VERSION "dbc-export 1 2026.26.6.5"

NS_ :

BS_:

BU_: APP APS BMS CC CMP CMPD CP DAS DI DIF DIR EPBL EPBR EVSE FC GTW HCML HCMR HVP ICR PCS PCS2 PLG PM PMF PMR PTC SCCM SCM SCS SDCR TAS UMC V2G VC VCBATT VCBATT0 VCBATT1 VCBATT2 VCFRONT VCFRONT1 VCFRONT2 VCLEFT VCRIGHT VCSEAT2L VCSEAT2R VCSEC

BO_ 1000 EPBR_alertMatrix: 8 EPBR
 SG_ EPBR_matrixIndex M : 0|4@1+ (1,0) [0|15] "" Vector__XXX
 SG_ EPBR_a001_WatchdogReset m0 : 4|1@1+ (1,0) [0|1] "" Vector__XXX
 SG_ EPBR_a002_PowerLossReset m0 : 5|1@1+ (1,0) [0|1] "" Vector__XXX
 SG_ EPBR_a003_SWAssertion m0 : 6|1@1+ (1,0) [0|1] "" Vector__XXX
 SG_ EPBR_a005_CANTXError m0 : 8|1@1+ (1,0) [0|1] "" Vector__XXX
 SG_ EPBR_a006_CANTX_cyclicError m0 : 9|1@1+ (1,0) [0|1] "" Vector__XXX
 SG_ EPBR_a012_CPUReset m0 : 15|1@1+ (1,0) [0|1] "" Vector__XXX
 SG_ EPBR_a013_AlertManagerFault m0 : 16|1@1+ (1,0) [0|1] "" Vector__XXX
 SG_ EPBR_a015_NVMMError m0 : 18|1@1+ (1,0) [0|1] "" Vector__XXX
 SG_ EPBR_a016_NVMMRecordError m0 : 19|1@1+ (1,0) [0|1] "" Vector__XXX
 SG_ EPBR_a021_TaskSchedulerError m0 : 24|1@1+ (1,0) [0|1] "" Vector__XXX
 SG_ EPBR_a022_TaskInitError m0 : 25|1@1+ (1,0) [0|1] "" Vector__XXX
 SG_ EPBR_a029_CoreDump m0 : 32|1@1+ (1,0) [0|1] "" Vector__XXX
 SG_ EPBR_a030_ECULogUploadRequest m0 : 33|1@1+ (1,0) [0|1] "" Vector__XXX
 SG_ EPBR_a031_UDSActive m0 : 34|1@1+ (1,0) [0|1] "" Vector__XXX
 SG_ EPBR_a041_HighCPULoad m0 : 44|1@1+ (1,0) [0|1] "" Vector__XXX
 SG_ EPBR_a042_HighStackUsage m0 : 45|1@1+ (1,0) [0|1] "" Vector__XXX
 SG_ EPBR_a043_Task1msError m0 : 46|1@1+ (1,0) [0|1] "" Vector__XXX
 SG_ EPBR_a044_Task10msError m0 : 47|1@1+ (1,0) [0|1] "" Vector__XXX
 SG_ EPBR_a045_Task100msError m0 : 48|1@1+ (1,0) [0|1] "" Vector__XXX
 SG_ EPBR_a046_Task1000msError m0 : 49|1@1+ (1,0) [0|1] "" Vector__XXX
 SG_ EPBR_a057_HVP_MIA m0 : 60|1@1+ (1,0) [0|1] "" Vector__XXX
 SG_ EPBR_a058_inputRHighSyncDebug m0 : 61|1@1+ (1,0) [0|1] "" Vector__XXX
 SG_ EPBR_a059_inputResistanceHigh m0 : 62|1@1+ (1,0) [0|1] "" Vector__XXX
 SG_ EPBR_a060_engineeringBuild m0 : 63|1@1+ (1,0) [0|1] "" Vector__XXX
 SG_ EPBR_a061_XCPConnected m1 : 4|1@1+ (1,0) [0|1] "" Vector__XXX
 SG_ EPBR_a062_XCPWasConnected m1 : 5|1@1+ (1,0) [0|1] "" Vector__XXX
 SG_ EPBR_a063_SwitchFault m1 : 6|1@1+ (1,0) [0|1] "" Vector__XXX
 SG_ EPBR_a064_busSleepReqTimeout m1 : 7|1@1+ (1,0) [0|1] "" Vector__XXX
 SG_ EPBR_a081_APP_MIA m1 : 24|1@1+ (1,0) [0|1] "" Vector__XXX
 SG_ EPBR_a082_VCRIGHT_IPC_MIA m1 : 25|1@1+ (1,0) [0|1] "" Vector__XXX
 SG_ EPBR_a083_VCLEFT_IPC_MIA m1 : 26|1@1+ (1,0) [0|1] "" Vector__XXX
 SG_ EPBR_a084_TPMS_MIA m1 : 27|1@1+ (1,0) [0|1] "" Vector__XXX
 SG_ EPBR_a085_CCCM_MIA m1 : 28|1@1+ (1,0) [0|1] "" Vector__XXX
 SG_ EPBR_a086_VCBATT_MIA m1 : 29|1@1+ (1,0) [0|1] "" Vector__XXX
 SG_ EPBR_a087_DIREL_MIA m1 : 30|1@1+ (1,0) [0|1] "" Vector__XXX
 SG_ EPBR_a088_DIRER_MIA m1 : 31|1@1+ (1,0) [0|1] "" Vector__XXX
 SG_ EPBR_a089_IBST_MIA m1 : 32|1@1+ (1,0) [0|1] "" Vector__XXX
 SG_ EPBR_a090_APS_MIA m1 : 33|1@1+ (1,0) [0|1] "" Vector__XXX
 SG_ EPBR_a091_CMPD_MIA m1 : 34|1@1+ (1,0) [0|1] "" Vector__XXX
 SG_ EPBR_a092_VCSEATD_MIA m1 : 35|1@1+ (1,0) [0|1] "" Vector__XXX
 SG_ EPBR_a093_VCSEATP_MIA m1 : 36|1@1+ (1,0) [0|1] "" Vector__XXX
 SG_ EPBR_a094_EPAS3P_MIA m1 : 37|1@1+ (1,0) [0|1] "" Vector__XXX
 SG_ EPBR_a095_CHG_MIA m1 : 38|1@1+ (1,0) [0|1] "" Vector__XXX
 SG_ EPBR_a096_OCS1P_MIA m1 : 39|1@1+ (1,0) [0|1] "" Vector__XXX
 SG_ EPBR_a097_CMP_MIA m1 : 40|1@1+ (1,0) [0|1] "" Vector__XXX
 SG_ EPBR_a098_DIR_MIA m1 : 41|1@1+ (1,0) [0|1] "" Vector__XXX
 SG_ EPBR_a099_PARK_MIA m1 : 42|1@1+ (1,0) [0|1] "" Vector__XXX
 SG_ EPBR_a100_CANbus_MIA m1 : 43|1@1+ (1,0) [0|1] "" Vector__XXX
 SG_ EPBR_a101_PM_MIA m1 : 44|1@1+ (1,0) [0|1] "" Vector__XXX
 SG_ EPBR_a102_PTC_MIA m1 : 45|1@1+ (1,0) [0|1] "" Vector__XXX
 SG_ EPBR_a103_CP_MIA m1 : 46|1@1+ (1,0) [0|1] "" Vector__XXX
 SG_ EPBR_a104_DAS_MIA m1 : 47|1@1+ (1,0) [0|1] "" Vector__XXX
 SG_ EPBR_a105_TAS_MIA m1 : 48|1@1+ (1,0) [0|1] "" Vector__XXX
 SG_ EPBR_a106_PCS_MIA m1 : 49|1@1+ (1,0) [0|1] "" Vector__XXX
 SG_ EPBR_a107_BMS_MIA m1 : 50|1@1+ (1,0) [0|1] "" Vector__XXX
 SG_ EPBR_a108_DIF_MIA m1 : 51|1@1+ (1,0) [0|1] "" Vector__XXX
 SG_ EPBR_a109_RCM_MIA m1 : 52|1@1+ (1,0) [0|1] "" Vector__XXX
 SG_ EPBR_a110_GTW_MIA m1 : 53|1@1+ (1,0) [0|1] "" Vector__XXX
 SG_ EPBR_a111_EPBR_MIA m1 : 54|1@1+ (1,0) [0|1] "" Vector__XXX
 SG_ EPBR_a112_EPBL_MIA m1 : 55|1@1+ (1,0) [0|1] "" Vector__XXX
 SG_ EPBR_a113_UI_MIA m1 : 56|1@1+ (1,0) [0|1] "" Vector__XXX
 SG_ EPBR_a114_ESP_MIA m1 : 57|1@1+ (1,0) [0|1] "" Vector__XXX
 SG_ EPBR_a115_VCSEC_MIA m1 : 58|1@1+ (1,0) [0|1] "" Vector__XXX
 SG_ EPBR_a116_VCRIGHT_MIA m1 : 59|1@1+ (1,0) [0|1] "" Vector__XXX
 SG_ EPBR_a117_VCLEFT_MIA m1 : 60|1@1+ (1,0) [0|1] "" Vector__XXX
 SG_ EPBR_a118_VCFRONT_MIA m1 : 61|1@1+ (1,0) [0|1] "" Vector__XXX
 SG_ EPBR_a119_SCCM_MIA m1 : 62|1@1+ (1,0) [0|1] "" Vector__XXX
 SG_ EPBR_a120_DI_DRIVE_MIA m1 : 63|1@1+ (1,0) [0|1] "" Vector__XXX
 SG_ EPBR_a121_nDriveFault m2 : 4|1@1+ (1,0) [0|1] "" Vector__XXX
 SG_ EPBR_a122_Oc m2 : 5|1@1+ (1,0) [0|1] "" Vector__XXX
 SG_ EPBR_a123_Uc m2 : 6|1@1+ (1,0) [0|1] "" Vector__XXX
 SG_ EPBR_a124_calOutOfBounds m2 : 7|1@1+ (1,0) [0|1] "" Vector__XXX
 SG_ EPBR_a125_IdleVMismatch m2 : 8|1@1+ (1,0) [0|1] "" Vector__XXX
 SG_ EPBR_a126_MotorNVoltLow m2 : 9|1@1+ (1,0) [0|1] "" Vector__XXX
 SG_ EPBR_a127_MotorNVoltHigh m2 : 10|1@1+ (1,0) [0|1] "" Vector__XXX
 SG_ EPBR_a128_MotorPVoltHigh m2 : 11|1@1+ (1,0) [0|1] "" Vector__XXX
 SG_ EPBR_a129_ICR_MIA m2 : 12|1@1+ (1,0) [0|1] "" Vector__XXX
 SG_ EPBR_a130_BB_MIA m2 : 13|1@1+ (1,0) [0|1] "" Vector__XXX
 SG_ EPBR_a131_RCU_MIA m2 : 14|1@1+ (1,0) [0|1] "" Vector__XXX
 SG_ EPBR_a132_VCBATT1_MIA m2 : 15|1@1+ (1,0) [0|1] "" Vector__XXX
 SG_ EPBR_a133_VCBATT2_MIA m2 : 16|1@1+ (1,0) [0|1] "" Vector__XXX
 SG_ EPBR_a134_NvOv m2 : 17|1@1+ (1,0) [0|1] "" Vector__XXX
 SG_ EPBR_a135_NvUv m2 : 18|1@1+ (1,0) [0|1] "" Vector__XXX
 SG_ EPBR_a136_PvOv m2 : 19|1@1+ (1,0) [0|1] "" Vector__XXX
 SG_ EPBR_a137_PvUv m2 : 20|1@1+ (1,0) [0|1] "" Vector__XXX
 SG_ EPBR_a138_NvmDualFailure m2 : 21|1@1+ (1,0) [0|1] "" Vector__XXX
 SG_ EPBR_a139_NvmRedundancyLoss m2 : 22|1@1+ (1,0) [0|1] "" Vector__XXX
 SG_ EPBR_a140_NvmSlowWrite m2 : 23|1@1+ (1,0) [0|1] "" Vector__XXX
 SG_ EPBR_a141_invalidState m2 : 24|1@1+ (1,0) [0|1] "" Vector__XXX
 SG_ EPBR_a170_12vOv m2 : 53|1@1+ (1,0) [0|1] "" Vector__XXX
 SG_ EPBR_a171_12vUv m2 : 54|1@1+ (1,0) [0|1] "" Vector__XXX
 SG_ EPBR_a172_SPI_MIA m2 : 55|1@1+ (1,0) [0|1] "" Vector__XXX
 SG_ EPBR_a173_hiCurrentMissing m2 : 56|1@1+ (1,0) [0|1] "" Vector__XXX
 SG_ EPBR_a174_csmReleaseFailed m2 : 57|1@1+ (1,0) [0|1] "" Vector__XXX
 SG_ EPBR_a175_csmReleaseRetry m2 : 58|1@1+ (1,0) [0|1] "" Vector__XXX
 SG_ EPBR_a176_csmApplyFailed m2 : 59|1@1+ (1,0) [0|1] "" Vector__XXX
 SG_ EPBR_a177_csmApplyRetry m2 : 60|1@1+ (1,0) [0|1] "" Vector__XXX
 SG_ EPBR_a178_caliperStateUnknown m2 : 61|1@1+ (1,0) [0|1] "" Vector__XXX
 SG_ EPBR_a179_epbProblem m2 : 62|1@1+ (1,0) [0|1] "" Vector__XXX
 SG_ EPBR_a180_dynamicActive m2 : 63|1@1+ (1,0) [0|1] "" Vector__XXX
 SG_ EPBR_a181_TooSteepGradeToPark m3 : 4|1@1+ (1,0) [0|1] "" Vector__XXX
 SG_ EPBR_a182_OneEPBAppliedUnsecEnv m3 : 5|1@1+ (1,0) [0|1] "" Vector__XXX
 SG_ EPBR_a183_cdpNotAvailable m3 : 6|1@1+ (1,0) [0|1] "" Vector__XXX
 SG_ EPBR_a184_dynamicParkAbort m3 : 7|1@1+ (1,0) [0|1] "" Vector__XXX
 SG_ EPBR_a185_summonAborted m3 : 8|1@1+ (1,0) [0|1] "" Vector__XXX
 SG_ EPBR_a186_externalParkAbort m3 : 9|1@1+ (1,0) [0|1] "" Vector__XXX
 SG_ EPBR_a187_cdpDynamic m3 : 10|1@1+ (1,0) [0|1] "" Vector__XXX
 SG_ EPBR_a188_epbDynamic m3 : 11|1@1+ (1,0) [0|1] "" Vector__XXX
 SG_ EPBR_a189_epbDynamicParkCanceled m3 : 12|1@1+ (1,0) [0|1] "" Vector__XXX
 SG_ EPBR_a190_csmApplyDegraded m3 : 13|1@1+ (1,0) [0|1] "" Vector__XXX
 SG_ EPBR_a191_csmReleaseDegraded m3 : 14|1@1+ (1,0) [0|1] "" Vector__XXX
 SG_ EPBR_a195_parkForDriverIsLeaving m3 : 18|1@1+ (1,0) [0|1] "" Vector__XXX
 SG_ EPBR_a196_freeRollModeActive m3 : 19|1@1+ (1,0) [0|1] "" Vector__XXX
 SG_ EPBR_a197_freeRollModeAtSpeed m3 : 20|1@1+ (1,0) [0|1] "" Vector__XXX
 SG_ EPBR_a198_holdClampComplete m3 : 21|1@1+ (1,0) [0|1] "" Vector__XXX
 SG_ EPBR_a200_PmUnparkNotAllowed m3 : 23|1@1+ (1,0) [0|1] "" Vector__XXX
 SG_ EPBR_a202_remoteEpbConfigIncompa m3 : 25|1@1+ (1,0) [0|1] "" Vector__XXX
 SG_ EPBR_a203_hwBrakeTypeMismatch m3 : 26|1@1+ (1,0) [0|1] "" Vector__XXX
 SG_ EPBR_a210_parkForDriverIsLeaving m3 : 33|1@1+ (1,0) [0|1] "" Vector__XXX
 SG_ EPBR_a216_SPI_MIA_debugData1 m3 : 39|1@1+ (1,0) [0|1] "" Vector__XXX
 SG_ EPBR_a217_SPI_MIA_debugData2 m3 : 40|1@1+ (1,0) [0|1] "" Vector__XXX
 SG_ EPBR_a225_epbActiveDecel m3 : 48|1@1+ (1,0) [0|1] "" Vector__XXX
 SG_ EPBR_a241_diOutputLocked m4 : 4|1@1+ (1,0) [0|1] "" Vector__XXX
 SG_ EPBR_a242_hvOutputLocked m4 : 5|1@1+ (1,0) [0|1] "" Vector__XXX
 SG_ EPBR_a243_bdwUnavailable m4 : 6|1@1+ (1,0) [0|1] "" Vector__XXX
 SG_ EPBR_a244_WinchModeActive m4 : 7|1@1+ (1,0) [0|1] "" Vector__XXX
 SG_ EPBR_a245_serviceModeActive m4 : 8|1@1+ (1,0) [0|1] "" Vector__XXX
 SG_ EPBR_a246_idleFaultApply m4 : 9|1@1+ (1,0) [0|1] "" Vector__XXX
 SG_ EPBR_a247_csmDynamicApplyRetry m4 : 10|1@1+ (1,0) [0|1] "" Vector__XXX
 SG_ EPBR_a248_csmDynamicApplyFailed m4 : 11|1@1+ (1,0) [0|1] "" Vector__XXX
 SG_ EPBR_a249_idleFaultRelease m4 : 12|1@1+ (1,0) [0|1] "" Vector__XXX
 SG_ EPBR_a250_WinchModeCanceled m4 : 13|1@1+ (1,0) [0|1] "" Vector__XXX
 SG_ EPBR_a251_currentVarianceHigh m4 : 14|1@1+ (1,0) [0|1] "" Vector__XXX
 SG_ EPBR_a252_winchModePending m4 : 15|1@1+ (1,0) [0|1] "" Vector__XXX
 SG_ EPBR_a253_esmReleaseBlocked m4 : 16|1@1+ (1,0) [0|1] "" Vector__XXX
 SG_ EPBR_a254_showStalkParkButtonFau m4 : 17|1@1+ (1,0) [0|1] "" Vector__XXX
 SG_ EPBR_a256_epbSystemApply m4 : 19|1@1+ (1,0) [0|1] "" Vector__XXX
 SG_ EPBR_a261_winchModeWithoutSteeri m4 : 24|1@1+ (1,0) [0|1] "" Vector__XXX
 SG_ EPBR_a262_cannotPrepareWinchMode m4 : 25|1@1+ (1,0) [0|1] "" Vector__XXX
 SG_ EPBR_a263_epbRecoveryPark m4 : 26|1@1+ (1,0) [0|1] "" Vector__XXX
 SG_ EPBR_a264_winchModeDeactivated m4 : 27|1@1+ (1,0) [0|1] "" Vector__XXX
 SG_ EPBR_a272_vhclPwrStateMsmtch m4 : 35|1@1+ (1,0) [0|1] "" Vector__XXX
 SG_ EPBR_a300_leftRightConfusion m4 : 63|1@1+ (1,0) [0|1] "" Vector__XXX
 SG_ EPBR_a301_oocSpeedViolation m5 : 4|1@1+ (1,0) [0|1] "" Vector__XXX
 SG_ EPBR_a302_csmLongRelease m5 : 5|1@1+ (1,0) [0|1] "" Vector__XXX
 SG_ EPBR_a303_clampingOccuredEarly m5 : 6|1@1+ (1,0) [0|1] "" Vector__XXX
 SG_ EPBR_a304_rearSeatControllerEFus m5 : 7|1@1+ (1,0) [0|1] "" Vector__XXX
 SG_ EPBR_a305_premiumAmpEFuseTrip m5 : 8|1@1+ (1,0) [0|1] "" Vector__XXX
 SG_ EPBR_a330_parkForApIsLeaving m5 : 33|1@1+ (1,0) [0|1] "" Vector__XXX
 SG_ EPBR_a350_ensOutOfRange m5 : 53|1@1+ (1,0) [0|1] "" Vector__XXX
 SG_ EPBR_a352_audioCurrentSpikeData m5 : 55|1@1+ (1,0) [0|1] "" Vector__XXX
 SG_ EPBR_a353_missingSpeedUnableToPa m5 : 56|1@1+ (1,0) [0|1] "" Vector__XXX
 SG_ EPBR_a354_parkedForLowBrakeFluid m5 : 57|1@1+ (1,0) [0|1] "" Vector__XXX
 SG_ EPBR_a355_brakeHwAndEpbHwMismatc m5 : 58|1@1+ (1,0) [0|1] "" Vector__XXX
 SG_ EPBR_a356_parkingForStationaryDe m5 : 59|1@1+ (1,0) [0|1] "" Vector__XXX
 SG_ EPBR_a357_brakesTooHotForSlope m5 : 60|1@1+ (1,0) [0|1] "" Vector__XXX
 SG_ EPBR_a358_brakesTooHotForSlopeWi m5 : 61|1@1+ (1,0) [0|1] "" Vector__XXX
 SG_ EPBR_a359_seat2RControllerTrip m5 : 62|1@1+ (1,0) [0|1] "" Vector__XXX
 SG_ EPBR_a360_ibstBrakeSwitchInvalid m5 : 63|1@1+ (1,0) [0|1] "" Vector__XXX
 SG_ EPBR_a361_espBrakeSwitchInvalid m6 : 4|1@1+ (1,0) [0|1] "" Vector__XXX
 SG_ EPBR_a362_ibstPressedEspNotPress m6 : 5|1@1+ (1,0) [0|1] "" Vector__XXX
 SG_ EPBR_a363_ibstNotPressedEspPress m6 : 6|1@1+ (1,0) [0|1] "" Vector__XXX
 SG_ EPBR_a364_espMasterCylCompOverTh m6 : 7|1@1+ (1,0) [0|1] "" Vector__XXX
 SG_ EPBR_a365_TooSteepToParkWithTrai m6 : 8|1@1+ (1,0) [0|1] "" Vector__XXX
 SG_ EPBR_a366_TooSteepToParkWithTrai m6 : 9|1@1+ (1,0) [0|1] "" Vector__XXX
 SG_ EPBR_a370_imposterDetected m6 : 13|1@1+ (1,0) [0|1] "" Vector__XXX

BO_ 2024 EPBR_info: 8 EPBR
 SG_ EPBR_infoIndex M : 0|8@1+ (1,0) [0|255] "" Vector__XXX
 SG_ EPBR_infoBuildType m10 : 8|3@1+ (1,0) [0|7] "" Vector__XXX
 SG_ EPBR_infoBuildConfigId m10 : 16|16@1+ (1,0) [0|65535] "" Vector__XXX
 SG_ EPBR_infoHardwareId m10 : 32|16@1+ (1,0) [0|65535] "" Vector__XXX
 SG_ EPBR_infoComponentId m10 : 48|16@1+ (1,0) [0|65535] "" Vector__XXX
 SG_ EPBR_infoPcbaId m11 : 8|8@1+ (1,0) [0|255] "" Vector__XXX
 SG_ EPBR_infoAssemblyId m11 : 16|8@1+ (1,0) [0|254] "" Vector__XXX
 SG_ EPBR_infoUsageId m11 : 24|16@1+ (1,0) [0|65535] "" Vector__XXX
 SG_ EPBR_infoSubUsageId m11 : 40|16@1+ (1,0) [0|65535] "" Vector__XXX
 SG_ EPBR_infoAppCrc m13 : 8|32@1+ (1,0) [0|4294967295] "" Vector__XXX
 SG_ EPBR_infoAppGitHash m17 : 8|56@1+ (1,0) [0|7.20575940379e+16] "" Vector__XXX
 SG_ EPBR_infoBootGitHash m18 : 8|56@1+ (1,0) [0|7.20575940379e+16] "" Vector__XXX
 SG_ EPBR_infoPlatformType m19 : 8|8@1+ (1,0) [0|255] "" Vector__XXX
 SG_ EPBR_infoBootUdsProtoVersion m20 : 8|16@1+ (1,0) [0|65535] "" Vector__XXX
 SG_ EPBR_infoBootCrc m20 : 24|32@1+ (1,0) [0|4294967295] "" Vector__XXX

BO_ 552 EPBR_internalStatus: 8 EPBR
 SG_ EPBR_unitStatus : 0|5@1+ (1,0) [0|31] "" Vector__XXX
 SG_ EPBR_unitFaultStatus : 5|2@1+ (1,0) [0|3] "" Vector__XXX
 SG_ EPBR_summonState : 8|3@1+ (1,0) [0|7] "" Vector__XXX
 SG_ EPBR_disconnected : 11|1@1+ (1,0) [0|1] "" Vector__XXX
 SG_ EPBR_pistonTouchingRotor : 12|1@1+ (1,0) [0|1] "" Vector__XXX
 SG_ EPBR_csmFaultReason : 13|5@1+ (1,0) [0|31] "" Vector__XXX
 SG_ EPBR_esmOperationTrigger : 18|6@1+ (1,0) [0|63] "" Vector__XXX
 SG_ EPBR_summonFaultReason : 24|5@1+ (1,0) [0|31] "" Vector__XXX
 SG_ EPBR_localServiceModeActive : 29|1@1+ (1,0) [0|1] "" Vector__XXX
 SG_ EPBR_localCdpState : 30|2@1+ (1,0) [0|3] "" Vector__XXX
 SG_ EPBR_chimeRequestLocal : 33|3@1+ (1,0) [0|7] "" Vector__XXX
 SG_ EPBR_telltaleLocal : 39|3@1+ (1,0) [0|6] "" Vector__XXX
 SG_ EPBR_driverIsLeavingLocal : 42|1@1+ (1,0) [0|1] "" Vector__XXX
 SG_ EPBR_driverIsLeavingAnySpeedLoca : 43|1@1+ (1,0) [0|1] "" Vector__XXX
 SG_ EPBR_internalCDPRequest : 44|1@1+ (1,0) [0|1] "" Vector__XXX
 SG_ EPBR_esmSpeedClass : 45|3@1+ (1,0) [0|7] "" Vector__XXX
 SG_ EPBR_learnedEpbConfig : 48|4@1+ (1,0) [0|15] "" Vector__XXX
 SG_ EPBR_internalStatusCounter : 52|4@1+ (1,0) [0|15] "" Vector__XXX
 SG_ EPBR_internalStatusChecksum : 56|8@1+ (1,0) [0|255] "" Vector__XXX

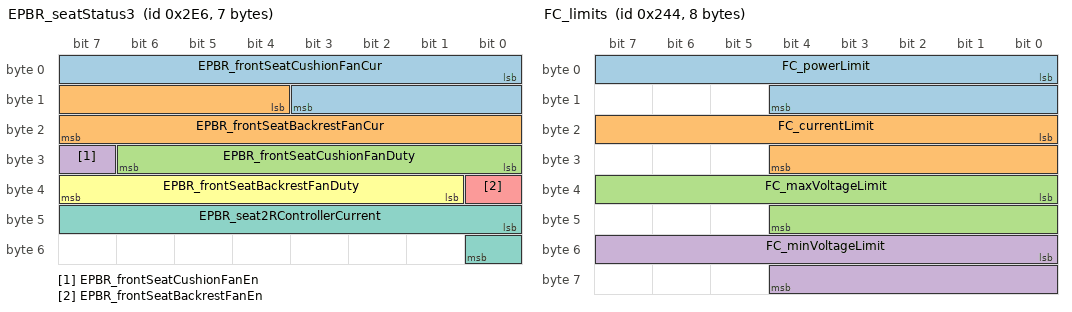
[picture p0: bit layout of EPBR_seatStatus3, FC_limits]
BO_ 742 EPBR_seatStatus3: 7 EPBR
 SG_ EPBR_frontSeatCushionFanCur : 0|12@1+ (0.01,0) [0|40.95] "A" Vector__XXX
 SG_ EPBR_frontSeatBackrestFanCur : 12|12@1+ (0.01,0) [0|40.95] "A" Vector__XXX
 SG_ EPBR_frontSeatCushionFanDuty : 24|7@1+ (1,0) [0|100] "%" Vector__XXX
 SG_ EPBR_frontSeatCushionFanEn : 31|1@1+ (1,0) [0|1] "" Vector__XXX
 SG_ EPBR_frontSeatBackrestFanEn : 32|1@1+ (1,0) [0|1] "" Vector__XXX
 SG_ EPBR_frontSeatBackrestFanDuty : 33|7@1+ (1,0) [0|100] "%" Vector__XXX
 SG_ EPBR_seat2RControllerCurrent : 40|9@1+ (0.2,0) [0|102] "A" Vector__XXX

BO_ 744 EPBR_status: 8 EPBR
 SG_ EPBR_systemStatus : 0|4@1+ (1,0) [0|15] "" Vector__XXX
 SG_ EPBR_freeRollModeStatus : 4|2@1+ (1,0) [0|3] "" Vector__XXX
 SG_ EPBR_driverIsLeaving : 6|1@1+ (1,0) [0|1] "" Vector__XXX
 SG_ EPBR_driverIsLeavingAnySpeed : 7|1@1+ (1,0) [0|1] "" Vector__XXX
 SG_ EPBR_systemCdpAvailable : 8|1@1+ (1,0) [0|1] "" Vector__XXX
 SG_ EPBR_chimeRequest : 9|3@1+ (1,0) [0|7] "" Vector__XXX
 SG_ EPBR_telltale : 12|3@1+ (1,0) [0|6] "" Vector__XXX
 SG_ EPBR_audioCurrentSpikeDetected : 15|1@1+ (1,0) [0|1] "" Vector__XXX
 SG_ EPBR_redundantBrakingEnabled : 16|1@1+ (1,0) [0|1] "" Vector__XXX
 SG_ EPBR_summonEnabled : 17|1@1+ (1,0) [0|1] "" Vector__XXX
 SG_ EPBR_brakeLight : 18|1@1+ (1,0) [0|1] "" Vector__XXX
 SG_ EPBR_epbConfigMismatch : 19|1@1+ (1,0) [0|1] "" Vector__XXX
 SG_ EPBR_brakeConfirmedPressed : 20|1@1+ (1,0) [0|1] "" Vector__XXX
 SG_ EPBR_requestUserConfirmation : 21|1@1+ (1,0) [0|1] "" Vector__XXX
 SG_ EPBR_uiWinchModeMiscBlocking : 22|1@1+ (1,0) [0|1] "" Vector__XXX
 SG_ EPBR_winchModeActive : 23|1@1+ (1,0) [0|1] "" Vector__XXX
 SG_ EPBR_updateMode : 24|1@1+ (1,0) [0|1] "" Vector__XXX
 SG_ EPBR_winchModePermissive : 25|1@1+ (1,0) [0|1] "" Vector__XXX
 SG_ EPBR_winchModePending : 26|1@1+ (1,0) [0|1] "" Vector__XXX
 SG_ EPBR_cdpRequest : 27|1@1+ (1,0) [0|1] "" Vector__XXX
 SG_ EPBR_uiParkAvailable : 28|2@1+ (1,0) [0|3] "" Vector__XXX
 SG_ EPBR_brakeDiscWipeRequest : 30|2@1+ (1,0) [0|2] "" Vector__XXX
 SG_ EPBR_showUiGearShifter : 32|1@1+ (1,0) [0|1] "" Vector__XXX
 SG_ EPBR_uiWinchModeLvStatus : 33|2@1+ (1,0) [0|3] "" Vector__XXX
 SG_ EPBR_contactorCycleNotNeededForW : 35|1@1+ (1,0) [0|1] "" Vector__XXX
 SG_ EPBR_autonomyBehavior : 43|2@1+ (1,0) [0|3] "" Vector__XXX
 SG_ EPBR_showStalkFaultedOnUi : 45|1@1+ (1,0) [0|1] "" Vector__XXX
 SG_ EPBR_espPowerRequest : 46|1@1+ (1,0) [0|1] "" Vector__XXX
 SG_ EPBR_okToPark : 47|1@1+ (1,0) [0|1] "" Vector__XXX
 SG_ EPBR_hornRequest : 48|1@1+ (1,0) [0|1] "" Vector__XXX
 SG_ EPBR_winchModeAvailable : 49|1@1+ (1,0) [0|1] "" Vector__XXX
 SG_ EPBR_bothDisconnected : 50|1@1+ (1,0) [0|1] "" Vector__XXX
 SG_ EPBR_blockDrive : 51|1@1+ (1,0) [0|1] "" Vector__XXX
 SG_ EPBR_statusCounter : 52|4@1+ (1,0) [0|15] "" Vector__XXX
 SG_ EPBR_statusChecksum : 56|8@1+ (1,0) [0|255] "" Vector__XXX

BO_ 1575 EPBR_udsResponse: 8 EPBR
 SG_ EPBR_udsResponseData_H : 7|32@0+ (1,0) [0|4294967295] "" Vector__XXX
 SG_ EPBR_udsResponseData_L : 39|32@0+ (1,0) [0|4294967295] "" Vector__XXX

BO_ 1662 EVSE_isoTpToVeh: 8 EVSE
 SG_ EVSE_isoTpToVehData : 0|64@1+ (1,0) [0|1.84467440737e+19] "" Vector__XXX

BO_ 1322 FC_alertLog: 8 FC
 SG_ FC_alertID M : 0|15@1+ (1,0) [0|32767] "" Vector__XXX
 SG_ FC_alertType : 15|1@1+ (1,0) [0|1] "" Vector__XXX
 SG_ FC_a130_CA_flybackSwOvType m130 : 16|1@1+ (1,0) [0|1] "" Vector__XXX
 SG_ FC_a146_CA_flybackOnTime m146 : 16|16@1+ (0.0007629511,0) [0|50.0000003385] "uS" Vector__XXX
 SG_ FC_a146_CA_flybackV m146 : 32|16@1+ (0.0128332730383,0) [0|841.028548565] "V" Vector__XXX
 SG_ FC_a146_CA_flybackTargetV m146 : 48|16@1+ (0.0128332730383,0) [0|841.028548565] "V" Vector__XXX
 SG_ FC_a159_CA_wdtTaskList1 m159 : 16|16@1+ (1,0) [0|65535] "" Vector__XXX
 SG_ FC_a159_CA_wdtTaskList2 m159 : 32|16@1+ (1,0) [0|65535] "" Vector__XXX

BO_ 895 FC_alertMatrix3: 8 FC
 SG_ FC_a129_CA_flyback_HW_OC : 0|1@1+ (1,0) [0|1] "" Vector__XXX
 SG_ FC_a130_CA_flyback_SW_OV : 1|1@1+ (1,0) [0|1] "" Vector__XXX
 SG_ FC_a131_CA_flyback_HW_OV : 2|1@1+ (1,0) [0|1] "" Vector__XXX
 SG_ FC_a132_CA_bmsMia : 3|1@1+ (1,0) [0|1] "" Vector__XXX
 SG_ FC_a133_CA_evseMia : 4|1@1+ (1,0) [0|1] "" Vector__XXX
 SG_ FC_a134_CA_vehTxBufOvf : 5|1@1+ (1,0) [0|1] "" Vector__XXX
 SG_ FC_a135_CA_vehRxBufOvf : 6|1@1+ (1,0) [0|1] "" Vector__XXX
 SG_ FC_a136_CA_evseTxBufOvf : 7|1@1+ (1,0) [0|1] "" Vector__XXX
 SG_ FC_a137_CA_evseRxBufOvf : 8|1@1+ (1,0) [0|1] "" Vector__XXX
 SG_ FC_a138_CA_hwProxTrip : 9|1@1+ (1,0) [0|1] "" Vector__XXX
 SG_ FC_a139_CA_ss2NotLow : 10|1@1+ (1,0) [0|1] "" Vector__XXX
 SG_ FC_a140_CA_bmsIncompatible : 11|1@1+ (1,0) [0|1] "" Vector__XXX
 SG_ FC_a141_CA_vehConn_OT : 12|1@1+ (1,0) [0|1] "" Vector__XXX
 SG_ FC_a142_CA_evseConn_OT : 13|1@1+ (1,0) [0|1] "" Vector__XXX
 SG_ FC_a143_CA_pcb_OT : 14|1@1+ (1,0) [0|1] "" Vector__XXX
 SG_ FC_a144_CA_flybackUnstable : 15|1@1+ (1,0) [0|1] "" Vector__XXX
 SG_ FC_a145_CA_flybackDataStale : 16|1@1+ (1,0) [0|1] "" Vector__XXX
 SG_ FC_a146_CA_flybackBusLoadHi : 17|1@1+ (1,0) [0|1] "" Vector__XXX
 SG_ FC_a147_CA_vehConn_UT : 18|1@1+ (1,0) [0|1] "" Vector__XXX
 SG_ FC_a148_CA_evseConn_UT : 19|1@1+ (1,0) [0|1] "" Vector__XXX
 SG_ FC_a149_CA_pcb_UT : 20|1@1+ (1,0) [0|1] "" Vector__XXX
 SG_ FC_a150_CA_vehToEvseDeltaHi : 21|1@1+ (1,0) [0|1] "" Vector__XXX
 SG_ FC_a151_CA_vehToEvseDeltaLo : 22|1@1+ (1,0) [0|1] "" Vector__XXX
 SG_ FC_a152_CA_vehToPcbDeltaHi : 23|1@1+ (1,0) [0|1] "" Vector__XXX
 SG_ FC_a153_CA_evseToPcbDeltaHi : 24|1@1+ (1,0) [0|1] "" Vector__XXX
 SG_ FC_a154_CA_vehToPcbDeltaLo : 25|1@1+ (1,0) [0|1] "" Vector__XXX
 SG_ FC_a155_CA_evseToPcbDeltaLo : 26|1@1+ (1,0) [0|1] "" Vector__XXX
 SG_ FC_a156_CA_flybackRunTimeout : 27|1@1+ (1,0) [0|1] "" Vector__XXX
 SG_ FC_a157_CA_unused : 28|1@1+ (1,0) [0|1] "" Vector__XXX
 SG_ FC_a158_CA_evseOverCurrent : 29|1@1+ (1,0) [0|1] "" Vector__XXX
 SG_ FC_a159_CA_wdtExpired : 30|1@1+ (1,0) [0|1] "" Vector__XXX
 SG_ FC_a160_CA_ss2Deasserted : 31|1@1+ (1,0) [0|1] "" Vector__XXX
 SG_ FC_a161_CA_vehTempHiFoldBk : 32|1@1+ (1,0) [0|1] "" Vector__XXX
 SG_ FC_a162_CA_evseTempHiFoldBk : 33|1@1+ (1,0) [0|1] "" Vector__XXX
 SG_ FC_a163_CA_pcbTempHiFoldBk : 34|1@1+ (1,0) [0|1] "" Vector__XXX
 SG_ FC_a164_CA_proxDisconnected : 35|1@1+ (1,0) [0|1] "" Vector__XXX
 SG_ FC_a165_CA_evseConnUnlocked : 36|1@1+ (1,0) [0|1] "" Vector__XXX
 SG_ FC_a166_CA_vehConnUnlocked : 37|1@1+ (1,0) [0|1] "" Vector__XXX
 SG_ FC_a167_CA_isoVoltageLow : 38|1@1+ (1,0) [0|1] "" Vector__XXX
 SG_ FC_a168_CA_proxTimeout : 39|1@1+ (1,0) [0|1] "" Vector__XXX
 SG_ FC_a169_CA_pilotAcceptTimeout : 40|1@1+ (1,0) [0|1] "" Vector__XXX
 SG_ FC_a170_CA_vehDataTimeout : 41|1@1+ (1,0) [0|1] "" Vector__XXX
 SG_ FC_a171_CA_vehConLockTimeout : 42|1@1+ (1,0) [0|1] "" Vector__XXX
 SG_ FC_a172_CA_ss2LowTimeout : 43|1@1+ (1,0) [0|1] "" Vector__XXX
 SG_ FC_a173_CA_evseDataTimeout : 44|1@1+ (1,0) [0|1] "" Vector__XXX
 SG_ FC_a174_CA_vehReadyTimeout : 45|1@1+ (1,0) [0|1] "" Vector__XXX
 SG_ FC_a175_CA_evseIsoTestTimeout : 46|1@1+ (1,0) [0|1] "" Vector__XXX
 SG_ FC_a176_CA_chargingBusTimeout : 47|1@1+ (1,0) [0|1] "" Vector__XXX
 SG_ FC_a177_CA_bmsCtrCloseTimeout : 48|1@1+ (1,0) [0|1] "" Vector__XXX
 SG_ FC_a178_CA_evseStartTimeout : 49|1@1+ (1,0) [0|1] "" Vector__XXX
 SG_ FC_a179_CA_startupProblem : 50|1@1+ (1,0) [0|1] "" Vector__XXX
 SG_ FC_a180_CA_chargingProblem : 51|1@1+ (1,0) [0|1] "" Vector__XXX
 SG_ FC_a181_CA_vRegBrownout : 52|1@1+ (1,0) [0|1] "" Vector__XXX
 SG_ FC_a182_CA_evseChrMalfunc : 53|1@1+ (1,0) [0|1] "" Vector__XXX
 SG_ FC_a183_CA_evseBatIncompat : 54|1@1+ (1,0) [0|1] "" Vector__XXX
 SG_ FC_a184_CA_evseBatMalfunc : 55|1@1+ (1,0) [0|1] "" Vector__XXX
 SG_ FC_a185_CA_vehReadyDeasserted : 56|1@1+ (1,0) [0|1] "" Vector__XXX
 SG_ FC_a186_CA_fcContOpenTimeout : 57|1@1+ (1,0) [0|1] "" Vector__XXX
 SG_ FC_a187_CA_evseConLockTimeout : 58|1@1+ (1,0) [0|1] "" Vector__XXX

BO_ 927 FC_alertMatrix4: 8 FC
 SG_ FC_a193_FCAlertPlaceholder : 0|1@1+ (1,0) [0|1] "" Vector__XXX

BO_ 958 FC_alertMatrix5: 8 FC
 SG_ FC_a257_GB_bmsMia : 0|1@1+ (1,0) [0|1] "" Vector__XXX
 SG_ FC_a258_GB_evseMia : 1|1@1+ (1,0) [0|1] "" Vector__XXX
 SG_ FC_a259_GB_vehTxBufOvf : 2|1@1+ (1,0) [0|1] "" Vector__XXX
 SG_ FC_a260_GB_vehRxBufOvf : 3|1@1+ (1,0) [0|1] "" Vector__XXX
 SG_ FC_a261_GB_evseTxBufOvf : 4|1@1+ (1,0) [0|1] "" Vector__XXX
 SG_ FC_a262_GB_evseRxBufOvf : 5|1@1+ (1,0) [0|1] "" Vector__XXX
 SG_ FC_a263_GB_hwProxTrip : 6|1@1+ (1,0) [0|1] "" Vector__XXX
 SG_ FC_a264_GB_timeoutCHM : 7|1@1+ (1,0) [0|1] "" Vector__XXX
 SG_ FC_a265_GB_bmsIncompatible : 8|1@1+ (1,0) [0|1] "" Vector__XXX
 SG_ FC_a266_GB_negPin_OT : 9|1@1+ (1,0) [0|1] "" Vector__XXX
 SG_ FC_a267_GB_posPin_OT : 10|1@1+ (1,0) [0|1] "" Vector__XXX
 SG_ FC_a268_GB_pcb_OT : 11|1@1+ (1,0) [0|1] "" Vector__XXX
 SG_ FC_a269_GB_timeoutCRM : 12|1@1+ (1,0) [0|1] "" Vector__XXX
 SG_ FC_a270_GB_timeoutCML : 13|1@1+ (1,0) [0|1] "" Vector__XXX
 SG_ FC_a271_GB_timeoutCRO : 14|1@1+ (1,0) [0|1] "" Vector__XXX
 SG_ FC_a272_GB_negToPosDeltaHi : 15|1@1+ (1,0) [0|1] "" Vector__XXX
 SG_ FC_a273_GB_negToPosDeltaLo : 16|1@1+ (1,0) [0|1] "" Vector__XXX
 SG_ FC_a274_GB_negToPcbDeltaHi : 17|1@1+ (1,0) [0|1] "" Vector__XXX
 SG_ FC_a275_GB_posToPcbDeltaHi : 18|1@1+ (1,0) [0|1] "" Vector__XXX
 SG_ FC_a276_GB_negToPcbDeltaLo : 19|1@1+ (1,0) [0|1] "" Vector__XXX
 SG_ FC_a277_GB_posToPcbDeltaLo : 20|1@1+ (1,0) [0|1] "" Vector__XXX
 SG_ FC_a278_GB_timeoutCCS : 21|1@1+ (1,0) [0|1] "" Vector__XXX
 SG_ FC_a279_GB_evseOverCurrent : 22|1@1+ (1,0) [0|1] "" Vector__XXX
 SG_ FC_a280_GB_retryLimitExceeded : 23|1@1+ (1,0) [0|1] "" Vector__XXX
 SG_ FC_a281_GB_evseOutOfService : 24|1@1+ (1,0) [0|1] "" Vector__XXX
 SG_ FC_a282_GB_negTempHiFoldBk : 25|1@1+ (1,0) [0|1] "" Vector__XXX
 SG_ FC_a283_GB_posTempHiFoldBk : 26|1@1+ (1,0) [0|1] "" Vector__XXX
 SG_ FC_a284_GB_pcbTempHiFoldBk : 27|1@1+ (1,0) [0|1] "" Vector__XXX
 SG_ FC_a285_GB_proxDisconnected : 28|1@1+ (1,0) [0|1] "" Vector__XXX
 SG_ FC_a286_GB_evseConnUnlocked : 29|1@1+ (1,0) [0|1] "" Vector__XXX
 SG_ FC_a287_GB_vehConnUnlocked : 30|1@1+ (1,0) [0|1] "" Vector__XXX
 SG_ FC_a288_GB_evseAbnormalStopReq : 31|1@1+ (1,0) [0|1] "" Vector__XXX
 SG_ FC_a289_GB_proxTimeout : 32|1@1+ (1,0) [0|1] "" Vector__XXX
 SG_ FC_a290_GB_pilotAcceptTimeout : 33|1@1+ (1,0) [0|1] "" Vector__XXX
 SG_ FC_a291_GB_vehDataTimeout : 34|1@1+ (1,0) [0|1] "" Vector__XXX
 SG_ FC_a292_GB_vehConLockTimeout : 35|1@1+ (1,0) [0|1] "" Vector__XXX
 SG_ FC_a293_GB_proxRationality : 36|1@1+ (1,0) [0|1] "" Vector__XXX
 SG_ FC_a294_GB_unused : 37|1@1+ (1,0) [0|1] "" Vector__XXX
 SG_ FC_a295_GB_pilotRationality : 38|1@1+ (1,0) [0|1] "" Vector__XXX
 SG_ FC_a296_GB_invalidPilotTransitio : 39|1@1+ (1,0) [0|1] "" Vector__XXX
 SG_ FC_a297_GB_unused : 40|1@1+ (1,0) [0|1] "" Vector__XXX
 SG_ FC_a298_GB_bmsCtrCloseTimeout : 41|1@1+ (1,0) [0|1] "" Vector__XXX
 SG_ FC_a299_GB_evseReadyTimeout : 42|1@1+ (1,0) [0|1] "" Vector__XXX
 SG_ FC_a300_GB_unused : 43|1@1+ (1,0) [0|1] "" Vector__XXX
 SG_ FC_a301_GB_unused : 44|1@1+ (1,0) [0|1] "" Vector__XXX
 SG_ FC_a302_GB_unused : 45|1@1+ (1,0) [0|1] "" Vector__XXX
 SG_ FC_a303_GB_negRecogTimeout : 46|1@1+ (1,0) [0|1] "" Vector__XXX
 SG_ FC_a304_GB_unused : 47|1@1+ (1,0) [0|1] "" Vector__XXX
 SG_ FC_a305_GB_posRecogTimeout : 48|1@1+ (1,0) [0|1] "" Vector__XXX
 SG_ FC_a306_GB_vehReadyDeasserted : 49|1@1+ (1,0) [0|1] "" Vector__XXX
 SG_ FC_a307_GB_fcContOpenTimeout : 50|1@1+ (1,0) [0|1] "" Vector__XXX
 SG_ FC_a308_GB_evseConLockTimeout : 51|1@1+ (1,0) [0|1] "" Vector__XXX
 SG_ FC_a309_GB_unused : 52|1@1+ (1,0) [0|1] "" Vector__XXX
 SG_ FC_a310_GB_unused : 53|1@1+ (1,0) [0|1] "" Vector__XXX
 SG_ FC_a311_GB_battParamsTimeout : 54|1@1+ (1,0) [0|1] "" Vector__XXX
 SG_ FC_a312_GB_evseLimitsTimeout : 55|1@1+ (1,0) [0|1] "" Vector__XXX
 SG_ FC_a313_GB_inputVoltageRailOv : 56|1@1+ (1,0) [0|1] "" Vector__XXX

BO_ 990 FC_alertMatrix6: 8 FC
 SG_ FC_a321_FCAlertPlaceholder : 0|1@1+ (1,0) [0|1] "" Vector__XXX

BO_ 1117 FC_evseBilling: 8 FC
 SG_ FC_evseBillingDataSelect M : 0|1@1+ (1,0) [0|1] "" Vector__XXX
 SG_ FC_evseBillingEnergy m0 : 4|20@1+ (0.001,0) [0|1048.575] "kWh" Vector__XXX
 SG_ FC_evseMeterPower m0 : 24|20@1+ (0.001,0) [0|1048.575] "kW" Vector__XXX
 SG_ FC_evseMeterCurrent m0 : 44|10@1+ (1,0) [0|1023] "A" Vector__XXX
 SG_ FC_evseMeterVoltage m0 : 54|10@1+ (1,0) [0|1023] "V" Vector__XXX
 SG_ FC_evseMeterFwGitHash m1 : 4|56@1+ (1,0) [0|7.20575940379e+16] "" Vector__XXX

BO_ 1334 FC_evseBilling2: 8 FC
 SG_ FC_evseBilling2DataSelect M : 0|4@1+ (1,0) [0|15] "" Vector__XXX
 SG_ FC_evsePpuEnabled m0 : 4|1@1+ (1,0) [0|1] "" Vector__XXX
 SG_ FC_evseBillingEnergyHighRes m0 : 8|24@1+ (0.0001,0) [0|1677.7214] "kWh" Vector__XXX

BO_ 1303 FC_identifier: 8 FC
 SG_ FC_id : 0|32@1+ (1,0) [0|4294967295] "" Vector__XXX
 SG_ FC_sessionId : 32|32@1+ (1,0) [0|4294967295] "" Vector__XXX

BO_ 1310 FC_info: 8 FC
 SG_ FC_infoIndex M : 0|8@1+ (1,0) [0|255] "" Vector__XXX
 SG_ FC_infoBuildType m10 : 8|8@1+ (1,0) [0|255] "" Vector__XXX
 SG_ FC_infoBuildConfigID m10 : 16|16@1+ (1,0) [0|65535] "" Vector__XXX
 SG_ FC_infoHardwareID m10 : 32|16@1+ (1,0) [0|65535] "" Vector__XXX
 SG_ FC_infoComponentID m10 : 48|16@1+ (1,0) [0|65535] "" Vector__XXX
 SG_ FC_infoPcbaID m11 : 16|8@1+ (1,0) [0|255] "" Vector__XXX
 SG_ FC_infoAssemblyID m11 : 24|8@1+ (1,0) [0|255] "" Vector__XXX
 SG_ FC_infoUsageID m11 : 32|16@1+ (1,0) [0|65535] "" Vector__XXX
 SG_ FC_infoSubUsageID m11 : 48|16@1+ (1,0) [0|65535] "" Vector__XXX
 SG_ FC_infoApplicationCRC m13 : 32|32@1+ (1,0) [0|4294967295] "" Vector__XXX
 SG_ FC_infoBootSvnRev m14 : 8|24@1+ (1,0) [0|16777215] "" Vector__XXX
 SG_ FC_infoCPLDVersionMajor m16 : 16|8@1+ (1,0) [0|255] "" Vector__XXX
 SG_ FC_infoCPLDVersionMinor m16 : 24|8@1+ (1,0) [0|255] "" Vector__XXX
 SG_ FC_infoAppGitHashBytes m17 : 8|56@1+ (1,0) [0|7.20575940379e+16] "" Vector__XXX
 SG_ FC_infoBootGitHashBytes m18 : 8|56@1+ (1,0) [0|7.20575940379e+16] "" Vector__XXX
 SG_ FC_infoPlatformType m19 : 8|8@1+ (1,0) [0|255] "" Vector__XXX
 SG_ FC_infoMajorVersion m19 : 16|8@1+ (1,0) [0|255] "" Vector__XXX
 SG_ FC_infoBranchOrigin m19 : 24|8@1+ (1,0) [0|255] "" Vector__XXX
 SG_ FC_infoMaturity m19 : 32|8@1+ (1,0) [0|255] "" Vector__XXX
 SG_ FC_infoHardwareRevision m19 : 40|8@1+ (1,0) [0|255] "" Vector__XXX
 SG_ FC_infoBootUdsProtoVersion m20 : 8|8@1+ (1,0) [0|255] "" Vector__XXX
 SG_ FC_partNumChar01 m25 : 8|8@1+ (1,0) [0|255] "" Vector__XXX
 SG_ FC_partNumChar02 m25 : 16|8@1+ (1,0) [0|255] "" Vector__XXX
 SG_ FC_partNumChar03 m25 : 24|8@1+ (1,0) [0|255] "" Vector__XXX
 SG_ FC_partNumChar04 m25 : 32|8@1+ (1,0) [0|255] "" Vector__XXX
 SG_ FC_partNumChar05 m25 : 40|8@1+ (1,0) [0|255] "" Vector__XXX
 SG_ FC_partNumChar06 m25 : 48|8@1+ (1,0) [0|255] "" Vector__XXX
 SG_ FC_partNumChar07 m25 : 56|8@1+ (1,0) [0|255] "" Vector__XXX
 SG_ FC_partNumChar08 m26 : 8|8@1+ (1,0) [0|255] "" Vector__XXX
 SG_ FC_partNumChar09 m26 : 16|8@1+ (1,0) [0|255] "" Vector__XXX
 SG_ FC_partNumChar10 m26 : 24|8@1+ (1,0) [0|255] "" Vector__XXX
 SG_ FC_partNumChar11 m26 : 32|8@1+ (1,0) [0|255] "" Vector__XXX
 SG_ FC_partNumChar12 m26 : 40|8@1+ (1,0) [0|255] "" Vector__XXX
 SG_ FC_partNumChar13 m26 : 48|8@1+ (1,0) [0|255] "" Vector__XXX
 SG_ FC_partNumChar14 m26 : 56|8@1+ (1,0) [0|255] "" Vector__XXX
 SG_ FC_partNumChar15 m27 : 8|8@1+ (1,0) [0|255] "" Vector__XXX
 SG_ FC_partNumChar16 m27 : 16|8@1+ (1,0) [0|255] "" Vector__XXX
 SG_ FC_partNumChar17 m27 : 24|8@1+ (1,0) [0|255] "" Vector__XXX
 SG_ FC_partNumChar18 m27 : 32|8@1+ (1,0) [0|255] "" Vector__XXX
 SG_ FC_partNumChar19 m27 : 40|8@1+ (1,0) [0|255] "" Vector__XXX
 SG_ FC_partNumChar20 m27 : 48|8@1+ (1,0) [0|255] "" Vector__XXX

BO_ 580 FC_limits: 8 FC
 SG_ FC_powerLimit : 0|13@1+ (0.06225586,0) [0|509.8754934] "kW" Vector__XXX
 SG_ FC_currentLimit : 16|13@1+ (0.07324219,0) [0|599.8535361] "A" Vector__XXX
 SG_ FC_maxVoltageLimit : 32|13@1+ (0.07324219,0) [0|599.8535361] "V" Vector__XXX
 SG_ FC_minVoltageLimit : 48|13@1+ (0.07324219,0) [0|599.8535361] "V" Vector__XXX

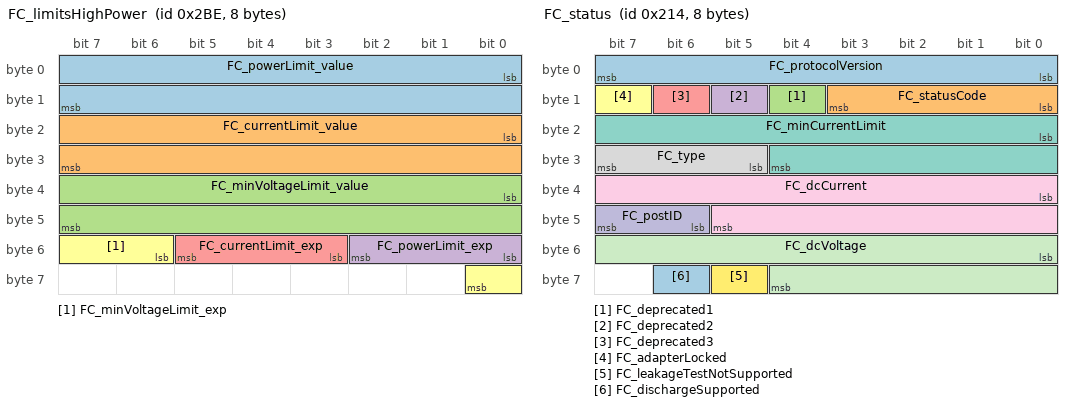
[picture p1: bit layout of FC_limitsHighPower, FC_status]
BO_ 702 FC_limitsHighPower: 8 FC
 SG_ FC_powerLimit_value : 0|16@1- (1,0) [-32767|32767] "*10^exp kW" Vector__XXX
 SG_ FC_currentLimit_value : 16|16@1- (1,0) [-32767|32767] "*10^exp A" Vector__XXX
 SG_ FC_minVoltageLimit_value : 32|16@1- (1,0) [-32767|32767] "*10^exp V" Vector__XXX
 SG_ FC_powerLimit_exp : 48|3@1- (1,0) [-4|3] "" Vector__XXX
 SG_ FC_currentLimit_exp : 51|3@1- (1,0) [-4|3] "" Vector__XXX
 SG_ FC_minVoltageLimit_exp : 54|3@1- (1,0) [-4|3] "" Vector__XXX

BO_ 1345 FC_maxLimits: 8 FC
 SG_ FC_maxPowerLimit : 0|13@1+ (0.06225586,0) [0|509.8754934] "kW" Vector__XXX
 SG_ FC_maxCurrentLimit : 16|13@1+ (0.07324219,0) [0|599.8535361] "A" Vector__XXX

BO_ 1300 FC_serial: 8 FC
 SG_ FC_serialDataSelect M : 0|7@1+ (1,0) [0|127] "" Vector__XXX
 SG_ FC_serialChar01 m0 : 8|8@1+ (1,0) [0|255] "" Vector__XXX
 SG_ FC_serialChar02 m0 : 16|8@1+ (1,0) [0|255] "" Vector__XXX
 SG_ FC_serialChar03 m0 : 24|8@1+ (1,0) [0|255] "" Vector__XXX
 SG_ FC_serialChar04 m0 : 32|8@1+ (1,0) [0|255] "" Vector__XXX
 SG_ FC_serialChar05 m0 : 40|8@1+ (1,0) [0|255] "" Vector__XXX
 SG_ FC_serialChar06 m0 : 48|8@1+ (1,0) [0|255] "" Vector__XXX
 SG_ FC_serialChar07 m0 : 56|8@1+ (1,0) [0|255] "" Vector__XXX
 SG_ FC_serialChar08 m1 : 8|8@1+ (1,0) [0|255] "" Vector__XXX
 SG_ FC_serialChar09 m1 : 16|8@1+ (1,0) [0|255] "" Vector__XXX
 SG_ FC_serialChar10 m1 : 24|8@1+ (1,0) [0|255] "" Vector__XXX
 SG_ FC_serialChar11 m1 : 32|8@1+ (1,0) [0|255] "" Vector__XXX
 SG_ FC_serialChar12 m1 : 40|8@1+ (1,0) [0|255] "" Vector__XXX
 SG_ FC_serialChar13 m1 : 48|8@1+ (1,0) [0|255] "" Vector__XXX
 SG_ FC_serialChar14 m1 : 56|8@1+ (1,0) [0|255] "" Vector__XXX
 SG_ FC_serialChar15 m2 : 8|8@1+ (1,0) [0|255] "" Vector__XXX
 SG_ FC_serialChar16 m2 : 16|8@1+ (1,0) [0|255] "" Vector__XXX
 SG_ FC_serialChar17 m2 : 24|8@1+ (1,0) [0|255] "" Vector__XXX

BO_ 532 FC_status: 8 FC
 SG_ FC_protocolVersion : 0|8@1+ (1,0) [0|255] "" Vector__XXX
 SG_ FC_statusCode : 8|4@1+ (1,0) [1|15] "" Vector__XXX
 SG_ FC_deprecated1 : 12|1@1+ (1,0) [0|1] "" Vector__XXX
 SG_ FC_deprecated2 : 13|1@1+ (1,0) [0|1] "" Vector__XXX
 SG_ FC_deprecated3 : 14|1@1+ (1,0) [0|1] "" Vector__XXX
 SG_ FC_adapterLocked : 15|1@1+ (1,0) [0|1] "" Vector__XXX
 SG_ FC_minCurrentLimit : 16|13@1+ (0.1,0) [0|600] "A" Vector__XXX
 SG_ FC_type : 29|3@1+ (1,0) [0|6] "" Vector__XXX
 SG_ FC_dcCurrent : 32|14@1- (0.07324219,0) [-600|599.92675781] "A" Vector__XXX
 SG_ FC_postID : 46|2@1+ (1,0) [0|2] "" Vector__XXX
 SG_ FC_dcVoltage : 48|13@1+ (0.07324219,0) [0|599.92675822] "V" Vector__XXX
 SG_ FC_leakageTestNotSupported : 61|1@1+ (1,0) [0|1] "" Vector__XXX
 SG_ FC_dischargeSupported : 62|1@1+ (1,0) [0|1] "" Vector__XXX

BO_ 533 FC_status2: 1 FC
 SG_ FC_externalIsolationResistance : 0|8@1+ (40,0) [0|10160] "kOhm" Vector__XXX

BO_ 535 FC_status3: 8 FC
 SG_ FC_status3DataSelect M : 0|7@1+ (1,0) [0|127] "" Vector__XXX
 SG_ FC_status3DummySig : 7|1@1+ (1,0) [0|1] "" Vector__XXX
 SG_ FC_class m0 : 8|8@1+ (1,0) [1|255] "" Vector__XXX
 SG_ FC_brand m0 : 16|4@1+ (1,0) [1|15] "" Vector__XXX
 SG_ FC_coolingType m0 : 20|4@1+ (1,0) [1|15] "" Vector__XXX
 SG_ FC_uiStopType m0 : 24|4@1+ (1,0) [1|15] "" Vector__XXX
 SG_ FC_emergencyShutdownSupported m0 : 28|1@1+ (1,0) [0|1] "" Vector__XXX
 SG_ FC_generation m0 : 32|8@1+ (1,0) [1|255] "" Vector__XXX
 SG_ FC_billingEnergy m1 : 8|16@1+ (0.015259,0) [0|999.998565] "kWh" Vector__XXX

BO_ 2047 GTW_carConfig: 8 GTW
 SG_ GTW_carConfigMultiplexer M : 0|8@1+ (1,0) [0|255] "" Vector__XXX
 SG_ GTW_deliveryStatus m1 : 8|1@1+ (1,0) [0|1] "" Vector__XXX
 SG_ GTW_cabinPTCHeaterType m1 : 10|1@1+ (1,0) [0|1] "" Vector__XXX
 SG_ GTW_rightHandDrive m1 : 11|1@1+ (1,0) [0|1] "" Vector__XXX
 SG_ GTW_rearLightType m1 : 12|2@1+ (1,0) [0|3] "" Vector__XXX
 SG_ GTW_headlamps m1 : 14|2@1+ (1,0) [0|3] "" Vector__XXX
 SG_ GTW_country m1 : 16|16@1+ (1,0) [0|65535] "" Vector__XXX
 SG_ GTW_tireType m1 : 32|6@1+ (1,0) [0|63] "" Vector__XXX
 SG_ GTW_dasHw m1 : 40|3@1+ (1,0) [3|5] "" Vector__XXX
 SG_ GTW_brakeHWType m1 : 43|5@1+ (1,0) [0|31] "" Vector__XXX
 SG_ GTW_restraintsHardwareType m1 : 48|8@1+ (1,0) [0|255] "" Vector__XXX
 SG_ GTW_drivetrainType m1 : 56|4@1+ (1,0) [0|4] "" Vector__XXX
 SG_ GTW_radarHeaterType m1 : 60|3@1+ (1,0) [0|5] "" Vector__XXX
 SG_ GTW_exteriorTrimType m2 : 8|1@1+ (1,0) [0|1] "" Vector__XXX
 SG_ GTW_frontSeatHeaters m2 : 9|1@1+ (1,0) [0|1] "" Vector__XXX
 SG_ GTW_rearSeatHeaters m2 : 10|1@1+ (1,0) [0|1] "" Vector__XXX
 SG_ GTW_eCallAntennaHW m2 : 12|1@1+ (1,0) [0|1] "" Vector__XXX
 SG_ GTW_homelinkType m2 : 13|1@1+ (1,0) [0|1] "" Vector__XXX
 SG_ GTW_vdcType m2 : 14|1@1+ (1,0) [0|1] "" Vector__XXX
 SG_ GTW_memoryMirrors m2 : 17|1@1+ (1,0) [0|1] "" Vector__XXX
 SG_ GTW_powerLiftgateType m2 : 18|2@1+ (1,0) [0|2] "" Vector__XXX
 SG_ GTW_lumbarECUType m2 : 20|4@1+ (1,0) [0|15] "" Vector__XXX
 SG_ GTW_rearSeatHeaterType m2 : 24|2@1+ (1,0) [0|3] "" Vector__XXX
 SG_ GTW_auxParkLamps m2 : 26|2@1+ (1,0) [0|3] "" Vector__XXX
 SG_ GTW_interiorCabinRadarType m2 : 28|1@1+ (1,0) [0|1] "" Vector__XXX
 SG_ GTW_hvacPanelVaneType m2 : 29|1@1+ (1,0) [0|1] "" Vector__XXX
 SG_ GTW_intakeAirFilterType m2 : 30|2@1+ (1,0) [0|2] "" Vector__XXX
 SG_ GTW_eBuckConfig m2 : 32|1@1+ (1,0) [0|1] "" Vector__XXX
 SG_ GTW_steeringHeaterEnabled m2 : 33|1@1+ (1,0) [0|1] "" Vector__XXX
 SG_ GTW_activeHighBeam m2 : 34|1@1+ (1,0) [0|1] "" Vector__XXX
 SG_ GTW_airbagCutoffSwitch m2 : 35|1@1+ (1,0) [0|1] "" Vector__XXX
 SG_ GTW_intrusionSensorType m2 : 36|1@1+ (1,0) [0|1] "" Vector__XXX
 SG_ GTW_spoilerType m2 : 37|1@1+ (1,0) [0|1] "" Vector__XXX
 SG_ GTW_backupCameraType m2 : 38|1@1+ (1,0) [0|1] "" Vector__XXX
 SG_ GTW_rearFogLamps m2 : 39|1@1+ (1,0) [0|1] "" Vector__XXX
 SG_ GTW_roofType m2 : 40|1@1+ (1,0) [0|1] "" Vector__XXX
 SG_ GTW_thirdRowSeatType m2 : 41|1@1+ (1,0) [0|1] "" Vector__XXX
 SG_ GTW_autopilot m2 : 42|3@1+ (1,0) [0|7] "" Vector__XXX
 SG_ GTW_superchargingAccess m2 : 45|2@1+ (1,0) [0|3] "" Vector__XXX
 SG_ GTW_exteriorColor m2 : 48|5@1+ (1,0) [0|31] "" Vector__XXX
 SG_ GTW_pedestrianWarningSound m2 : 53|2@1+ (1,0) [0|3] "" Vector__XXX
 SG_ GTW_steeringColumnUJointType m2 : 55|1@1+ (1,0) [0|1] "" Vector__XXX
 SG_ GTW_bPillarNFCParam m2 : 56|1@1+ (1,0) [0|1] "" Vector__XXX
 SG_ GTW_interiorLighting m2 : 57|3@1+ (1,0) [0|7] "" Vector__XXX
 SG_ GTW_headlightLevelerType m2 : 60|2@1+ (1,0) [0|3] "" Vector__XXX
 SG_ GTW_numberHVILNodes m2 : 62|2@1+ (1,0) [0|3] "" Vector__XXX
 SG_ GTW_mapRegion m3 : 8|4@1+ (1,0) [0|15] "" Vector__XXX
 SG_ GTW_performancePackage m3 : 12|3@1+ (1,0) [0|7] "" Vector__XXX
 SG_ GTW_chassisType m3 : 18|4@1+ (1,0) [0|15] "" Vector__XXX
 SG_ GTW_airSuspension m3 : 22|2@1+ (1,0) [0|3] "" Vector__XXX
 SG_ GTW_centerConsoleControllerType m3 : 24|2@1+ (1,0) [0|3] "" Vector__XXX
 SG_ GTW_autopilotCameraType m3 : 26|1@1+ (1,0) [0|1] "" Vector__XXX
 SG_ GTW_connectivityPackage m3 : 27|1@1+ (1,0) [0|1] "" Vector__XXX
 SG_ GTW_plcSupportType m3 : 28|2@1+ (1,0) [0|3] "" Vector__XXX
 SG_ GTW_badgingVersion m3 : 30|2@1+ (1,0) [0|3] "" Vector__XXX
 SG_ GTW_packEnergy m3 : 32|5@1+ (1,0) [0|31] "" Vector__XXX
 SG_ GTW_frontSeatReclinerHardware m3 : 37|2@1+ (1,0) [0|3] "" Vector__XXX
 SG_ GTW_brakeLineSwitchType m3 : 39|1@1+ (1,0) [0|1] "" Vector__XXX
 SG_ GTW_espValveType m3 : 40|2@1+ (1,0) [0|3] "" Vector__XXX
 SG_ GTW_softRange m3 : 42|3@1+ (1,0) [0|7] "" Vector__XXX
 SG_ GTW_refrigerantType m3 : 45|2@1+ (1,0) [0|3] "" Vector__XXX
 SG_ GTW_wheelType m3 : 48|7@1+ (1,0) [0|127] "" Vector__XXX
 SG_ GTW_ptcControlMode m3 : 55|2@1+ (1,0) [0|3] "" Vector__XXX
 SG_ GTW_brakeActuationType m3 : 57|3@1+ (1,0) [0|4] "" Vector__XXX
 SG_ GTW_secondRowSeatType m3 : 60|3@1+ (1,0) [0|7] "" Vector__XXX
 SG_ GTW_secondRowSeatMotorType m3 : 63|1@1+ (1,0) [0|1] "" Vector__XXX
 SG_ GTW_birthday m4 : 8|32@1+ (1,0) [0|4294967295] "" Vector__XXX
 SG_ GTW_eCallEnabled m4 : 40|2@1+ (1,0) [0|3] "" Vector__XXX
 SG_ GTW_parkAssistECUType m4 : 42|2@1+ (1,0) [0|3] "" Vector__XXX
 SG_ GTW_passengerAirbagType m4 : 44|2@1+ (1,0) [0|3] "" Vector__XXX
 SG_ GTW_forwardRadarHw m4 : 46|2@1+ (1,0) [0|2] "" Vector__XXX
 SG_ GTW_frontSeatType m4 : 48|4@1+ (1,0) [0|15] "" Vector__XXX
 SG_ GTW_secondRowDisplayType m4 : 52|1@1+ (1,0) [0|1] "" Vector__XXX
 SG_ GTW_wirelessPhoneChargerType m4 : 53|2@1+ (1,0) [0|3] "" Vector__XXX
 SG_ GTW_ethernetTunerType m4 : 55|2@1+ (1,0) [0|3] "" Vector__XXX
 SG_ GTW_interiorTrimType m4 : 60|4@1+ (1,0) [0|15] "" Vector__XXX
 SG_ GTW_gloveboxUSBType m5 : 8|2@1+ (1,0) [0|3] "" Vector__XXX
 SG_ GTW_coolantPumpType m5 : 10|3@1+ (1,0) [0|7] "" Vector__XXX
 SG_ GTW_epblHwType m5 : 13|4@1+ (1,0) [0|15] "" Vector__XXX
 SG_ GTW_epbrHwType m5 : 17|4@1+ (1,0) [0|15] "" Vector__XXX
 SG_ GTW_blowerMotorType m5 : 21|2@1+ (1,0) [0|3] "" Vector__XXX
 SG_ GTW_rearLeftBLEEndpointParameter m5 : 23|1@1+ (1,0) [0|1] "" Vector__XXX
 SG_ GTW_powerMirrorFoldType m5 : 24|1@1+ (1,0) [0|1] "" Vector__XXX
 SG_ GTW_frontUsbHubType m5 : 27|3@1+ (1,0) [0|5] "" Vector__XXX
 SG_ GTW_superManifoldType m5 : 30|2@1+ (1,0) [0|3] "" Vector__XXX
 SG_ GTW_rcmLocation m5 : 32|1@1+ (1,0) [0|1] "" Vector__XXX
 SG_ GTW_autopilotExteriorCameraType m5 : 33|1@1+ (1,0) [0|1] "" Vector__XXX
 SG_ GTW_interiorCamBeautyCoverType m5 : 35|2@1+ (1,0) [0|3] "" Vector__XXX
 SG_ GTW_sirenType m5 : 37|1@1+ (1,0) [0|1] "" Vector__XXX
 SG_ GTW_hornType m5 : 38|1@1+ (1,0) [0|1] "" Vector__XXX
 SG_ GTW_passengerTrackMotorType m5 : 40|1@1+ (1,0) [0|1] "" Vector__XXX
 SG_ GTW_steeringColumnMotorType m5 : 42|2@1+ (1,0) [0|3] "" Vector__XXX
 SG_ GTW_refrigACLineType m5 : 48|2@1+ (1,0) [0|3] "" Vector__XXX
 SG_ GTW_refrigFilterType m5 : 50|2@1+ (1,0) [0|3] "" Vector__XXX
 SG_ GTW_diBurnInType m5 : 52|1@1+ (1,0) [0|1] "" Vector__XXX
 SG_ GTW_specialBadgingType m5 : 53|2@1+ (1,0) [0|3] "" Vector__XXX
 SG_ GTW_chassisSubType m5 : 55|3@1+ (1,0) [0|7] "" Vector__XXX
 SG_ GTW_towPackage m5 : 58|2@1+ (1,0) [0|3] "" Vector__XXX
 SG_ GTW_refrigLccType m5 : 60|1@1+ (1,0) [0|1] "" Vector__XXX
 SG_ GTW_restraintControlsType m5 : 61|1@1+ (1,0) [0|1] "" Vector__XXX
 SG_ GTW_caliperColorType m5 : 62|2@1+ (1,0) [0|3] "" Vector__XXX
 SG_ GTW_wiperMotorType m6 : 9|1@1+ (1,0) [0|1] "" Vector__XXX
 SG_ GTW_frontOverheadConsoleType m6 : 10|2@1+ (1,0) [0|3] "" Vector__XXX
 SG_ GTW_shifterType m6 : 12|1@1+ (1,0) [0|1] "" Vector__XXX
 SG_ GTW_compressorType m6 : 13|4@1+ (1,0) [0|15] "" Vector__XXX
 SG_ GTW_twelveVBatteryType m6 : 17|3@1+ (1,0) [0|7] "" Vector__XXX
 SG_ GTW_efuseSWConfig m6 : 20|3@1+ (1,0) [0|7] "" Vector__XXX
 SG_ GTW_tollCollectionModuleType m6 : 23|1@1+ (1,0) [0|1] "" Vector__XXX
 SG_ GTW_bleEndpointUpdateMethod m6 : 24|1@1+ (1,0) [0|1] "" Vector__XXX
 SG_ GTW_steeringWheelControllerType m6 : 25|3@1+ (1,0) [0|7] "" Vector__XXX
 SG_ GTW_frontSeatVentilationEnabled m6 : 28|1@1+ (1,0) [0|1] "" Vector__XXX
 SG_ GTW_gloveboxActuatorType m6 : 29|2@1+ (1,0) [0|3] "" Vector__XXX
 SG_ GTW_epasType m6 : 32|4@1+ (1,0) [0|11] "" Vector__XXX
 SG_ GTW_homologationRegionOverride m6 : 36|2@1+ (1,0) [0|3] "" Vector__XXX
 SG_ GTW_windowCommandsPermissionType m6 : 38|2@1+ (1,0) [0|3] "" Vector__XXX
 SG_ GTW_headlightStepperStallDetectM m6 : 42|1@1+ (1,0) [0|1] "" Vector__XXX
 SG_ GTW_rgbInteriorLightingEnabled m6 : 43|2@1+ (1,0) [0|3] "" Vector__XXX
 SG_ GTW_windshieldWiperHeaterType m6 : 45|1@1+ (1,0) [0|1] "" Vector__XXX
 SG_ GTW_thirdRowSeatReclinerType m6 : 46|1@1+ (1,0) [0|1] "" Vector__XXX
 SG_ GTW_driveInterfaceType m6 : 47|1@1+ (1,0) [0|1] "" Vector__XXX
 SG_ GTW_efficiencyPackage m6 : 49|6@1+ (1,0) [0|63] "" Vector__XXX
 SG_ GTW_visorLightType m6 : 55|1@1+ (1,0) [0|1] "" Vector__XXX
 SG_ GTW_gnssAntennaType m6 : 58|2@1+ (1,0) [0|3] "" Vector__XXX
 SG_ GTW_airDistributionBoxType m6 : 60|1@1+ (1,0) [0|1] "" Vector__XXX
 SG_ GTW_frontSeatHeatersEnabled m6 : 62|1@1+ (1,0) [0|1] "" Vector__XXX
 SG_ GTW_windshieldWiperHeaterEnabled m6 : 63|1@1+ (1,0) [0|1] "" Vector__XXX
 SG_ GTW_alcoholInterlockType m7 : 8|1@1+ (1,0) [0|1] "" Vector__XXX
 SG_ GTW_fasciaType m7 : 9|4@1+ (1,0) [0|15] "" Vector__XXX
 SG_ GTW_powerSteeringColumn m7 : 13|1@1+ (1,0) [0|1] "" Vector__XXX
 SG_ GTW_frontSeatHeaterType m7 : 14|1@1+ (1,0) [0|1] "" Vector__XXX
 SG_ GTW_softPerformanceLimit m7 : 15|4@1+ (1,0) [0|15] "" Vector__XXX
 SG_ GTW_gsrFeatureType m7 : 21|2@1+ (1,0) [0|2] "" Vector__XXX
 SG_ GTW_immersiveAudio m7 : 23|2@1+ (1,0) [0|3] "" Vector__XXX
 SG_ GTW_frontSeatVentilationType m7 : 25|1@1+ (1,0) [0|1] "" Vector__XXX
 SG_ GTW_passengerOccupancySensorType m7 : 26|3@1+ (1,0) [0|7] "" Vector__XXX
 SG_ GTW_packPerformanceDeviation m7 : 30|3@1+ (1,0) [0|7] "" Vector__XXX
 SG_ GTW_pressurePadType m7 : 33|2@1+ (1,0) [0|3] "" Vector__XXX
 SG_ GTW_frontFogLamps m7 : 35|1@1+ (1,0) [0|1] "" Vector__XXX
 SG_ GTW_driverOccupancySensorType m7 : 36|1@1+ (1,0) [0|1] "" Vector__XXX
 SG_ GTW_audioType m7 : 37|3@1+ (1,0) [0|7] "" Vector__XXX
 SG_ GTW_thighExtenderType m7 : 41|1@1+ (1,0) [0|1] "" Vector__XXX
 SG_ GTW_occupancyClassificationFeatu m7 : 42|1@1+ (1,0) [0|1] "" Vector__XXX
 SG_ GTW_frontControllerArchitectureT m7 : 46|1@1+ (1,0) [0|1] "" Vector__XXX
 SG_ GTW_domeLightType m7 : 47|2@1+ (1,0) [0|3] "" Vector__XXX
 SG_ GTW_tpmsType m7 : 49|2@1+ (1,0) [0|3] "" Vector__XXX
 SG_ GTW_authenticationEndpointLayout m7 : 52|3@1+ (1,0) [0|6] "" Vector__XXX
 SG_ GTW_socSleepOverride m7 : 57|2@1+ (1,0) [0|3] "" Vector__XXX
 SG_ GTW_r79BehaviorOverride m7 : 59|1@1+ (1,0) [0|1] "" Vector__XXX
 SG_ GTW_steeringHeaterType m7 : 60|3@1+ (1,0) [0|7] "" Vector__XXX
 SG_ GTW_narrowWipingSupported m7 : 63|1@1+ (1,0) [0|1] "" Vector__XXX
 SG_ GTW_frontSeatHeaterGridType m8 : 8|1@1+ (1,0) [0|1] "" Vector__XXX
 SG_ GTW_frontSeatSideSwitchType m8 : 9|1@1+ (1,0) [0|1] "" Vector__XXX
 SG_ GTW_sohRegulatoryStatus m8 : 10|1@1+ (1,0) [0|1] "" Vector__XXX
 SG_ GTW_passengerTiltMotorType m8 : 11|2@1+ (1,0) [0|3] "" Vector__XXX
 SG_ GTW_frunkInteriorReleaseType m8 : 15|1@1+ (1,0) [0|1] "" Vector__XXX
 SG_ GTW_m3yBusArchitecture m8 : 17|2@1+ (1,0) [0|3] "" Vector__XXX
 SG_ GTW_passengerLiftMotorType m8 : 19|2@1+ (1,0) [0|3] "" Vector__XXX
 SG_ GTW_interiorUpperTrimType m8 : 21|1@1+ (1,0) [0|1] "" Vector__XXX
 SG_ GTW_blindSpotIndicatorLightType m8 : 22|2@1+ (1,0) [0|3] "" Vector__XXX
 SG_ GTW_wiperMotorAsicType m8 : 24|2@1+ (1,0) [0|3] "" Vector__XXX
 SG_ GTW_hvacCaseDoorType m8 : 28|1@1+ (1,0) [0|1] "" Vector__XXX
 SG_ GTW_occupancyDetectionSourceRequ m8 : 29|1@1+ (1,0) [0|1] "" Vector__XXX
 SG_ GTW_rduCableType m8 : 31|1@1+ (1,0) [0|1] "" Vector__XXX
 SG_ GTW_parkTelltaleBehaviorType m8 : 32|1@1+ (1,0) [0|1] "" Vector__XXX
 SG_ GTW_numberKeyCardsPairedInFactor m8 : 35|2@1+ (1,0) [0|2] "" Vector__XXX
 SG_ GTW_secondRowSeatVentilationType m8 : 37|1@1+ (1,0) [0|1] "" Vector__XXX
 SG_ GTW_thirdRowSeatHeaterType m8 : 38|1@1+ (1,0) [0|1] "" Vector__XXX
 SG_ GTW_interiorCameraType m8 : 39|2@1+ (1,0) [0|2] "" Vector__XXX
 SG_ GTW_frontFasciaCameraType m8 : 41|2@1+ (1,0) [0|3] "" Vector__XXX
 SG_ GTW_interiorCamFanType m8 : 45|3@1+ (1,0) [0|7] "" Vector__XXX
 SG_ GTW_puddleLampType m8 : 50|2@1+ (1,0) [0|2] "" Vector__XXX
 SG_ GTW_solarLensType m8 : 52|2@1+ (1,0) [0|2] "" Vector__XXX
 SG_ GTW_liftgateGeometryType m8 : 56|2@1+ (1,0) [0|3] "" Vector__XXX
 SG_ GTW_repeaterAeroRibType m8 : 60|3@1+ (1,0) [0|7] "" Vector__XXX
 SG_ GTW_highTipForceWiperArmsType m8 : 63|1@1+ (1,0) [0|1] "" Vector__XXX
 SG_ GTW_rcmUndersideAbuseZThreshold m9 : 8|3@1+ (1,0) [0|7] "" Vector__XXX
 SG_ GTW_rcmUndersideAbuseYThreshold m9 : 11|3@1+ (1,0) [0|7] "" Vector__XXX
 SG_ GTW_rcmUndersideAbuseWindow m9 : 14|2@1+ (1,0) [0|3] "" Vector__XXX
 SG_ GTW_uhfChargePortEnabled m9 : 16|1@1+ (1,0) [0|1] "" Vector__XXX
 SG_ GTW_automaticFeatureResetPackage m9 : 18|1@1+ (1,0) [0|1] "" Vector__XXX
 SG_ GTW_autopilotFeaturePackage m9 : 20|2@1+ (1,0) [0|2] "" Vector__XXX
 SG_ GTW_doorLatchType m9 : 23|1@1+ (1,0) [0|1] "" Vector__XXX
 SG_ GTW_headlinerMaterialType m9 : 25|2@1+ (1,0) [0|3] "" Vector__XXX
 SG_ GTW_glareShieldHeaterType m9 : 27|1@1+ (1,0) [0|1] "" Vector__XXX
 SG_ GTW_rearLightHardwareVariant m9 : 29|2@1+ (1,0) [0|3] "" Vector__XXX
 SG_ GTW_fasciaHarnessCleanPointType m9 : 31|2@1+ (1,0) [0|3] "" Vector__XXX
 SG_ GTW_epasSubType m9 : 33|1@1+ (1,0) [0|1] "" Vector__XXX
 SG_ GTW_wiperSupplyChainOrigin m9 : 35|2@1+ (1,0) [1|3] "" Vector__XXX
 SG_ GTW_windowPinchParameterType m9 : 37|2@1+ (1,0) [0|3] "" Vector__XXX
 SG_ GTW_badgingMaterialType m9 : 39|1@1+ (1,0) [0|1] "" Vector__XXX
 SG_ GTW_mRecordVersion m9 : 40|1@1+ (1,0) [0|1] "" Vector__XXX
 SG_ GTW_tcuType m9 : 47|2@1+ (1,0) [0|2] "" Vector__XXX
 SG_ GTW_carbComplianceBehaviorType m9 : 49|1@1+ (1,0) [0|1] "" Vector__XXX
 SG_ GTW_indirectTPMSCalibrationType m9 : 55|3@1+ (1,0) [0|7] "" Vector__XXX
 SG_ GTW_v2xEnabled m9 : 58|1@1+ (1,0) [0|1] "" Vector__XXX
 SG_ GTW_liftgateStrutType m9 : 60|1@1+ (1,0) [0|1] "" Vector__XXX
 SG_ GTW_exteriorMicrophoneType m9 : 63|1@1+ (1,0) [0|1] "" Vector__XXX
 SG_ GTW_contactorPowerSource m10 : 20|1@1+ (1,0) [0|1] "" Vector__XXX
 SG_ GTW_roofGlassType m10 : 21|3@1+ (1,0) [0|7] "" Vector__XXX
 SG_ GTW_pedalMapNameOverride m10 : 25|1@1+ (1,0) [0|1] "" Vector__XXX

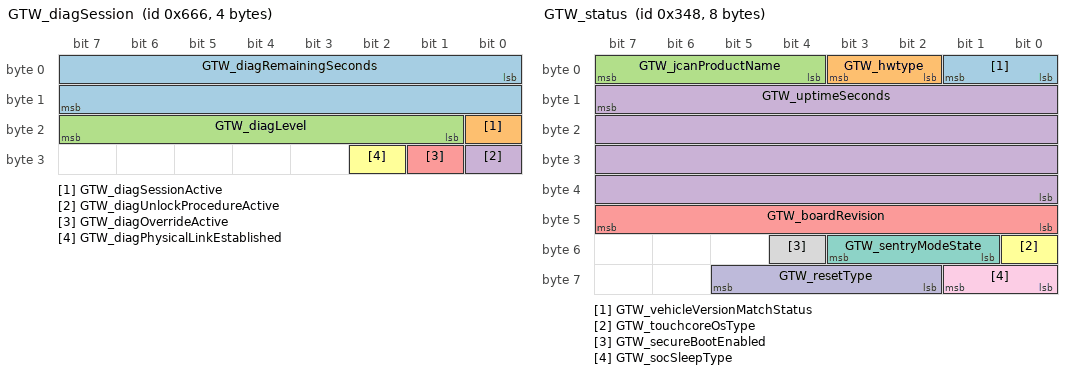
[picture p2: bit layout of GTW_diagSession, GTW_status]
BO_ 1638 GTW_diagSession: 4 GTW
 SG_ GTW_diagRemainingSeconds : 0|16@1+ (1,0) [0|65535] "seconds" Vector__XXX
 SG_ GTW_diagSessionActive : 16|1@1+ (1,0) [0|1] "" Vector__XXX
 SG_ GTW_diagLevel : 17|7@1+ (1,0) [0|127] "" Vector__XXX
 SG_ GTW_diagUnlockProcedureActive : 24|1@1+ (1,0) [0|1] "" Vector__XXX
 SG_ GTW_diagOverrideActive : 25|1@1+ (1,0) [0|1] "" Vector__XXX
 SG_ GTW_diagPhysicalLinkEstablished : 26|1@1+ (1,0) [0|1] "" Vector__XXX

BO_ 840 GTW_status: 8 GTW
 SG_ GTW_vehicleVersionMatchStatus : 0|2@1+ (1,0) [0|3] "" Vector__XXX
 SG_ GTW_hwtype : 2|2@1+ (1,0) [1|3] "" Vector__XXX
 SG_ GTW_jcanProductName : 4|4@1+ (1,0) [1|15] "" Vector__XXX
 SG_ GTW_uptimeSeconds : 15|32@0+ (1,0) [0|4294967295] "s" Vector__XXX
 SG_ GTW_boardRevision : 40|8@1+ (1,0) [0|255] "" Vector__XXX
 SG_ GTW_touchcoreOsType : 48|1@1+ (1,0) [0|1] "" Vector__XXX
 SG_ GTW_sentryModeState : 49|3@1+ (1,0) [0|7] "" Vector__XXX
 SG_ GTW_secureBootEnabled : 52|1@1+ (1,0) [0|1] "" Vector__XXX
 SG_ GTW_socSleepType : 56|2@1+ (1,0) [1|3] "" Vector__XXX
 SG_ GTW_resetType : 58|4@1+ (1,0) [1|15] "" Vector__XXX

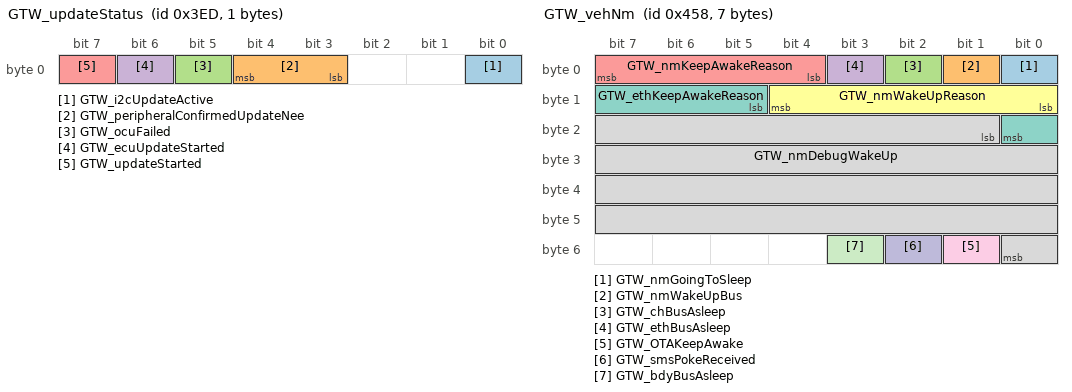
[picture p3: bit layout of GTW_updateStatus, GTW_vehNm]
BO_ 1005 GTW_updateStatus: 1 GTW
 SG_ GTW_i2cUpdateActive : 0|1@1+ (1,0) [0|1] "" Vector__XXX
 SG_ GTW_peripheralConfirmedUpdateNee : 3|2@1+ (1,0) [0|3] "" Vector__XXX
 SG_ GTW_ocuFailed : 5|1@1+ (1,0) [0|1] "" Vector__XXX
 SG_ GTW_ecuUpdateStarted : 6|1@1+ (1,0) [0|1] "" Vector__XXX
 SG_ GTW_updateStarted : 7|1@1+ (1,0) [0|1] "" Vector__XXX

BO_ 1112 GTW_vehNm: 7 GTW
 SG_ GTW_nmGoingToSleep : 0|1@1+ (1,0) [0|1] "" Vector__XXX
 SG_ GTW_nmWakeUpBus : 1|1@1+ (1,0) [0|1] "" Vector__XXX
 SG_ GTW_chBusAsleep : 2|1@1+ (1,0) [0|1] "" Vector__XXX
 SG_ GTW_ethBusAsleep : 3|1@1+ (1,0) [0|1] "" Vector__XXX
 SG_ GTW_nmKeepAwakeReason : 4|4@1+ (1,0) [1|15] "" Vector__XXX
 SG_ GTW_nmWakeUpReason : 8|5@1+ (1,0) [0|31] "" Vector__XXX
 SG_ GTW_ethKeepAwakeReason : 13|4@1+ (1,0) [1|15] "" Vector__XXX
 SG_ GTW_nmDebugWakeUp : 17|32@1+ (1,0) [0|4294967295] "" Vector__XXX
 SG_ GTW_OTAKeepAwake : 49|1@1+ (1,0) [0|1] "" Vector__XXX
 SG_ GTW_smsPokeReceived : 50|1@1+ (1,0) [0|1] "" Vector__XXX
 SG_ GTW_bdyBusAsleep : 51|1@1+ (1,0) [0|1] "" Vector__XXX

BO_ 1650 HCML_info: 8 HCML
 SG_ VC_hcmlInfoIndex M : 0|4@1+ (1,0) [0|15] "" Vector__XXX
 SG_ VC_infoHCMLBuildConfigId m0 : 8|16@1+ (1,0) [0|65535] "" Vector__XXX
 SG_ VC_leftHeadlampLMMVariant m0 : 24|2@1+ (1,0) [1|3] "" Vector__XXX
 SG_ VC_infoHCMLAssemblyId m1 : 8|16@1+ (1,0) [0|65535] "" Vector__XXX
 SG_ VC_infoHCMLPcbaId m1 : 24|16@1+ (1,0) [0|65535] "" Vector__XXX
 SG_ VC_infoHCMLUsageId m1 : 40|16@1+ (1,0) [0|65535] "" Vector__XXX

BO_ 1980 HCMR_info: 8 HCMR
 SG_ VC_hcmrInfoIndex M : 0|4@1+ (1,0) [0|15] "" Vector__XXX
 SG_ VC_infoHCMRBuildConfigId m0 : 8|16@1+ (1,0) [0|65535] "" Vector__XXX
 SG_ VC_rightHeadlampLMMVariant m0 : 24|2@1+ (1,0) [1|3] "" Vector__XXX
 SG_ VC_infoHCMRAssemblyId m1 : 8|16@1+ (1,0) [0|65535] "" Vector__XXX
 SG_ VC_infoHCMRPcbaId m1 : 24|16@1+ (1,0) [0|65535] "" Vector__XXX
 SG_ VC_infoHCMRUsageId m1 : 40|16@1+ (1,0) [0|65535] "" Vector__XXX

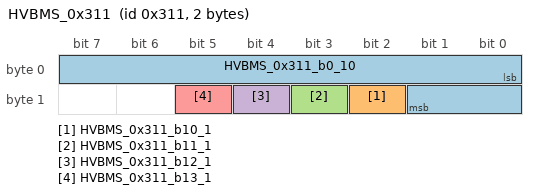
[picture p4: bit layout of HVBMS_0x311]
BO_ 785 HVBMS_0x311: 2 Vector__XXX
 SG_ HVBMS_0x311_b0_10 : 0|10@1+ (1,0) [0|1023] "" Vector__XXX
 SG_ HVBMS_0x311_b10_1 : 10|1@1+ (1,0) [0|1] "" Vector__XXX
 SG_ HVBMS_0x311_b11_1 : 11|1@1+ (1,0) [0|1] "" Vector__XXX
 SG_ HVBMS_0x311_b12_1 : 12|1@1+ (1,0) [0|1] "" Vector__XXX
 SG_ HVBMS_0x311_b13_1 : 13|1@1+ (1,0) [0|1] "" Vector__XXX

BO_ 1106 HVBMS_0x452: 3 Vector__XXX
 SG_ HVBMS_0x452_b0_10 : 0|10@1+ (1,0) [0|1023] "" Vector__XXX

BO_TX_BU_ 1000 : EPBR;
BO_TX_BU_ 2024 : EPBR;
BO_TX_BU_ 552 : EPBR;
BO_TX_BU_ 742 : EPBR;
BO_TX_BU_ 744 : EPBR;
BO_TX_BU_ 1575 : EPBR;
BO_TX_BU_ 1662 : EVSE;
BO_TX_BU_ 1322 : FC;
BO_TX_BU_ 895 : FC;
BO_TX_BU_ 927 : FC;
BO_TX_BU_ 958 : FC;
BO_TX_BU_ 990 : FC;
BO_TX_BU_ 1117 : FC;
BO_TX_BU_ 1334 : FC;
BO_TX_BU_ 1303 : FC;
BO_TX_BU_ 1310 : FC;
BO_TX_BU_ 580 : FC;
BO_TX_BU_ 702 : FC;
BO_TX_BU_ 1345 : FC;
BO_TX_BU_ 1300 : FC;
BO_TX_BU_ 532 : FC;
BO_TX_BU_ 533 : FC;
BO_TX_BU_ 535 : FC;
BO_TX_BU_ 2047 : GTW;
BO_TX_BU_ 1638 : GTW;
BO_TX_BU_ 840 : GTW;
BO_TX_BU_ 1005 : GTW;
BO_TX_BU_ 1112 : GTW;
BO_TX_BU_ 1650 : HCML;
BO_TX_BU_ 1980 : HCMR;
CM_ BO_ 1000 "Right electric parking brake message: alert matrix; frame length observed on a vehicle bus";
CM_ SG_ 1000 EPBR_matrixIndex "Right electric parking brake: matrix index";
CM_ SG_ 1000 EPBR_a001_WatchdogReset "Right electric parking brake: a001 watchdog reset";
CM_ SG_ 1000 EPBR_a002_PowerLossReset "Right electric parking brake: a002 power loss reset";
CM_ SG_ 1000 EPBR_a003_SWAssertion "Right electric parking brake: a003 SW assertion";
CM_ SG_ 1000 EPBR_a005_CANTXError "Right electric parking brake: a005 CANTX error";
CM_ SG_ 1000 EPBR_a006_CANTX_cyclicError "Right electric parking brake: a006 CANTX cyclic error";
CM_ SG_ 1000 EPBR_a012_CPUReset "Right electric parking brake: a012 CPU reset";
CM_ SG_ 1000 EPBR_a013_AlertManagerFault "Right electric parking brake: a013 alert manager fault";
CM_ SG_ 1000 EPBR_a015_NVMMError "Right electric parking brake: a015 NVMM error";
CM_ SG_ 1000 EPBR_a016_NVMMRecordError "Right electric parking brake: a016 NVMM record error";
CM_ SG_ 1000 EPBR_a021_TaskSchedulerError "Right electric parking brake: a021 task scheduler error";
CM_ SG_ 1000 EPBR_a022_TaskInitError "Right electric parking brake: a022 task init error";
CM_ SG_ 1000 EPBR_a029_CoreDump "Right electric parking brake: a029 core dump";
CM_ SG_ 1000 EPBR_a030_ECULogUploadRequest "Right electric parking brake: a030 ECU log upload request";
CM_ SG_ 1000 EPBR_a031_UDSActive "Right electric parking brake: a031 UDS active";
CM_ SG_ 1000 EPBR_a041_HighCPULoad "Right electric parking brake: a041 high CPU load";
CM_ SG_ 1000 EPBR_a042_HighStackUsage "Right electric parking brake: a042 high stack usage";
CM_ SG_ 1000 EPBR_a043_Task1msError "Right electric parking brake: a043 task1ms error";
CM_ SG_ 1000 EPBR_a044_Task10msError "Right electric parking brake: a044 task10ms error";
CM_ SG_ 1000 EPBR_a045_Task100msError "Right electric parking brake: a045 task100ms error";
CM_ SG_ 1000 EPBR_a046_Task1000msError "Right electric parking brake: a046 task1000ms error";
CM_ SG_ 1000 EPBR_a057_HVP_MIA "Right electric parking brake: a057 HVP MIA";
CM_ SG_ 1000 EPBR_a058_inputRHighSyncDebug "Right electric parking brake: a058 input r high sync debug";
CM_ SG_ 1000 EPBR_a059_inputResistanceHigh "Right electric parking brake: a059 input resistance high";
CM_ SG_ 1000 EPBR_a060_engineeringBuild "Right electric parking brake: a060 engineering build";
CM_ SG_ 1000 EPBR_a061_XCPConnected "Right electric parking brake: a061 XCP connected";
CM_ SG_ 1000 EPBR_a062_XCPWasConnected "Right electric parking brake: a062 XCP was connected";
CM_ SG_ 1000 EPBR_a063_SwitchFault "Right electric parking brake: a063 switch fault";
CM_ SG_ 1000 EPBR_a064_busSleepReqTimeout "Right electric parking brake: a064 bus sleep req timeout";
CM_ SG_ 1000 EPBR_a081_APP_MIA "Right electric parking brake: a081 APP MIA";
CM_ SG_ 1000 EPBR_a082_VCRIGHT_IPC_MIA "Right electric parking brake: a082 VCRIGHT IPC MIA";
CM_ SG_ 1000 EPBR_a083_VCLEFT_IPC_MIA "Right electric parking brake: a083 VCLEFT IPC MIA";
CM_ SG_ 1000 EPBR_a084_TPMS_MIA "Right electric parking brake: a084 TPMS MIA";
CM_ SG_ 1000 EPBR_a085_CCCM_MIA "Right electric parking brake: a085 CCCM MIA";
CM_ SG_ 1000 EPBR_a086_VCBATT_MIA "Right electric parking brake: a086 VCBATT MIA";
CM_ SG_ 1000 EPBR_a087_DIREL_MIA "Right electric parking brake: a087 DIREL MIA";
CM_ SG_ 1000 EPBR_a088_DIRER_MIA "Right electric parking brake: a088 DIRER MIA";
CM_ SG_ 1000 EPBR_a089_IBST_MIA "Right electric parking brake: a089 IBST MIA";
CM_ SG_ 1000 EPBR_a090_APS_MIA "Right electric parking brake: a090 APS MIA";
CM_ SG_ 1000 EPBR_a091_CMPD_MIA "Right electric parking brake: a091 CMPD MIA";
CM_ SG_ 1000 EPBR_a092_VCSEATD_MIA "Right electric parking brake: a092 VCSEATD MIA";
CM_ SG_ 1000 EPBR_a093_VCSEATP_MIA "Right electric parking brake: a093 VCSEATP MIA";
CM_ SG_ 1000 EPBR_a094_EPAS3P_MIA "Right electric parking brake: a094 EPAS3 p MIA";
CM_ SG_ 1000 EPBR_a095_CHG_MIA "Right electric parking brake: a095 CHG MIA";
CM_ SG_ 1000 EPBR_a096_OCS1P_MIA "Right electric parking brake: a096 OCS1 p MIA";
CM_ SG_ 1000 EPBR_a097_CMP_MIA "Right electric parking brake: a097 CMP MIA";
CM_ SG_ 1000 EPBR_a098_DIR_MIA "Right electric parking brake: a098 DIR MIA";
CM_ SG_ 1000 EPBR_a099_PARK_MIA "Right electric parking brake: a099 PARK MIA";
CM_ SG_ 1000 EPBR_a100_CANbus_MIA "Right electric parking brake: a100 CA nbus MIA";
CM_ SG_ 1000 EPBR_a101_PM_MIA "Right electric parking brake: a101 PM MIA";
CM_ SG_ 1000 EPBR_a102_PTC_MIA "Right electric parking brake: a102 PTC MIA";
CM_ SG_ 1000 EPBR_a103_CP_MIA "Right electric parking brake: a103 CP MIA";
CM_ SG_ 1000 EPBR_a104_DAS_MIA "Right electric parking brake: a104 DAS MIA";
CM_ SG_ 1000 EPBR_a105_TAS_MIA "Right electric parking brake: a105 TAS MIA";
CM_ SG_ 1000 EPBR_a106_PCS_MIA "Right electric parking brake: a106 PCS MIA";
CM_ SG_ 1000 EPBR_a107_BMS_MIA "Right electric parking brake: a107 BMS MIA";
CM_ SG_ 1000 EPBR_a108_DIF_MIA "Right electric parking brake: a108 DIF MIA";
CM_ SG_ 1000 EPBR_a109_RCM_MIA "Right electric parking brake: a109 RCM MIA";
CM_ SG_ 1000 EPBR_a110_GTW_MIA "Right electric parking brake: a110 GTW MIA";
CM_ SG_ 1000 EPBR_a111_EPBR_MIA "Right electric parking brake: a111 EPBR MIA";
CM_ SG_ 1000 EPBR_a112_EPBL_MIA "Right electric parking brake: a112 EPBL MIA";
CM_ SG_ 1000 EPBR_a113_UI_MIA "Right electric parking brake: a113 UI MIA";
CM_ SG_ 1000 EPBR_a114_ESP_MIA "Right electric parking brake: a114 ESP MIA";
CM_ SG_ 1000 EPBR_a115_VCSEC_MIA "Right electric parking brake: a115 VCSEC MIA";
CM_ SG_ 1000 EPBR_a116_VCRIGHT_MIA "Right electric parking brake: a116 VCRIGHT MIA";
CM_ SG_ 1000 EPBR_a117_VCLEFT_MIA "Right electric parking brake: a117 VCLEFT MIA";
CM_ SG_ 1000 EPBR_a118_VCFRONT_MIA "Right electric parking brake: a118 VCFRONT MIA";
CM_ SG_ 1000 EPBR_a119_SCCM_MIA "Right electric parking brake: a119 SCCM MIA";
CM_ SG_ 1000 EPBR_a120_DI_DRIVE_MIA "Right electric parking brake: a120 DI DRIVE MIA";
CM_ SG_ 1000 EPBR_a121_nDriveFault "Right electric parking brake: a121 n drive fault";
CM_ SG_ 1000 EPBR_a122_Oc "Right electric parking brake: a122 oc";
CM_ SG_ 1000 EPBR_a123_Uc "Right electric parking brake: a123 uc";
CM_ SG_ 1000 EPBR_a124_calOutOfBounds "Right electric parking brake: a124 cal out of bounds";
CM_ SG_ 1000 EPBR_a125_IdleVMismatch "Right electric parking brake: a125 idle v mismatch";
CM_ SG_ 1000 EPBR_a126_MotorNVoltLow "Right electric parking brake: a126 motor n volt low";
CM_ SG_ 1000 EPBR_a127_MotorNVoltHigh "Right electric parking brake: a127 motor n volt high";
CM_ SG_ 1000 EPBR_a128_MotorPVoltHigh "Right electric parking brake: a128 motor p volt high";
CM_ SG_ 1000 EPBR_a129_ICR_MIA "Right electric parking brake: a129 ICR MIA";
CM_ SG_ 1000 EPBR_a130_BB_MIA "Right electric parking brake: a130 BB MIA";
CM_ SG_ 1000 EPBR_a131_RCU_MIA "Right electric parking brake: a131 RCU MIA";
CM_ SG_ 1000 EPBR_a132_VCBATT1_MIA "Right electric parking brake: a132 VCBATT1 MIA";
CM_ SG_ 1000 EPBR_a133_VCBATT2_MIA "Right electric parking brake: a133 VCBATT2 MIA";
CM_ SG_ 1000 EPBR_a134_NvOv "Right electric parking brake: a134 nv ov";
CM_ SG_ 1000 EPBR_a135_NvUv "Right electric parking brake: a135 nv uv";
CM_ SG_ 1000 EPBR_a136_PvOv "Right electric parking brake: a136 pv ov";
CM_ SG_ 1000 EPBR_a137_PvUv "Right electric parking brake: a137 pv uv";
CM_ SG_ 1000 EPBR_a138_NvmDualFailure "Right electric parking brake: a138 nvm dual failure";
CM_ SG_ 1000 EPBR_a139_NvmRedundancyLoss "Right electric parking brake: a139 nvm redundancy loss";
CM_ SG_ 1000 EPBR_a140_NvmSlowWrite "Right electric parking brake: a140 nvm slow write";
CM_ SG_ 1000 EPBR_a141_invalidState "Right electric parking brake: a141 invalid state";
CM_ SG_ 1000 EPBR_a170_12vOv "Right electric parking brake: a170 12v ov";
CM_ SG_ 1000 EPBR_a171_12vUv "Right electric parking brake: a171 12v uv";
CM_ SG_ 1000 EPBR_a172_SPI_MIA "Right electric parking brake: a172 SPI MIA";
CM_ SG_ 1000 EPBR_a173_hiCurrentMissing "Right electric parking brake: a173 hi current missing";
CM_ SG_ 1000 EPBR_a174_csmReleaseFailed "Right electric parking brake: a174 csm release failed";
CM_ SG_ 1000 EPBR_a175_csmReleaseRetry "Right electric parking brake: a175 csm release retry";
CM_ SG_ 1000 EPBR_a176_csmApplyFailed "Right electric parking brake: a176 csm apply failed";
CM_ SG_ 1000 EPBR_a177_csmApplyRetry "Right electric parking brake: a177 csm apply retry";
CM_ SG_ 1000 EPBR_a178_caliperStateUnknown "Right electric parking brake: a178 caliper state unknown";
CM_ SG_ 1000 EPBR_a179_epbProblem "Right electric parking brake: a179 epb problem";
CM_ SG_ 1000 EPBR_a180_dynamicActive "Right electric parking brake: a180 dynamic active";
CM_ SG_ 1000 EPBR_a181_TooSteepGradeToPark "Right electric parking brake: a181 too steep grade to park";
CM_ SG_ 1000 EPBR_a182_OneEPBAppliedUnsecEnv "Right electric parking brake: a182 one EPB applied unsec env";
CM_ SG_ 1000 EPBR_a183_cdpNotAvailable "Right electric parking brake: a183 cdp not available";
CM_ SG_ 1000 EPBR_a184_dynamicParkAbort "Right electric parking brake: a184 dynamic park abort";
CM_ SG_ 1000 EPBR_a185_summonAborted "Right electric parking brake: a185 summon aborted";
CM_ SG_ 1000 EPBR_a186_externalParkAbort "Right electric parking brake: a186 external park abort";
CM_ SG_ 1000 EPBR_a187_cdpDynamic "Right electric parking brake: a187 cdp dynamic";
CM_ SG_ 1000 EPBR_a188_epbDynamic "Right electric parking brake: a188 epb dynamic";
CM_ SG_ 1000 EPBR_a189_epbDynamicParkCanceled "Right electric parking brake: a189 epb dynamic park canceled";
CM_ SG_ 1000 EPBR_a190_csmApplyDegraded "Right electric parking brake: a190 csm apply degraded";
CM_ SG_ 1000 EPBR_a191_csmReleaseDegraded "Right electric parking brake: a191 csm release degraded";
CM_ SG_ 1000 EPBR_a195_parkForDriverIsLeaving "Right electric parking brake: a195 park for driver is leaving";
CM_ SG_ 1000 EPBR_a196_freeRollModeActive "Right electric parking brake: a196 free roll mode active";
CM_ SG_ 1000 EPBR_a197_freeRollModeAtSpeed "Right electric parking brake: a197 free roll mode at speed";
CM_ SG_ 1000 EPBR_a198_holdClampComplete "Right electric parking brake: a198 hold clamp complete";
CM_ SG_ 1000 EPBR_a200_PmUnparkNotAllowed "Right electric parking brake: a200 pm unpark not allowed";
CM_ SG_ 1000 EPBR_a202_remoteEpbConfigIncompa "Right electric parking brake: a202 remote epb config incompatible";
CM_ SG_ 1000 EPBR_a203_hwBrakeTypeMismatch "Right electric parking brake: a203 hw brake type mismatch";
CM_ SG_ 1000 EPBR_a210_parkForDriverIsLeaving "Right electric parking brake: a210 park for driver is leaving debug";
CM_ SG_ 1000 EPBR_a216_SPI_MIA_debugData1 "Right electric parking brake: a216 SPI MIA debug data1";
CM_ SG_ 1000 EPBR_a217_SPI_MIA_debugData2 "Right electric parking brake: a217 SPI MIA debug data2";
CM_ SG_ 1000 EPBR_a225_epbActiveDecel "Right electric parking brake: a225 epb active decel";
CM_ SG_ 1000 EPBR_a241_diOutputLocked "Right electric parking brake: a241 di output locked";
CM_ SG_ 1000 EPBR_a242_hvOutputLocked "Right electric parking brake: a242 hv output locked";
CM_ SG_ 1000 EPBR_a243_bdwUnavailable "Right electric parking brake: a243 bdw unavailable";
CM_ SG_ 1000 EPBR_a244_WinchModeActive "Right electric parking brake: a244 winch mode active";
CM_ SG_ 1000 EPBR_a245_serviceModeActive "Signal reported by Right electric parking brake";
CM_ SG_ 1000 EPBR_a246_idleFaultApply "Right electric parking brake: a246 idle fault apply";
CM_ SG_ 1000 EPBR_a247_csmDynamicApplyRetry "Right electric parking brake: a247 csm dynamic apply retry";
CM_ SG_ 1000 EPBR_a248_csmDynamicApplyFailed "Right electric parking brake: a248 csm dynamic apply failed";
CM_ SG_ 1000 EPBR_a249_idleFaultRelease "Right electric parking brake: a249 idle fault release";
CM_ SG_ 1000 EPBR_a250_WinchModeCanceled "Right electric parking brake: a250 winch mode canceled";
CM_ SG_ 1000 EPBR_a251_currentVarianceHigh "Right electric parking brake: a251 current variance high";
CM_ SG_ 1000 EPBR_a252_winchModePending "Right electric parking brake: a252 winch mode pending";
CM_ SG_ 1000 EPBR_a253_esmReleaseBlocked "Right electric parking brake: a253 esm release blocked";
CM_ SG_ 1000 EPBR_a254_showStalkParkButtonFau "Right electric parking brake: a254 show stalk park button fault on ui";
CM_ SG_ 1000 EPBR_a256_epbSystemApply "Right electric parking brake: a256 epb system apply";
CM_ SG_ 1000 EPBR_a261_winchModeWithoutSteeri "Right electric parking brake: a261 winch mode without steering";
CM_ SG_ 1000 EPBR_a262_cannotPrepareWinchMode "Right electric parking brake: a262 cannot prepare winch mode";
CM_ SG_ 1000 EPBR_a263_epbRecoveryPark "Right electric parking brake: a263 epb recovery park";
CM_ SG_ 1000 EPBR_a264_winchModeDeactivated "Right electric parking brake: a264 winch mode deactivated";
CM_ SG_ 1000 EPBR_a272_vhclPwrStateMsmtch "Right electric parking brake: a272 vhcl pwr state msmtch";
CM_ SG_ 1000 EPBR_a300_leftRightConfusion "Right electric parking brake: a300 left right confusion";
CM_ SG_ 1000 EPBR_a301_oocSpeedViolation "Right electric parking brake: a301 ooc speed violation";
CM_ SG_ 1000 EPBR_a302_csmLongRelease "Right electric parking brake: a302 csm long release";
CM_ SG_ 1000 EPBR_a303_clampingOccuredEarly "Right electric parking brake: a303 clamping occured early";
CM_ SG_ 1000 EPBR_a304_rearSeatControllerEFus "Right electric parking brake: a304 rear seat controller e fuse trip";
CM_ SG_ 1000 EPBR_a305_premiumAmpEFuseTrip "Right electric parking brake: a305 premium amp e fuse trip";
CM_ SG_ 1000 EPBR_a330_parkForApIsLeaving "Right electric parking brake: a330 park for ap is leaving";
CM_ SG_ 1000 EPBR_a350_ensOutOfRange "Right electric parking brake: a350 ens out of range";
CM_ SG_ 1000 EPBR_a352_audioCurrentSpikeData "Right electric parking brake: a352 audio current spike data";
CM_ SG_ 1000 EPBR_a353_missingSpeedUnableToPa "Right electric parking brake: a353 missing speed unable to park";
CM_ SG_ 1000 EPBR_a354_parkedForLowBrakeFluid "Right electric parking brake: a354 parked for low brake fluid mode";
CM_ SG_ 1000 EPBR_a355_brakeHwAndEpbHwMismatc "Right electric parking brake: a355 brake hw and epb hw mismatch";
CM_ SG_ 1000 EPBR_a356_parkingForStationaryDe "Right electric parking brake: a356 parking for stationary detect";
CM_ SG_ 1000 EPBR_a357_brakesTooHotForSlope "Right electric parking brake: a357 brakes too hot for slope";
CM_ SG_ 1000 EPBR_a358_brakesTooHotForSlopeWi "Right electric parking brake: a358 brakes too hot for slope with only one epb";
CM_ SG_ 1000 EPBR_a359_seat2RControllerTrip "Right electric parking brake: a359 seat2 r controller trip";
CM_ SG_ 1000 EPBR_a360_ibstBrakeSwitchInvalid "Right electric parking brake: a360 ibst brake switch invalid";
CM_ SG_ 1000 EPBR_a361_espBrakeSwitchInvalid "Right electric parking brake: a361 esp brake switch invalid";
CM_ SG_ 1000 EPBR_a362_ibstPressedEspNotPress "Right electric parking brake: a362 ibst pressed esp not pressed mismatch";
CM_ SG_ 1000 EPBR_a363_ibstNotPressedEspPress "Right electric parking brake: a363 ibst not pressed esp pressed mismatch";
CM_ SG_ 1000 EPBR_a364_espMasterCylCompOverTh "Right electric parking brake: a364 esp master cyl comp over threshold";
CM_ SG_ 1000 EPBR_a365_TooSteepToParkWithTrai "Right electric parking brake: a365 too steep to park with trailer warning";
CM_ SG_ 1000 EPBR_a366_TooSteepToParkWithTrai "Right electric parking brake: a366 too steep to park with trailer un sec env";
CM_ SG_ 1000 EPBR_a370_imposterDetected "Right electric parking brake: a370 imposter detected";
CM_ BO_ 2024 "Right electric parking brake message: info; frame length observed on a vehicle bus";
CM_ SG_ 2024 EPBR_infoIndex "Right electric parking brake: info index";
CM_ SG_ 2024 EPBR_infoBuildType "Right electric parking brake: info build type";
CM_ SG_ 2024 EPBR_infoBuildConfigId "Right electric parking brake: info build config id";
CM_ SG_ 2024 EPBR_infoHardwareId "Right electric parking brake: info hardware id";
CM_ SG_ 2024 EPBR_infoComponentId "Right electric parking brake: info component id";
CM_ SG_ 2024 EPBR_infoPcbaId "Right electric parking brake: info pcba id";
CM_ SG_ 2024 EPBR_infoAssemblyId "Right electric parking brake: info assembly id; raw 255 = signal not available (SNA)";
CM_ SG_ 2024 EPBR_infoUsageId "Right electric parking brake: info usage id";
CM_ SG_ 2024 EPBR_infoSubUsageId "Right electric parking brake: info sub usage id";
CM_ SG_ 2024 EPBR_infoAppCrc "Right electric parking brake: info app crc";
CM_ SG_ 2024 EPBR_infoAppGitHash "Right electric parking brake: info app git hash";
CM_ SG_ 2024 EPBR_infoBootGitHash "Right electric parking brake: info boot git hash";
CM_ SG_ 2024 EPBR_infoPlatformType "Right electric parking brake: info platform type";
CM_ SG_ 2024 EPBR_infoBootUdsProtoVersion "Right electric parking brake: info boot uds proto version";
CM_ SG_ 2024 EPBR_infoBootCrc "Right electric parking brake: info boot crc";
CM_ BO_ 552 "Right electric parking brake message: internal status; frame length observed on a vehicle bus";
CM_ SG_ 552 EPBR_unitStatus "Electronic Parking Brake's unit state.";
CM_ SG_ 552 EPBR_unitFaultStatus "Right electric parking brake: unit fault status";
CM_ SG_ 552 EPBR_summonState "Right electric parking brake: summon state";
CM_ SG_ 552 EPBR_disconnected "Right electric parking brake: disconnected";
CM_ SG_ 552 EPBR_pistonTouchingRotor "Right electric parking brake: piston touching rotor";
CM_ SG_ 552 EPBR_csmFaultReason "Right electric parking brake: csm fault reason";
CM_ SG_ 552 EPBR_esmOperationTrigger "Right electric parking brake: esm operation trigger";
CM_ SG_ 552 EPBR_summonFaultReason "Error code associated with previous summon failure.";
CM_ SG_ 552 EPBR_localServiceModeActive "Signal reported by Right electric parking brake";
CM_ SG_ 552 EPBR_localCdpState "Right electric parking brake: local cdp state";
CM_ SG_ 552 EPBR_chimeRequestLocal "Right electric parking brake: chime request local";
CM_ SG_ 552 EPBR_telltaleLocal "Right electric parking brake: telltale local; raw 7 = signal not available (SNA)";
CM_ SG_ 552 EPBR_driverIsLeavingLocal "Right electric parking brake: driver is leaving local";
CM_ SG_ 552 EPBR_driverIsLeavingAnySpeedLoca "Right electric parking brake: driver is leaving any speed local";
CM_ SG_ 552 EPBR_internalCDPRequest "Right electric parking brake: internal CDP request";
CM_ SG_ 552 EPBR_esmSpeedClass "Right electric parking brake: esm speed class";
CM_ SG_ 552 EPBR_learnedEpbConfig "Right electric parking brake: learned epb config";
CM_ SG_ 552 EPBR_internalStatusCounter "Right electric parking brake: internal status counter";
CM_ SG_ 552 EPBR_internalStatusChecksum "Right electric parking brake: internal status checksum";
CM_ BO_ 742 "Right electric parking brake message: seat status3; frame length from the layout, not yet observed on a vehicle bus";
CM_ SG_ 742 EPBR_frontSeatCushionFanCur "Right electric parking brake: front seat cushion fan cur";
CM_ SG_ 742 EPBR_frontSeatBackrestFanCur "Right electric parking brake: front seat backrest fan cur";
CM_ SG_ 742 EPBR_frontSeatCushionFanDuty "Right electric parking brake: front seat cushion fan duty";
CM_ SG_ 742 EPBR_frontSeatCushionFanEn "Right electric parking brake: front seat cushion fan en";
CM_ SG_ 742 EPBR_frontSeatBackrestFanEn "Right electric parking brake: front seat backrest fan en";
CM_ SG_ 742 EPBR_frontSeatBackrestFanDuty "Right electric parking brake: front seat backrest fan duty";
CM_ SG_ 742 EPBR_seat2RControllerCurrent "Right electric parking brake: seat2 r controller current";
CM_ BO_ 744 "Right electric parking brake message: status; frame length observed on a vehicle bus";
CM_ SG_ 744 EPBR_systemStatus "Coordinated state representing the vehicle level parking brake state.";
CM_ SG_ 744 EPBR_freeRollModeStatus "Right electric parking brake: free roll mode status";
CM_ SG_ 744 EPBR_driverIsLeaving "Right electric parking brake: driver is leaving";
CM_ SG_ 744 EPBR_driverIsLeavingAnySpeed "Right electric parking brake: driver is leaving any speed";
CM_ SG_ 744 EPBR_systemCdpAvailable "Right electric parking brake: system cdp available";
CM_ SG_ 744 EPBR_chimeRequest "Right electric parking brake: chime request";
CM_ SG_ 744 EPBR_telltale "Controls the telltale illumination on the instrument cluster; raw 7 = signal not available (SNA)";
CM_ SG_ 744 EPBR_audioCurrentSpikeDetected "Right electric parking brake: audio current spike detected";
CM_ SG_ 744 EPBR_redundantBrakingEnabled "Right electric parking brake: redundant braking enabled";
CM_ SG_ 744 EPBR_summonEnabled "Right electric parking brake: summon enabled";
CM_ SG_ 744 EPBR_brakeLight "Right electric parking brake: brake light";
CM_ SG_ 744 EPBR_epbConfigMismatch "Right electric parking brake: epb config mismatch";
CM_ SG_ 744 EPBR_brakeConfirmedPressed "Right electric parking brake: brake confirmed pressed";
CM_ SG_ 744 EPBR_requestUserConfirmation "Right electric parking brake: request user confirmation";
CM_ SG_ 744 EPBR_uiWinchModeMiscBlocking "Reports the expected appearance of system error message on User Interface (UI) winch mode panel.";
CM_ SG_ 744 EPBR_winchModeActive "Right electric parking brake: winch mode active";
CM_ SG_ 744 EPBR_updateMode "Right electric parking brake: update mode";
CM_ SG_ 744 EPBR_winchModePermissive "Right electric parking brake: winch mode permissive";
CM_ SG_ 744 EPBR_winchModePending "Right electric parking brake: winch mode pending";
CM_ SG_ 744 EPBR_cdpRequest "Right electric parking brake: cdp request";
CM_ SG_ 744 EPBR_uiParkAvailable "Reports the expected availability and appearance of the park button on User Interface (UI) safety panel.";
CM_ SG_ 744 EPBR_brakeDiscWipeRequest "Right electric parking brake: brake disc wipe request; raw 3 = signal not available (SNA)";
CM_ SG_ 744 EPBR_showUiGearShifter "Right electric parking brake: show ui gear shifter";
CM_ SG_ 744 EPBR_uiWinchModeLvStatus "Reports the expected availability and appearance of Low Voltage (LV) system status on UI winch mode panel.";
CM_ SG_ 744 EPBR_contactorCycleNotNeededForW "Right electric parking brake: contactor cycle not needed for winch entry";
CM_ SG_ 744 EPBR_autonomyBehavior "Right electric parking brake: autonomy behavior";
CM_ SG_ 744 EPBR_showStalkFaultedOnUi "Right electric parking brake: show stalk faulted on ui";
CM_ SG_ 744 EPBR_espPowerRequest "Right electric parking brake: esp power request";
CM_ SG_ 744 EPBR_okToPark "Right electric parking brake: ok to park";
CM_ SG_ 744 EPBR_hornRequest "Right electric parking brake: horn request";
CM_ SG_ 744 EPBR_winchModeAvailable "Right electric parking brake: winch mode available";
CM_ SG_ 744 EPBR_bothDisconnected "Right electric parking brake: both disconnected";
CM_ SG_ 744 EPBR_blockDrive "Right electric parking brake: block drive";
CM_ SG_ 744 EPBR_statusCounter "Right electric parking brake: status counter";
CM_ SG_ 744 EPBR_statusChecksum "Right electric parking brake: status checksum";
CM_ BO_ 1575 "Right electric parking brake message: uds response; frame length from the layout, not yet observed on a vehicle bus";
CM_ SG_ 1575 EPBR_udsResponseData_H "Right electric parking brake: uds response data h";
CM_ SG_ 1575 EPBR_udsResponseData_L "Right electric parking brake: uds response data l";
CM_ BO_ 1662 "EVSE ECU message: iso tp to veh; frame length from the layout, not yet observed on a vehicle bus";
CM_ SG_ 1662 EVSE_isoTpToVehData "EVSE ECU: iso tp to veh data";
CM_ BO_ 1322 "FC ECU message: alert log; frame length from the layout, not yet observed on a vehicle bus";
CM_ SG_ 1322 FC_alertID "FC ECU: alert ID";
CM_ SG_ 1322 FC_alertType "FC ECU: alert type";
CM_ SG_ 1322 FC_a130_CA_flybackSwOvType "FC ECU: a130 CA flyback sw ov type";
CM_ SG_ 1322 FC_a146_CA_flybackOnTime "FC ECU: a146 CA flyback on time";
CM_ SG_ 1322 FC_a146_CA_flybackV "FC ECU: a146 CA flyback v";
CM_ SG_ 1322 FC_a146_CA_flybackTargetV "FC ECU: a146 CA flyback target v";
CM_ SG_ 1322 FC_a159_CA_wdtTaskList1 "FC ECU: a159 CA wdt task list1";
CM_ SG_ 1322 FC_a159_CA_wdtTaskList2 "FC ECU: a159 CA wdt task list2";
CM_ BO_ 895 "FC ECU message: alert matrix3; frame length from the layout, not yet observed on a vehicle bus";
CM_ SG_ 895 FC_a129_CA_flyback_HW_OC "FC ECU: a129 CA flyback HW OC";
CM_ SG_ 895 FC_a130_CA_flyback_SW_OV "FC ECU: a130 CA flyback SW OV";
CM_ SG_ 895 FC_a131_CA_flyback_HW_OV "FC ECU: a131 CA flyback HW OV";
CM_ SG_ 895 FC_a132_CA_bmsMia "FC ECU: a132 CA bms mia";
CM_ SG_ 895 FC_a133_CA_evseMia "FC ECU: a133 CA evse mia";
CM_ SG_ 895 FC_a134_CA_vehTxBufOvf "FC ECU: a134 CA veh tx buf ovf";
CM_ SG_ 895 FC_a135_CA_vehRxBufOvf "FC ECU: a135 CA veh rx buf ovf";
CM_ SG_ 895 FC_a136_CA_evseTxBufOvf "FC ECU: a136 CA evse tx buf ovf";
CM_ SG_ 895 FC_a137_CA_evseRxBufOvf "FC ECU: a137 CA evse rx buf ovf";
CM_ SG_ 895 FC_a138_CA_hwProxTrip "FC ECU: a138 CA hw prox trip";
CM_ SG_ 895 FC_a139_CA_ss2NotLow "FC ECU: a139 CA ss2 not low";
CM_ SG_ 895 FC_a140_CA_bmsIncompatible "FC ECU: a140 CA bms incompatible";
CM_ SG_ 895 FC_a141_CA_vehConn_OT "FC ECU: a141 CA veh conn OT";
CM_ SG_ 895 FC_a142_CA_evseConn_OT "FC ECU: a142 CA evse conn OT";
CM_ SG_ 895 FC_a143_CA_pcb_OT "FC ECU: a143 CA pcb OT";
CM_ SG_ 895 FC_a144_CA_flybackUnstable "FC ECU: a144 CA flyback unstable";
CM_ SG_ 895 FC_a145_CA_flybackDataStale "FC ECU: a145 CA flyback data stale";
CM_ SG_ 895 FC_a146_CA_flybackBusLoadHi "FC ECU: a146 CA flyback bus load hi";
CM_ SG_ 895 FC_a147_CA_vehConn_UT "FC ECU: a147 CA veh conn UT";
CM_ SG_ 895 FC_a148_CA_evseConn_UT "FC ECU: a148 CA evse conn UT";
CM_ SG_ 895 FC_a149_CA_pcb_UT "FC ECU: a149 CA pcb UT";
CM_ SG_ 895 FC_a150_CA_vehToEvseDeltaHi "FC ECU: a150 CA veh to evse delta hi";
CM_ SG_ 895 FC_a151_CA_vehToEvseDeltaLo "FC ECU: a151 CA veh to evse delta lo";
CM_ SG_ 895 FC_a152_CA_vehToPcbDeltaHi "FC ECU: a152 CA veh to pcb delta hi";
CM_ SG_ 895 FC_a153_CA_evseToPcbDeltaHi "FC ECU: a153 CA evse to pcb delta hi";
CM_ SG_ 895 FC_a154_CA_vehToPcbDeltaLo "FC ECU: a154 CA veh to pcb delta lo";
CM_ SG_ 895 FC_a155_CA_evseToPcbDeltaLo "FC ECU: a155 CA evse to pcb delta lo";
CM_ SG_ 895 FC_a156_CA_flybackRunTimeout "FC ECU: a156 CA flyback run timeout";
CM_ SG_ 895 FC_a157_CA_unused "FC ECU: a157 CA unused";
CM_ SG_ 895 FC_a158_CA_evseOverCurrent "FC ECU: a158 CA evse over current";
CM_ SG_ 895 FC_a159_CA_wdtExpired "FC ECU: a159 CA wdt expired";
CM_ SG_ 895 FC_a160_CA_ss2Deasserted "FC ECU: a160 CA ss2 deasserted";
CM_ SG_ 895 FC_a161_CA_vehTempHiFoldBk "FC ECU: a161 CA veh temp hi fold bk";
CM_ SG_ 895 FC_a162_CA_evseTempHiFoldBk "FC ECU: a162 CA evse temp hi fold bk";
CM_ SG_ 895 FC_a163_CA_pcbTempHiFoldBk "FC ECU: a163 CA pcb temp hi fold bk";
CM_ SG_ 895 FC_a164_CA_proxDisconnected "FC ECU: a164 CA prox disconnected";
CM_ SG_ 895 FC_a165_CA_evseConnUnlocked "FC ECU: a165 CA evse conn unlocked";
CM_ SG_ 895 FC_a166_CA_vehConnUnlocked "FC ECU: a166 CA veh conn unlocked";
CM_ SG_ 895 FC_a167_CA_isoVoltageLow "FC ECU: a167 CA iso voltage low";
CM_ SG_ 895 FC_a168_CA_proxTimeout "FC ECU: a168 CA prox timeout";
CM_ SG_ 895 FC_a169_CA_pilotAcceptTimeout "FC ECU: a169 CA pilot accept timeout";
CM_ SG_ 895 FC_a170_CA_vehDataTimeout "FC ECU: a170 CA veh data timeout";
CM_ SG_ 895 FC_a171_CA_vehConLockTimeout "FC ECU: a171 CA veh con lock timeout";
CM_ SG_ 895 FC_a172_CA_ss2LowTimeout "FC ECU: a172 CA ss2 low timeout";
CM_ SG_ 895 FC_a173_CA_evseDataTimeout "FC ECU: a173 CA evse data timeout";
CM_ SG_ 895 FC_a174_CA_vehReadyTimeout "FC ECU: a174 CA veh ready timeout";
CM_ SG_ 895 FC_a175_CA_evseIsoTestTimeout "FC ECU: a175 CA evse iso test timeout";
CM_ SG_ 895 FC_a176_CA_chargingBusTimeout "FC ECU: a176 CA charging bus timeout";
CM_ SG_ 895 FC_a177_CA_bmsCtrCloseTimeout "FC ECU: a177 CA bms ctr close timeout";
CM_ SG_ 895 FC_a178_CA_evseStartTimeout "FC ECU: a178 CA evse start timeout";
CM_ SG_ 895 FC_a179_CA_startupProblem "FC ECU: a179 CA startup problem";
CM_ SG_ 895 FC_a180_CA_chargingProblem "FC ECU: a180 CA charging problem";
CM_ SG_ 895 FC_a181_CA_vRegBrownout "FC ECU: a181 CA v reg brownout";
CM_ SG_ 895 FC_a182_CA_evseChrMalfunc "FC ECU: a182 CA evse chr malfunc";
CM_ SG_ 895 FC_a183_CA_evseBatIncompat "FC ECU: a183 CA evse bat incompat";
CM_ SG_ 895 FC_a184_CA_evseBatMalfunc "FC ECU: a184 CA evse bat malfunc";
CM_ SG_ 895 FC_a185_CA_vehReadyDeasserted "FC ECU: a185 CA veh ready deasserted";
CM_ SG_ 895 FC_a186_CA_fcContOpenTimeout "FC ECU: a186 CA fc cont open timeout";
CM_ SG_ 895 FC_a187_CA_evseConLockTimeout "FC ECU: a187 CA evse con lock timeout";
CM_ BO_ 927 "FC ECU message: alert matrix4; frame length from the layout, not yet observed on a vehicle bus";
CM_ SG_ 927 FC_a193_FCAlertPlaceholder "FC ECU: a193 FC alert placeholder";
CM_ BO_ 958 "FC ECU message: alert matrix5; frame length from the layout, not yet observed on a vehicle bus";
CM_ SG_ 958 FC_a257_GB_bmsMia "FC ECU: a257 GB bms mia";
CM_ SG_ 958 FC_a258_GB_evseMia "FC ECU: a258 GB evse mia";
CM_ SG_ 958 FC_a259_GB_vehTxBufOvf "FC ECU: a259 GB veh tx buf ovf";
CM_ SG_ 958 FC_a260_GB_vehRxBufOvf "FC ECU: a260 GB veh rx buf ovf";
CM_ SG_ 958 FC_a261_GB_evseTxBufOvf "FC ECU: a261 GB evse tx buf ovf";
CM_ SG_ 958 FC_a262_GB_evseRxBufOvf "FC ECU: a262 GB evse rx buf ovf";
CM_ SG_ 958 FC_a263_GB_hwProxTrip "FC ECU: a263 GB hw prox trip";
CM_ SG_ 958 FC_a264_GB_timeoutCHM "FC ECU: a264 GB timeout CHM";
CM_ SG_ 958 FC_a265_GB_bmsIncompatible "FC ECU: a265 GB bms incompatible";
CM_ SG_ 958 FC_a266_GB_negPin_OT "FC ECU: a266 GB neg pin OT";
CM_ SG_ 958 FC_a267_GB_posPin_OT "FC ECU: a267 GB pos pin OT";
CM_ SG_ 958 FC_a268_GB_pcb_OT "FC ECU: a268 GB pcb OT";
CM_ SG_ 958 FC_a269_GB_timeoutCRM "FC ECU: a269 GB timeout CRM";
CM_ SG_ 958 FC_a270_GB_timeoutCML "FC ECU: a270 GB timeout CML";
CM_ SG_ 958 FC_a271_GB_timeoutCRO "FC ECU: a271 GB timeout CRO";
CM_ SG_ 958 FC_a272_GB_negToPosDeltaHi "FC ECU: a272 GB neg to pos delta hi";
CM_ SG_ 958 FC_a273_GB_negToPosDeltaLo "FC ECU: a273 GB neg to pos delta lo";
CM_ SG_ 958 FC_a274_GB_negToPcbDeltaHi "FC ECU: a274 GB neg to pcb delta hi";
CM_ SG_ 958 FC_a275_GB_posToPcbDeltaHi "FC ECU: a275 GB pos to pcb delta hi";
CM_ SG_ 958 FC_a276_GB_negToPcbDeltaLo "FC ECU: a276 GB neg to pcb delta lo";
CM_ SG_ 958 FC_a277_GB_posToPcbDeltaLo "FC ECU: a277 GB pos to pcb delta lo";
CM_ SG_ 958 FC_a278_GB_timeoutCCS "FC ECU: a278 GB timeout CCS";
CM_ SG_ 958 FC_a279_GB_evseOverCurrent "FC ECU: a279 GB evse over current";
CM_ SG_ 958 FC_a280_GB_retryLimitExceeded "FC ECU: a280 GB retry limit exceeded";
CM_ SG_ 958 FC_a281_GB_evseOutOfService "FC ECU: a281 GB evse out of service";
CM_ SG_ 958 FC_a282_GB_negTempHiFoldBk "FC ECU: a282 GB neg temp hi fold bk";
CM_ SG_ 958 FC_a283_GB_posTempHiFoldBk "FC ECU: a283 GB pos temp hi fold bk";
CM_ SG_ 958 FC_a284_GB_pcbTempHiFoldBk "FC ECU: a284 GB pcb temp hi fold bk";
CM_ SG_ 958 FC_a285_GB_proxDisconnected "FC ECU: a285 GB prox disconnected";
CM_ SG_ 958 FC_a286_GB_evseConnUnlocked "FC ECU: a286 GB evse conn unlocked";
CM_ SG_ 958 FC_a287_GB_vehConnUnlocked "FC ECU: a287 GB veh conn unlocked";
CM_ SG_ 958 FC_a288_GB_evseAbnormalStopReq "FC ECU: a288 GB evse abnormal stop req";
CM_ SG_ 958 FC_a289_GB_proxTimeout "FC ECU: a289 GB prox timeout";
CM_ SG_ 958 FC_a290_GB_pilotAcceptTimeout "FC ECU: a290 GB pilot accept timeout";
CM_ SG_ 958 FC_a291_GB_vehDataTimeout "FC ECU: a291 GB veh data timeout";
CM_ SG_ 958 FC_a292_GB_vehConLockTimeout "FC ECU: a292 GB veh con lock timeout";
CM_ SG_ 958 FC_a293_GB_proxRationality "FC ECU: a293 GB prox rationality";
CM_ SG_ 958 FC_a294_GB_unused "FC ECU: a294 GB unused";
CM_ SG_ 958 FC_a295_GB_pilotRationality "FC ECU: a295 GB pilot rationality";
CM_ SG_ 958 FC_a296_GB_invalidPilotTransitio "FC ECU: a296 GB invalid pilot transitio";
CM_ SG_ 958 FC_a297_GB_unused "FC ECU: a297 GB unused";
CM_ SG_ 958 FC_a298_GB_bmsCtrCloseTimeout "FC ECU: a298 GB bms ctr close timeout";
CM_ SG_ 958 FC_a299_GB_evseReadyTimeout "FC ECU: a299 GB evse ready timeout";
CM_ SG_ 958 FC_a300_GB_unused "FC ECU: a300 GB unused";
CM_ SG_ 958 FC_a301_GB_unused "FC ECU: a301 GB unused";
CM_ SG_ 958 FC_a302_GB_unused "FC ECU: a302 GB unused";
CM_ SG_ 958 FC_a303_GB_negRecogTimeout "FC ECU: a303 GB neg recog timeout";
CM_ SG_ 958 FC_a304_GB_unused "FC ECU: a304 GB unused";
CM_ SG_ 958 FC_a305_GB_posRecogTimeout "FC ECU: a305 GB pos recog timeout";
CM_ SG_ 958 FC_a306_GB_vehReadyDeasserted "FC ECU: a306 GB veh ready deasserted";
CM_ SG_ 958 FC_a307_GB_fcContOpenTimeout "FC ECU: a307 GB fc cont open timeout";
CM_ SG_ 958 FC_a308_GB_evseConLockTimeout "FC ECU: a308 GB evse con lock timeout";
CM_ SG_ 958 FC_a309_GB_unused "FC ECU: a309 GB unused";
CM_ SG_ 958 FC_a310_GB_unused "FC ECU: a310 GB unused";
CM_ SG_ 958 FC_a311_GB_battParamsTimeout "FC ECU: a311 GB batt params timeout";
CM_ SG_ 958 FC_a312_GB_evseLimitsTimeout "FC ECU: a312 GB evse limits timeout";
CM_ SG_ 958 FC_a313_GB_inputVoltageRailOv "FC ECU: a313 GB input voltage rail ov";
CM_ BO_ 990 "FC ECU message: alert matrix6; frame length from the layout, not yet observed on a vehicle bus";
CM_ SG_ 990 FC_a321_FCAlertPlaceholder "FC ECU: a321 FC alert placeholder";
CM_ BO_ 1117 "FC ECU message: evse billing; frame length from the layout, not yet observed on a vehicle bus";
CM_ SG_ 1117 FC_evseBillingDataSelect "FC ECU: evse billing data select";
CM_ SG_ 1117 FC_evseBillingEnergy "FC ECU: evse billing energy";
CM_ SG_ 1117 FC_evseMeterPower "FC ECU: evse meter power";
CM_ SG_ 1117 FC_evseMeterCurrent "FC ECU: evse meter current";
CM_ SG_ 1117 FC_evseMeterVoltage "FC ECU: evse meter voltage";
CM_ SG_ 1117 FC_evseMeterFwGitHash "FC ECU: evse meter fw git hash";
CM_ BO_ 1334 "FC ECU message: evse billing2; frame length from the layout, not yet observed on a vehicle bus";
CM_ SG_ 1334 FC_evseBilling2DataSelect "FC ECU: evse billing2 data select";
CM_ SG_ 1334 FC_evsePpuEnabled "FC ECU: evse ppu enabled";
CM_ SG_ 1334 FC_evseBillingEnergyHighRes "FC ECU: evse billing energy high res; raw 16777215 = signal not available (SNA)";
CM_ BO_ 1303 "FC ECU message: identifier; frame length from the layout, not yet observed on a vehicle bus";
CM_ SG_ 1303 FC_id "Fast charger identifying number";
CM_ SG_ 1303 FC_sessionId "Fast charge session ID";
CM_ BO_ 1310 "FC ECU message: info; frame length from the layout, not yet observed on a vehicle bus";
CM_ SG_ 1310 FC_infoIndex "FC ECU: info index";
CM_ SG_ 1310 FC_infoBuildType "FC ECU: info build type";
CM_ SG_ 1310 FC_infoBuildConfigID "FC ECU: info build config ID";
CM_ SG_ 1310 FC_infoHardwareID "FC ECU: info hardware ID";
CM_ SG_ 1310 FC_infoComponentID "FC ECU: info component ID";
CM_ SG_ 1310 FC_infoPcbaID "FC ECU: info pcba ID";
CM_ SG_ 1310 FC_infoAssemblyID "FC ECU: info assembly ID";
CM_ SG_ 1310 FC_infoUsageID "FC ECU: info usage ID";
CM_ SG_ 1310 FC_infoSubUsageID "FC ECU: info sub usage ID";
CM_ SG_ 1310 FC_infoApplicationCRC "FC ECU: info application CRC";
CM_ SG_ 1310 FC_infoBootSvnRev "Position from firmware; message assignment inferred.";
CM_ SG_ 1310 FC_infoCPLDVersionMajor "Position from firmware; message assignment inferred.";
CM_ SG_ 1310 FC_infoCPLDVersionMinor "Position from firmware; message assignment inferred.";
CM_ SG_ 1310 FC_infoAppGitHashBytes "FC ECU: info app git hash bytes";
CM_ SG_ 1310 FC_infoBootGitHashBytes "FC ECU: info boot git hash bytes";
CM_ SG_ 1310 FC_infoPlatformType "FC ECU: info platform type";
CM_ SG_ 1310 FC_infoMajorVersion "Fast charger firmware major version number";
CM_ SG_ 1310 FC_infoBranchOrigin "Fast charger branch origin";
CM_ SG_ 1310 FC_infoMaturity "Fast charger firmware info";
CM_ SG_ 1310 FC_infoHardwareRevision "FC ECU: info hardware revision";
CM_ SG_ 1310 FC_infoBootUdsProtoVersion "Position from firmware; message assignment inferred.";
CM_ SG_ 1310 FC_partNumChar01 "FC ECU: part num char01";
CM_ SG_ 1310 FC_partNumChar02 "FC ECU: part num char02";
CM_ SG_ 1310 FC_partNumChar03 "FC ECU: part num char03";
CM_ SG_ 1310 FC_partNumChar04 "FC ECU: part num char04";
CM_ SG_ 1310 FC_partNumChar05 "FC ECU: part num char05";
CM_ SG_ 1310 FC_partNumChar06 "FC ECU: part num char06";
CM_ SG_ 1310 FC_partNumChar07 "FC ECU: part num char07";
CM_ SG_ 1310 FC_partNumChar08 "FC ECU: part num char08";
CM_ SG_ 1310 FC_partNumChar09 "FC ECU: part num char09";
CM_ SG_ 1310 FC_partNumChar10 "FC ECU: part num char10";
CM_ SG_ 1310 FC_partNumChar11 "FC ECU: part num char11";
CM_ SG_ 1310 FC_partNumChar12 "FC ECU: part num char12";
CM_ SG_ 1310 FC_partNumChar13 "FC ECU: part num char13";
CM_ SG_ 1310 FC_partNumChar14 "FC ECU: part num char14";
CM_ SG_ 1310 FC_partNumChar15 "FC ECU: part num char15";
CM_ SG_ 1310 FC_partNumChar16 "FC ECU: part num char16";
CM_ SG_ 1310 FC_partNumChar17 "FC ECU: part num char17";
CM_ SG_ 1310 FC_partNumChar18 "FC ECU: part num char18";
CM_ SG_ 1310 FC_partNumChar19 "FC ECU: part num char19";
CM_ SG_ 1310 FC_partNumChar20 "FC ECU: part num char20";
CM_ BO_ 580 "FC ECU message: limits; frame length from the layout, not yet observed on a vehicle bus";
CM_ SG_ 580 FC_powerLimit "Instantaneous power charger can deliver; raw 8191 = signal not available (SNA)";
CM_ SG_ 580 FC_currentLimit "Instantaneous current charger can deliver; raw 8191 = signal not available (SNA)";
CM_ SG_ 580 FC_maxVoltageLimit "Max voltage charger can deliver. 600/65536; raw 8191 = signal not available (SNA)";
CM_ SG_ 580 FC_minVoltageLimit "Measures Electric Vehicle Supply Equipment (EVSE) minimum current limit; raw 8191 = signal not available (SNA)";
CM_ BO_ 702 "FC ECU message: limits high power; frame length from the layout, not yet observed on a vehicle bus";
CM_ SG_ 702 FC_powerLimit_value "Instantaneous power charger can deliver. Mantissa portion of extended range version of legacy signal, used with protocol versions 9+. FC_powerLimit = value * 10^exp; raw 32768 = signal not available (SNA)";
CM_ SG_ 702 FC_currentLimit_value "FC ECU: current limit value; raw 32768 = signal not available (SNA)";
CM_ SG_ 702 FC_minVoltageLimit_value "FC ECU: min voltage limit value; raw 32768 = signal not available (SNA)";
CM_ SG_ 702 FC_powerLimit_exp "Instantaneous power charger can deliver. Exponent portion of extended ragne version of legacy signal, used with protocol versions 9+. FC_powerLimit = value * 10^exp.";
CM_ SG_ 702 FC_currentLimit_exp "FC ECU: current limit exp";
CM_ SG_ 702 FC_minVoltageLimit_exp "FC ECU: min voltage limit exp";
CM_ BO_ 1345 "FC ECU message: max limits; frame length from the layout, not yet observed on a vehicle bus";
CM_ SG_ 1345 FC_maxPowerLimit "Max power charger can deliver; raw 8191 = signal not available (SNA)";
CM_ SG_ 1345 FC_maxCurrentLimit "Max current charger can deliver; raw 8191 = signal not available (SNA)";
CM_ BO_ 1300 "FC ECU message: serial; frame length from the layout, not yet observed on a vehicle bus";
CM_ SG_ 1300 FC_serialDataSelect "FC ECU: serial data select";
CM_ SG_ 1300 FC_serialChar01 "FC ECU: serial char01";
CM_ SG_ 1300 FC_serialChar02 "FC ECU: serial char02";
CM_ SG_ 1300 FC_serialChar03 "FC ECU: serial char03";
CM_ SG_ 1300 FC_serialChar04 "FC ECU: serial char04";
CM_ SG_ 1300 FC_serialChar05 "FC ECU: serial char05";
CM_ SG_ 1300 FC_serialChar06 "FC ECU: serial char06";
CM_ SG_ 1300 FC_serialChar07 "FC ECU: serial char07";
CM_ SG_ 1300 FC_serialChar08 "FC ECU: serial char08";
CM_ SG_ 1300 FC_serialChar09 "FC ECU: serial char09";
CM_ SG_ 1300 FC_serialChar10 "FC ECU: serial char10";
CM_ SG_ 1300 FC_serialChar11 "FC ECU: serial char11";
CM_ SG_ 1300 FC_serialChar12 "FC ECU: serial char12";
CM_ SG_ 1300 FC_serialChar13 "FC ECU: serial char13";
CM_ SG_ 1300 FC_serialChar14 "FC ECU: serial char14";
CM_ SG_ 1300 FC_serialChar15 "FC ECU: serial char15";
CM_ SG_ 1300 FC_serialChar16 "FC ECU: serial char16";
CM_ SG_ 1300 FC_serialChar17 "FC ECU: serial char17";
CM_ BO_ 532 "FC ECU message: status; frame length from the layout, not yet observed on a vehicle bus";
CM_ SG_ 532 FC_protocolVersion "FC ECU: protocol version";
CM_ SG_ 532 FC_statusCode "Fast charger status code; raw 0 = signal not available (SNA)";
CM_ SG_ 532 FC_deprecated1 "FC ECU: deprecated1";
CM_ SG_ 532 FC_deprecated2 "FC ECU: deprecated2";
CM_ SG_ 532 FC_deprecated3 "FC ECU: deprecated3";
CM_ SG_ 532 FC_adapterLocked "Indicates if the DC adapter is secure or not";
CM_ SG_ 532 FC_minCurrentLimit "Fast charger min current limit";
CM_ SG_ 532 FC_type "Type of EVSE connected that supports digital communication; raw 7 = signal not available (SNA)";
CM_ SG_ 532 FC_dcCurrent "Fast charger DC output current";
CM_ SG_ 532 FC_postID "Fast charger charging post ID; raw 3 = signal not available (SNA)";
CM_ SG_ 532 FC_dcVoltage "Fast charger DC voltage";
CM_ SG_ 532 FC_leakageTestNotSupported "Indicates if the S/X leakage test can be run on this supercharger";
CM_ SG_ 532 FC_dischargeSupported "FC ECU: discharge supported";
CM_ BO_ 533 "FC ECU message: status2; frame length from the layout, not yet observed on a vehicle bus";
CM_ SG_ 533 FC_externalIsolationResistance "Fast charger external isolation resistance; raw 255 = signal not available (SNA)";
CM_ BO_ 535 "FC ECU message: status3; frame length from the layout, not yet observed on a vehicle bus";
CM_ SG_ 535 FC_status3DataSelect "FC ECU: status3 data select";
CM_ SG_ 535 FC_status3DummySig "FC ECU: status3 dummy sig";
CM_ SG_ 535 FC_class "FC ECU: class; raw 0 = signal not available (SNA)";
CM_ SG_ 535 FC_brand "Fast charger brand; raw 0 = signal not available (SNA)";
CM_ SG_ 535 FC_coolingType "Type of cooling used for the supercharger; raw 0 = signal not available (SNA)";
CM_ SG_ 535 FC_uiStopType "Type of stop type supported from the UI; raw 0 = signal not available (SNA)";
CM_ SG_ 535 FC_emergencyShutdownSupported "Indicates if the supercharger supports fast emergency shutdown requests from vehicle";
CM_ SG_ 535 FC_generation "Hardware generation of the Tesla EVSE; raw 0 = signal not available (SNA)";
CM_ SG_ 535 FC_billingEnergy "Total billable charge energy (integrated by EVSE). Position from firmware; message assignment inferred.";
CM_ BO_ 2047 "Gateway message: car config; frame length observed on a vehicle bus";
CM_ SG_ 2047 GTW_carConfigMultiplexer "Gateway: car config multiplexer";
CM_ SG_ 2047 GTW_deliveryStatus "Indicates whether the vehicle has been marked delivered to the customer in Tesla backend systems.";
CM_ SG_ 2047 GTW_cabinPTCHeaterType "Gateway: cabin PTC heater type";
CM_ SG_ 2047 GTW_rightHandDrive "Gateway: right hand drive";
CM_ SG_ 2047 GTW_rearLightType "Gateway: rear light type";
CM_ SG_ 2047 GTW_headlamps "Gateway: headlamps";
CM_ SG_ 2047 GTW_country "Gateway: country";
CM_ SG_ 2047 GTW_tireType "Gateway: tire type";
CM_ SG_ 2047 GTW_dasHw "Indicates the Driver Assistance System (DAS) hardware installed.";
CM_ SG_ 2047 GTW_brakeHWType "Gateway: brake HW type";
CM_ SG_ 2047 GTW_restraintsHardwareType "Gateway: restraints hardware type";
CM_ SG_ 2047 GTW_drivetrainType "Gateway: drivetrain type";
CM_ SG_ 2047 GTW_radarHeaterType "Gateway: radar heater type";
CM_ SG_ 2047 GTW_exteriorTrimType "Gateway: exterior trim type";
CM_ SG_ 2047 GTW_frontSeatHeaters "Gateway: front seat heaters";
CM_ SG_ 2047 GTW_rearSeatHeaters "Gateway: rear seat heaters";
CM_ SG_ 2047 GTW_eCallAntennaHW "Gateway: e call antenna HW";
CM_ SG_ 2047 GTW_homelinkType "Gateway: homelink type";
CM_ SG_ 2047 GTW_vdcType "Gateway: vdc type";
CM_ SG_ 2047 GTW_memoryMirrors "Gateway: memory mirrors";
CM_ SG_ 2047 GTW_powerLiftgateType "Gateway: power liftgate type";
CM_ SG_ 2047 GTW_lumbarECUType "Gateway: lumbar ECU type";
CM_ SG_ 2047 GTW_rearSeatHeaterType "Gateway: rear seat heater type";
CM_ SG_ 2047 GTW_auxParkLamps "Gateway: aux park lamps";
CM_ SG_ 2047 GTW_interiorCabinRadarType "Gateway: interior cabin radar type";
CM_ SG_ 2047 GTW_hvacPanelVaneType "Gateway: hvac panel vane type";
CM_ SG_ 2047 GTW_intakeAirFilterType "Gateway: intake air filter type";
CM_ SG_ 2047 GTW_eBuckConfig "Gateway: e buck config";
CM_ SG_ 2047 GTW_steeringHeaterEnabled "Gateway: steering heater enabled";
CM_ SG_ 2047 GTW_activeHighBeam "Gateway: active high beam";
CM_ SG_ 2047 GTW_airbagCutoffSwitch "Gateway: airbag cutoff switch";
CM_ SG_ 2047 GTW_intrusionSensorType "Gateway: intrusion sensor type";
CM_ SG_ 2047 GTW_spoilerType "Gateway: spoiler type";
CM_ SG_ 2047 GTW_backupCameraType "Gateway: backup camera type";
CM_ SG_ 2047 GTW_rearFogLamps "Gateway: rear fog lamps";
CM_ SG_ 2047 GTW_roofType "Gateway: roof type";
CM_ SG_ 2047 GTW_thirdRowSeatType "Gateway: third row seat type";
CM_ SG_ 2047 GTW_autopilot "Gateway: autopilot";
CM_ SG_ 2047 GTW_superchargingAccess "Gateway: supercharging access";
CM_ SG_ 2047 GTW_exteriorColor "Gateway: exterior color";
CM_ SG_ 2047 GTW_pedestrianWarningSound "Gateway: pedestrian warning sound";
CM_ SG_ 2047 GTW_steeringColumnUJointType "Gateway: steering column u joint type";
CM_ SG_ 2047 GTW_bPillarNFCParam "Gateway: b pillar NFC param";
CM_ SG_ 2047 GTW_interiorLighting "Gateway: interior lighting";
CM_ SG_ 2047 GTW_headlightLevelerType "Gateway: headlight leveler type";
CM_ SG_ 2047 GTW_numberHVILNodes "Gateway: number HVIL nodes";
CM_ SG_ 2047 GTW_mapRegion "Gateway: map region";
CM_ SG_ 2047 GTW_performancePackage "Gateway: performance package";
CM_ SG_ 2047 GTW_chassisType "Indicates the chassis type, which determines physical aspects such as suspension geometry, track width, wheel base, baseline tire size, and trailer capability.";
CM_ SG_ 2047 GTW_airSuspension "Gateway: air suspension";
CM_ SG_ 2047 GTW_centerConsoleControllerType "Gateway: center console controller type";
CM_ SG_ 2047 GTW_autopilotCameraType "Gateway: autopilot camera type";
CM_ SG_ 2047 GTW_connectivityPackage "Gateway: connectivity package";
CM_ SG_ 2047 GTW_plcSupportType "Gateway: plc support type";
CM_ SG_ 2047 GTW_badgingVersion "Gateway: badging version";
CM_ SG_ 2047 GTW_packEnergy "Gateway: pack energy";
CM_ SG_ 2047 GTW_frontSeatReclinerHardware "Gateway: front seat recliner hardware";
CM_ SG_ 2047 GTW_brakeLineSwitchType "Gateway: brake line switch type";
CM_ SG_ 2047 GTW_espValveType "Gateway: esp valve type";
CM_ SG_ 2047 GTW_softRange "Gateway: soft range";
CM_ SG_ 2047 GTW_refrigerantType "Gateway: refrigerant type";
CM_ SG_ 2047 GTW_wheelType "Gateway: wheel type";
CM_ SG_ 2047 GTW_ptcControlMode "Gateway: ptc control mode";
CM_ SG_ 2047 GTW_brakeActuationType "Gateway: brake actuation type";
CM_ SG_ 2047 GTW_secondRowSeatType "Gateway: second row seat type";
CM_ SG_ 2047 GTW_secondRowSeatMotorType "Gateway: second row seat motor type";
CM_ SG_ 2047 GTW_birthday "Gateway: birthday";
CM_ SG_ 2047 GTW_eCallEnabled "Gateway: e call enabled";
CM_ SG_ 2047 GTW_parkAssistECUType "Gateway: park assist ECU type";
CM_ SG_ 2047 GTW_passengerAirbagType "Gateway: passenger airbag type";
CM_ SG_ 2047 GTW_forwardRadarHw "Gateway: forward radar hw";
CM_ SG_ 2047 GTW_frontSeatType "Gateway: front seat type";
CM_ SG_ 2047 GTW_secondRowDisplayType "Gateway: second row display type";
CM_ SG_ 2047 GTW_wirelessPhoneChargerType "Gateway: wireless phone charger type";
CM_ SG_ 2047 GTW_ethernetTunerType "Gateway: ethernet tuner type";
CM_ SG_ 2047 GTW_interiorTrimType "Gateway: interior trim type";
CM_ SG_ 2047 GTW_gloveboxUSBType "Gateway: glovebox USB type";
CM_ SG_ 2047 GTW_coolantPumpType "Gateway: coolant pump type";
CM_ SG_ 2047 GTW_epblHwType "Gateway: epbl hw type";
CM_ SG_ 2047 GTW_epbrHwType "Gateway: epbr hw type";
CM_ SG_ 2047 GTW_blowerMotorType "Gateway: blower motor type";
CM_ SG_ 2047 GTW_rearLeftBLEEndpointParameter "Gateway: rear left BLE endpoint parameter type";
CM_ SG_ 2047 GTW_powerMirrorFoldType "Gateway: power mirror fold type";
CM_ SG_ 2047 GTW_frontUsbHubType "Gateway: front usb hub type";
CM_ SG_ 2047 GTW_superManifoldType "Type of HVAC super manifold installed";
CM_ SG_ 2047 GTW_rcmLocation "Gateway: rcm location";
CM_ SG_ 2047 GTW_autopilotExteriorCameraType "Gateway: autopilot exterior camera type";
CM_ SG_ 2047 GTW_interiorCamBeautyCoverType "Gateway: interior cam beauty cover type";
CM_ SG_ 2047 GTW_sirenType "Gateway: siren type";
CM_ SG_ 2047 GTW_hornType "Gateway: horn type";
CM_ SG_ 2047 GTW_passengerTrackMotorType "Gateway: passenger track motor type";
CM_ SG_ 2047 GTW_steeringColumnMotorType "Gateway: steering column motor type";
CM_ SG_ 2047 GTW_refrigACLineType "Gateway: refrig AC line type";
CM_ SG_ 2047 GTW_refrigFilterType "Gateway: refrig filter type";
CM_ SG_ 2047 GTW_diBurnInType "Gateway: di burn in type";
CM_ SG_ 2047 GTW_specialBadgingType "Gateway: special badging type";
CM_ SG_ 2047 GTW_chassisSubType "Reports chassis sub-variant type.";
CM_ SG_ 2047 GTW_towPackage "Gateway: tow package";
CM_ SG_ 2047 GTW_refrigLccType "Gateway: refrig lcc type";
CM_ SG_ 2047 GTW_restraintControlsType "Gateway: restraint controls type";
CM_ SG_ 2047 GTW_caliperColorType "Gateway: caliper color type";
CM_ SG_ 2047 GTW_wiperMotorType "Gateway: wiper motor type";
CM_ SG_ 2047 GTW_frontOverheadConsoleType "Gateway: front overhead console type";
CM_ SG_ 2047 GTW_shifterType "Gateway: shifter type";
CM_ SG_ 2047 GTW_compressorType "Gateway: compressor type";
CM_ SG_ 2047 GTW_twelveVBatteryType "Gateway: twelve v battery type";
CM_ SG_ 2047 GTW_efuseSWConfig "Gateway: efuse SW config";
CM_ SG_ 2047 GTW_tollCollectionModuleType "Gateway: toll collection module type";
CM_ SG_ 2047 GTW_bleEndpointUpdateMethod "Gateway: ble endpoint update method";
CM_ SG_ 2047 GTW_steeringWheelControllerType "Gateway: steering wheel controller type";
CM_ SG_ 2047 GTW_frontSeatVentilationEnabled "Gateway: front seat ventilation enabled";
CM_ SG_ 2047 GTW_gloveboxActuatorType "Gateway: glovebox actuator type";
CM_ SG_ 2047 GTW_epasType "Gateway: epas type";
CM_ SG_ 2047 GTW_homologationRegionOverride "Gateway: homologation region override";
CM_ SG_ 2047 GTW_windowCommandsPermissionType "Gateway: window commands permission type";
CM_ SG_ 2047 GTW_headlightStepperStallDetectM "Gateway: headlight stepper stall detect mode";
CM_ SG_ 2047 GTW_rgbInteriorLightingEnabled "Gateway: rgb interior lighting enabled";
CM_ SG_ 2047 GTW_windshieldWiperHeaterType "Gateway: windshield wiper heater type";
CM_ SG_ 2047 GTW_thirdRowSeatReclinerType "Gateway: third row seat recliner type";
CM_ SG_ 2047 GTW_driveInterfaceType "Gateway: drive interface type";
CM_ SG_ 2047 GTW_efficiencyPackage "Gateway: efficiency package";
CM_ SG_ 2047 GTW_visorLightType "Gateway: visor light type";
CM_ SG_ 2047 GTW_gnssAntennaType "Gateway: gnss antenna type";
CM_ SG_ 2047 GTW_airDistributionBoxType "Gateway: air distribution box type";
CM_ SG_ 2047 GTW_frontSeatHeatersEnabled "Gateway: front seat heaters enabled";
CM_ SG_ 2047 GTW_windshieldWiperHeaterEnabled "Gateway: windshield wiper heater enabled";
CM_ SG_ 2047 GTW_alcoholInterlockType "Gateway: alcohol interlock type";
CM_ SG_ 2047 GTW_fasciaType "Gateway: fascia type";
CM_ SG_ 2047 GTW_powerSteeringColumn "Gateway: power steering column";
CM_ SG_ 2047 GTW_frontSeatHeaterType "Gateway: front seat heater type";
CM_ SG_ 2047 GTW_softPerformanceLimit "Gateway: soft performance limit";
CM_ SG_ 2047 GTW_gsrFeatureType "Gateway: gsr feature type";
CM_ SG_ 2047 GTW_immersiveAudio "Gateway: immersive audio";
CM_ SG_ 2047 GTW_frontSeatVentilationType "Gateway: front seat ventilation type";
CM_ SG_ 2047 GTW_passengerOccupancySensorType "Gateway: passenger occupancy sensor type";
CM_ SG_ 2047 GTW_packPerformanceDeviation "Measures deviation from standard pack mass or power output capability associated with the vehicle packEnergy configuration.";
CM_ SG_ 2047 GTW_pressurePadType "Gateway: pressure pad type";
CM_ SG_ 2047 GTW_frontFogLamps "Gateway: front fog lamps";
CM_ SG_ 2047 GTW_driverOccupancySensorType "Gateway: driver occupancy sensor type";
CM_ SG_ 2047 GTW_audioType "Gateway: audio type";
CM_ SG_ 2047 GTW_thighExtenderType "Gateway: thigh extender type";
CM_ SG_ 2047 GTW_occupancyClassificationFeatu "Gateway: occupancy classification feature type";
CM_ SG_ 2047 GTW_frontControllerArchitectureT "Reports internal microcontroller architecture of the Front Controller assembly, which contains the Front Vehicle Controller (VCFRONT) and may contain a Vehicle Battery Controller (VCBATT).";
CM_ SG_ 2047 GTW_domeLightType "Gateway: dome light type";
CM_ SG_ 2047 GTW_tpmsType "Gateway: tpms type";
CM_ SG_ 2047 GTW_authenticationEndpointLayout "Gateway: authentication endpoint layout";
CM_ SG_ 2047 GTW_socSleepOverride "Gateway: soc sleep override";
CM_ SG_ 2047 GTW_r79BehaviorOverride "Gateway: r79 behavior override";
CM_ SG_ 2047 GTW_steeringHeaterType "Gateway: steering heater type";
CM_ SG_ 2047 GTW_narrowWipingSupported "Gateway: narrow wiping supported";
CM_ SG_ 2047 GTW_frontSeatHeaterGridType "Gateway: front seat heater grid type";
CM_ SG_ 2047 GTW_frontSeatSideSwitchType "Gateway: front seat side switch type";
CM_ SG_ 2047 GTW_sohRegulatoryStatus "Gateway: soh regulatory status";
CM_ SG_ 2047 GTW_passengerTiltMotorType "Gateway: passenger tilt motor type";
CM_ SG_ 2047 GTW_frunkInteriorReleaseType "Gateway: frunk interior release type";
CM_ SG_ 2047 GTW_m3yBusArchitecture "Reports notable features of vehicle communication bus architecture. Used for firmware artifact selection during update installation process.";
CM_ SG_ 2047 GTW_passengerLiftMotorType "Gateway: passenger lift motor type";
CM_ SG_ 2047 GTW_interiorUpperTrimType "Gateway: interior upper trim type";
CM_ SG_ 2047 GTW_blindSpotIndicatorLightType "Gateway: blind spot indicator light type";
CM_ SG_ 2047 GTW_wiperMotorAsicType "Gateway: wiper motor asic type";
CM_ SG_ 2047 GTW_hvacCaseDoorType "Gateway: hvac case door type";
CM_ SG_ 2047 GTW_occupancyDetectionSourceRequ "Gateway: occupancy detection source request";
CM_ SG_ 2047 GTW_rduCableType "Indicates type of rear drive unit cable installed on vehicle.";
CM_ SG_ 2047 GTW_parkTelltaleBehaviorType "Gateway: park telltale behavior type";
CM_ SG_ 2047 GTW_numberKeyCardsPairedInFactor "Gateway: number key cards paired in factory";
CM_ SG_ 2047 GTW_secondRowSeatVentilationType "Gateway: second row seat ventilation type";
CM_ SG_ 2047 GTW_thirdRowSeatHeaterType "Gateway: third row seat heater type";
CM_ SG_ 2047 GTW_interiorCameraType "Gateway: interior camera type";
CM_ SG_ 2047 GTW_frontFasciaCameraType "Reports type of forward facing fascia camera installed.";
CM_ SG_ 2047 GTW_interiorCamFanType "Gateway: interior cam fan type";
CM_ SG_ 2047 GTW_puddleLampType "Gateway: puddle lamp type";
CM_ SG_ 2047 GTW_solarLensType "Gateway: solar lens type";
CM_ SG_ 2047 GTW_liftgateGeometryType "Gateway: liftgate geometry type";
CM_ SG_ 2047 GTW_repeaterAeroRibType "Gateway: repeater aero rib type";
CM_ SG_ 2047 GTW_highTipForceWiperArmsType "Gateway: high tip force wiper arms type";
CM_ SG_ 2047 GTW_rcmUndersideAbuseZThreshold "Gateway: rcm underside abuse z threshold";
CM_ SG_ 2047 GTW_rcmUndersideAbuseYThreshold "Gateway: rcm underside abuse y threshold";
CM_ SG_ 2047 GTW_rcmUndersideAbuseWindow "Gateway: rcm underside abuse window";
CM_ SG_ 2047 GTW_uhfChargePortEnabled "Gateway: uhf charge port enabled";
CM_ SG_ 2047 GTW_automaticFeatureResetPackage "Gateway: automatic feature reset package";
CM_ SG_ 2047 GTW_autopilotFeaturePackage "Gateway: autopilot feature package";
CM_ SG_ 2047 GTW_doorLatchType "Gateway: door latch type";
CM_ SG_ 2047 GTW_headlinerMaterialType "Gateway: headliner material type";
CM_ SG_ 2047 GTW_glareShieldHeaterType "Gateway: glare shield heater type";
CM_ SG_ 2047 GTW_rearLightHardwareVariant "Gateway: rear light hardware variant";
CM_ SG_ 2047 GTW_fasciaHarnessCleanPointType "Gateway: fascia harness clean point type";
CM_ SG_ 2047 GTW_epasSubType "Gateway: epas sub type";
CM_ SG_ 2047 GTW_wiperSupplyChainOrigin "Gateway: wiper supply chain origin; raw 0 = signal not available (SNA)";
CM_ SG_ 2047 GTW_windowPinchParameterType "Gateway: window pinch parameter type";
CM_ SG_ 2047 GTW_badgingMaterialType "Gateway: badging material type";
CM_ SG_ 2047 GTW_mRecordVersion "Gateway: m record version";
CM_ SG_ 2047 GTW_tcuType "Gateway: tcu type";
CM_ SG_ 2047 GTW_carbComplianceBehaviorType "Gateway: carb compliance behavior type";
CM_ SG_ 2047 GTW_indirectTPMSCalibrationType "Indirect TPMS calibration type.";
CM_ SG_ 2047 GTW_v2xEnabled "Gateway: v2x enabled";
CM_ SG_ 2047 GTW_liftgateStrutType "Gateway: liftgate strut type";
CM_ SG_ 2047 GTW_exteriorMicrophoneType "Gateway: exterior microphone type";
CM_ SG_ 2047 GTW_contactorPowerSource "Gateway: contactor power source";
CM_ SG_ 2047 GTW_roofGlassType "Gateway: roof glass type";
CM_ SG_ 2047 GTW_pedalMapNameOverride "Gateway: pedal map name override";
CM_ BO_ 1638 "Gateway message: diag session; frame length observed on a vehicle bus";
CM_ SG_ 1638 GTW_diagRemainingSeconds "Seconds remaining for the diagnostics session";
CM_ SG_ 1638 GTW_diagSessionActive "UDS Session Active";
CM_ SG_ 1638 GTW_diagLevel "Current diagnostics level";
CM_ SG_ 1638 GTW_diagUnlockProcedureActive "GTW diag unlock procedure active";
CM_ SG_ 1638 GTW_diagOverrideActive "GTW diag level override active";
CM_ SG_ 1638 GTW_diagPhysicalLinkEstablished "Physical diag cable connected to the switch and link established";
CM_ BO_ 840 "Gateway message: status; frame length observed on a vehicle bus";
CM_ SG_ 840 GTW_vehicleVersionMatchStatus "Signal to indicate if the vehicle ECUs are all on a matched production version";
CM_ SG_ 840 GTW_hwtype "Describes the chip GTW is running on; raw 0 = signal not available (SNA)";
CM_ SG_ 840 GTW_jcanProductName "Describes the JCAN reference (product) name; raw 0 = signal not available (SNA)";
CM_ SG_ 840 GTW_uptimeSeconds "GTW uptime in seconds";
CM_ SG_ 840 GTW_boardRevision "Board revision ID of the MCU PCBA";
CM_ SG_ 840 GTW_touchcoreOsType "Gateway: touchcore os type";
CM_ SG_ 840 GTW_sentryModeState "Sentry Mode state; raw 6 = signal not available (SNA)";
CM_ SG_ 840 GTW_secureBootEnabled "Gateway: secure boot enabled";
CM_ SG_ 840 GTW_socSleepType "Describes the sleep type GTW is expecting from the SoC; raw 0 = signal not available (SNA)";
CM_ SG_ 840 GTW_resetType "Describes the type of reset GTW experienced; raw 0 = signal not available (SNA)";
CM_ BO_ 1005 "Gateway message: update status; frame length observed on a vehicle bus";
CM_ SG_ 1005 GTW_i2cUpdateActive "Gateway: i2c update active";
CM_ SG_ 1005 GTW_peripheralConfirmedUpdateNee "Detects if peripheral has confirmed update is needed";
CM_ SG_ 1005 GTW_ocuFailed "Reports the offboard charger update was unsuccessful.";
CM_ SG_ 1005 GTW_ecuUpdateStarted "Reports whether Electronic Control Unit (ECU) update phase is active.";
CM_ SG_ 1005 GTW_updateStarted "Main update in progress bit";
CM_ BO_ 1112 "Gateway message: veh nm; frame length observed on a vehicle bus";
CM_ SG_ 1112 GTW_nmGoingToSleep "Network management - Going to sleep state";
CM_ SG_ 1112 GTW_nmWakeUpBus "Gateway: nm wake up bus";
CM_ SG_ 1112 GTW_chBusAsleep "Chassis bus sleep state";
CM_ SG_ 1112 GTW_ethBusAsleep "ETH bus sleep state";
CM_ SG_ 1112 GTW_nmKeepAwakeReason "Network management - Keep awake reason; raw 0 = signal not available (SNA)";
CM_ SG_ 1112 GTW_nmWakeUpReason "Network management - Wakeup reason";
CM_ SG_ 1112 GTW_ethKeepAwakeReason "Reason GTW is keeping ETH bus awake; raw 0 = signal not available (SNA)";
CM_ SG_ 1112 GTW_nmDebugWakeUp "Gateway: nm debug wake up";
CM_ SG_ 1112 GTW_OTAKeepAwake "Signals that the vehicle buses should remain awake for an ongoing OTA update";
CM_ SG_ 1112 GTW_smsPokeReceived "The modem indicated it received an SMS poke";
CM_ SG_ 1112 GTW_bdyBusAsleep "BDY bus sleep state";
CM_ BO_ 1650 "HCML ECU message: info; frame length observed on a vehicle bus";
CM_ SG_ 1650 VC_hcmlInfoIndex "HCML ECU: hcml info index";
CM_ SG_ 1650 VC_infoHCMLBuildConfigId "HCM Diagnostic Field.";
CM_ SG_ 1650 VC_leftHeadlampLMMVariant "Reports the detected left headlamp LED Matrix Manager (LMM) variant; raw 0 = signal not available (SNA)";
CM_ SG_ 1650 VC_infoHCMLAssemblyId "HCM Diagnostic Field.";
CM_ SG_ 1650 VC_infoHCMLPcbaId "HCM Diagnostic Field.";
CM_ SG_ 1650 VC_infoHCMLUsageId "HCM Diagnostic Field.";
CM_ BO_ 1980 "HCMR ECU message: info; frame length observed on a vehicle bus";
CM_ SG_ 1980 VC_hcmrInfoIndex "HCMR ECU: hcmr info index";
CM_ SG_ 1980 VC_infoHCMRBuildConfigId "HCM Diagnostic Field.";
CM_ SG_ 1980 VC_rightHeadlampLMMVariant "Reports the detected right headlamp LED Matrix Manager (LMM) variant; raw 0 = signal not available (SNA)";
CM_ SG_ 1980 VC_infoHCMRAssemblyId "HCM Diagnostic Field.";
CM_ SG_ 1980 VC_infoHCMRPcbaId "HCM Diagnostic Field.";
CM_ SG_ 1980 VC_infoHCMRUsageId "HCM Diagnostic Field.";
CM_ BO_ 785 "Vector__XXX ECU message: 0x311; frame length observed on a vehicle bus";
CM_ SG_ 785 HVBMS_0x311_b0_10 "Battery computer field at bits 0-9; position from firmware, meaning not yet known";
CM_ SG_ 785 HVBMS_0x311_b10_1 "Battery computer field at bits 10-10; position from firmware, meaning not yet known";
CM_ SG_ 785 HVBMS_0x311_b11_1 "Battery computer field at bits 11-11; position from firmware, meaning not yet known";
CM_ SG_ 785 HVBMS_0x311_b12_1 "Battery computer field at bits 12-12; position from firmware, meaning not yet known";
CM_ SG_ 785 HVBMS_0x311_b13_1 "Battery computer field at bits 13-13; position from firmware, meaning not yet known";
CM_ BO_ 1106 "Vector__XXX ECU message: 0x452; frame length observed on a vehicle bus";
CM_ SG_ 1106 HVBMS_0x452_b0_10 "Battery computer field at bits 0-9; position from firmware, meaning not yet known";
BA_DEF_ BO_ "GenMsgCycleTime" INT 0 3600000;
BA_DEF_ BO_ "GenMsgSendType" ENUM "Cyclic","NotUsed","NotUsed","NotUsed","NotUsed","NotUsed","NotUsed","IfActive","NoMsgSendType","NotUsed";
BA_DEF_ BO_ "VFrameFormat" ENUM "StandardCAN","ExtendedCAN","reserved","J1939PG","reserved","reserved","reserved","reserved","reserved","reserved","reserved","reserved","reserved","reserved","StandardCAN_FD","ExtendedCAN_FD";
BA_DEF_ BO_ "CANFD_BRS" ENUM "0","1";
BA_DEF_ SG_ "GenSigSNA" STRING;
BA_DEF_ SG_ "SystemSignalLongSymbol" STRING;
BA_DEF_ SG_ "Confidence" ENUM "validated","plausible","layout-only","contradicted";
BA_DEF_DEF_ "GenMsgCycleTime" 0;
BA_DEF_DEF_ "GenMsgSendType" "NoMsgSendType";
BA_DEF_DEF_ "VFrameFormat" "StandardCAN";
BA_DEF_DEF_ "CANFD_BRS" "1";
BA_DEF_DEF_ "GenSigSNA" "";
BA_DEF_DEF_ "SystemSignalLongSymbol" "";
BA_DEF_DEF_ "Confidence" "layout-only";
BA_ "GenMsgCycleTime" BO_ 1000 100;
BA_ "GenMsgSendType" BO_ 1000 0;
BA_ "GenMsgCycleTime" BO_ 2024 1000;
BA_ "GenMsgSendType" BO_ 2024 0;
BA_ "GenMsgCycleTime" BO_ 552 100;
BA_ "GenMsgSendType" BO_ 552 0;
BA_ "GenMsgCycleTime" BO_ 742 1000;
BA_ "GenMsgSendType" BO_ 742 0;
BA_ "GenMsgCycleTime" BO_ 744 100;
BA_ "GenMsgSendType" BO_ 744 0;
BA_ "GenMsgCycleTime" BO_ 895 1000;
BA_ "GenMsgSendType" BO_ 895 0;
BA_ "GenMsgCycleTime" BO_ 927 1000;
BA_ "GenMsgSendType" BO_ 927 0;
BA_ "GenMsgCycleTime" BO_ 958 1000;
BA_ "GenMsgSendType" BO_ 958 0;
BA_ "GenMsgCycleTime" BO_ 990 1000;
BA_ "GenMsgSendType" BO_ 990 0;
BA_ "GenMsgCycleTime" BO_ 1117 1000;
BA_ "GenMsgSendType" BO_ 1117 0;
BA_ "GenMsgCycleTime" BO_ 1334 1000;
BA_ "GenMsgSendType" BO_ 1334 0;
BA_ "GenMsgCycleTime" BO_ 1303 1000;
BA_ "GenMsgSendType" BO_ 1303 0;
BA_ "GenMsgCycleTime" BO_ 1310 1000;
BA_ "GenMsgSendType" BO_ 1310 0;
BA_ "GenMsgCycleTime" BO_ 580 100;
BA_ "GenMsgSendType" BO_ 580 0;
BA_ "GenMsgCycleTime" BO_ 702 100;
BA_ "GenMsgSendType" BO_ 702 0;
BA_ "GenMsgCycleTime" BO_ 1345 100;
BA_ "GenMsgSendType" BO_ 1345 0;
BA_ "GenMsgCycleTime" BO_ 1300 1000;
BA_ "GenMsgSendType" BO_ 1300 0;
BA_ "GenMsgCycleTime" BO_ 532 100;
BA_ "GenMsgSendType" BO_ 532 0;
BA_ "GenMsgCycleTime" BO_ 533 1000;
BA_ "GenMsgSendType" BO_ 533 0;
BA_ "GenMsgCycleTime" BO_ 535 1000;
BA_ "GenMsgSendType" BO_ 535 0;
BA_ "GenMsgCycleTime" BO_ 2047 100;
BA_ "GenMsgSendType" BO_ 2047 0;
BA_ "GenMsgCycleTime" BO_ 1638 250;
BA_ "GenMsgSendType" BO_ 1638 0;
BA_ "GenMsgCycleTime" BO_ 840 1000;
BA_ "GenMsgSendType" BO_ 840 0;
BA_ "GenMsgCycleTime" BO_ 1005 1000;
BA_ "GenMsgSendType" BO_ 1005 0;
BA_ "GenMsgCycleTime" BO_ 1112 100;
BA_ "GenMsgSendType" BO_ 1112 0;
BA_ "GenMsgCycleTime" BO_ 1650 10000;
BA_ "GenMsgSendType" BO_ 1650 0;
BA_ "GenMsgCycleTime" BO_ 1980 10000;
BA_ "GenMsgSendType" BO_ 1980 0;
BA_ "Confidence" SG_ 1000 EPBR_matrixIndex 0;
BA_ "Confidence" SG_ 1000 EPBR_a001_WatchdogReset 0;
BA_ "Confidence" SG_ 1000 EPBR_a002_PowerLossReset 0;
BA_ "Confidence" SG_ 1000 EPBR_a003_SWAssertion 0;
BA_ "Confidence" SG_ 1000 EPBR_a005_CANTXError 0;
BA_ "Confidence" SG_ 1000 EPBR_a006_CANTX_cyclicError 0;
BA_ "Confidence" SG_ 1000 EPBR_a012_CPUReset 0;
BA_ "Confidence" SG_ 1000 EPBR_a013_AlertManagerFault 0;
BA_ "Confidence" SG_ 1000 EPBR_a015_NVMMError 0;
BA_ "Confidence" SG_ 1000 EPBR_a016_NVMMRecordError 0;
BA_ "Confidence" SG_ 1000 EPBR_a021_TaskSchedulerError 0;
BA_ "Confidence" SG_ 1000 EPBR_a022_TaskInitError 0;
BA_ "Confidence" SG_ 1000 EPBR_a029_CoreDump 0;
BA_ "Confidence" SG_ 1000 EPBR_a030_ECULogUploadRequest 0;
BA_ "Confidence" SG_ 1000 EPBR_a031_UDSActive 0;
BA_ "Confidence" SG_ 1000 EPBR_a041_HighCPULoad 0;
BA_ "Confidence" SG_ 1000 EPBR_a042_HighStackUsage 0;
BA_ "Confidence" SG_ 1000 EPBR_a043_Task1msError 0;
BA_ "Confidence" SG_ 1000 EPBR_a044_Task10msError 0;
BA_ "Confidence" SG_ 1000 EPBR_a045_Task100msError 0;
BA_ "Confidence" SG_ 1000 EPBR_a046_Task1000msError 0;
BA_ "Confidence" SG_ 1000 EPBR_a057_HVP_MIA 0;
BA_ "Confidence" SG_ 1000 EPBR_a058_inputRHighSyncDebug 0;
BA_ "Confidence" SG_ 1000 EPBR_a059_inputResistanceHigh 0;
BA_ "Confidence" SG_ 1000 EPBR_a060_engineeringBuild 0;
BA_ "Confidence" SG_ 1000 EPBR_a061_XCPConnected 0;
BA_ "Confidence" SG_ 1000 EPBR_a062_XCPWasConnected 0;
BA_ "Confidence" SG_ 1000 EPBR_a063_SwitchFault 0;
BA_ "Confidence" SG_ 1000 EPBR_a064_busSleepReqTimeout 0;
BA_ "Confidence" SG_ 1000 EPBR_a081_APP_MIA 0;
BA_ "Confidence" SG_ 1000 EPBR_a082_VCRIGHT_IPC_MIA 0;
BA_ "Confidence" SG_ 1000 EPBR_a083_VCLEFT_IPC_MIA 0;
BA_ "Confidence" SG_ 1000 EPBR_a084_TPMS_MIA 0;
BA_ "Confidence" SG_ 1000 EPBR_a085_CCCM_MIA 0;
BA_ "Confidence" SG_ 1000 EPBR_a086_VCBATT_MIA 0;
BA_ "Confidence" SG_ 1000 EPBR_a087_DIREL_MIA 0;
BA_ "Confidence" SG_ 1000 EPBR_a088_DIRER_MIA 0;
BA_ "Confidence" SG_ 1000 EPBR_a089_IBST_MIA 0;
BA_ "Confidence" SG_ 1000 EPBR_a090_APS_MIA 0;
BA_ "Confidence" SG_ 1000 EPBR_a091_CMPD_MIA 0;
BA_ "Confidence" SG_ 1000 EPBR_a092_VCSEATD_MIA 0;
BA_ "Confidence" SG_ 1000 EPBR_a093_VCSEATP_MIA 0;
BA_ "Confidence" SG_ 1000 EPBR_a094_EPAS3P_MIA 0;
BA_ "Confidence" SG_ 1000 EPBR_a095_CHG_MIA 0;
BA_ "Confidence" SG_ 1000 EPBR_a096_OCS1P_MIA 0;
BA_ "Confidence" SG_ 1000 EPBR_a097_CMP_MIA 0;
BA_ "Confidence" SG_ 1000 EPBR_a098_DIR_MIA 0;
BA_ "Confidence" SG_ 1000 EPBR_a099_PARK_MIA 0;
BA_ "Confidence" SG_ 1000 EPBR_a100_CANbus_MIA 0;
BA_ "Confidence" SG_ 1000 EPBR_a101_PM_MIA 0;
BA_ "Confidence" SG_ 1000 EPBR_a102_PTC_MIA 0;
BA_ "Confidence" SG_ 1000 EPBR_a103_CP_MIA 0;
BA_ "Confidence" SG_ 1000 EPBR_a104_DAS_MIA 0;
BA_ "Confidence" SG_ 1000 EPBR_a105_TAS_MIA 0;
BA_ "Confidence" SG_ 1000 EPBR_a106_PCS_MIA 0;
BA_ "Confidence" SG_ 1000 EPBR_a107_BMS_MIA 0;
BA_ "Confidence" SG_ 1000 EPBR_a108_DIF_MIA 0;
BA_ "Confidence" SG_ 1000 EPBR_a109_RCM_MIA 0;
BA_ "Confidence" SG_ 1000 EPBR_a110_GTW_MIA 0;
BA_ "Confidence" SG_ 1000 EPBR_a111_EPBR_MIA 0;
BA_ "Confidence" SG_ 1000 EPBR_a112_EPBL_MIA 0;
BA_ "Confidence" SG_ 1000 EPBR_a113_UI_MIA 0;
BA_ "Confidence" SG_ 1000 EPBR_a114_ESP_MIA 0;
BA_ "Confidence" SG_ 1000 EPBR_a115_VCSEC_MIA 0;
BA_ "Confidence" SG_ 1000 EPBR_a116_VCRIGHT_MIA 0;
BA_ "Confidence" SG_ 1000 EPBR_a117_VCLEFT_MIA 0;
BA_ "Confidence" SG_ 1000 EPBR_a118_VCFRONT_MIA 0;
BA_ "Confidence" SG_ 1000 EPBR_a119_SCCM_MIA 0;
BA_ "Confidence" SG_ 1000 EPBR_a120_DI_DRIVE_MIA 0;
BA_ "Confidence" SG_ 1000 EPBR_a121_nDriveFault 0;
BA_ "Confidence" SG_ 1000 EPBR_a122_Oc 0;
BA_ "Confidence" SG_ 1000 EPBR_a123_Uc 0;
BA_ "Confidence" SG_ 1000 EPBR_a124_calOutOfBounds 0;
BA_ "Confidence" SG_ 1000 EPBR_a125_IdleVMismatch 0;
BA_ "Confidence" SG_ 1000 EPBR_a126_MotorNVoltLow 0;
BA_ "Confidence" SG_ 1000 EPBR_a127_MotorNVoltHigh 0;
BA_ "Confidence" SG_ 1000 EPBR_a128_MotorPVoltHigh 0;
BA_ "Confidence" SG_ 1000 EPBR_a129_ICR_MIA 0;
BA_ "Confidence" SG_ 1000 EPBR_a130_BB_MIA 0;
BA_ "Confidence" SG_ 1000 EPBR_a131_RCU_MIA 0;
BA_ "Confidence" SG_ 1000 EPBR_a132_VCBATT1_MIA 0;
BA_ "Confidence" SG_ 1000 EPBR_a133_VCBATT2_MIA 0;
BA_ "Confidence" SG_ 1000 EPBR_a134_NvOv 0;
BA_ "Confidence" SG_ 1000 EPBR_a135_NvUv 0;
BA_ "Confidence" SG_ 1000 EPBR_a136_PvOv 0;
BA_ "Confidence" SG_ 1000 EPBR_a137_PvUv 0;
BA_ "Confidence" SG_ 1000 EPBR_a138_NvmDualFailure 0;
BA_ "Confidence" SG_ 1000 EPBR_a139_NvmRedundancyLoss 0;
BA_ "Confidence" SG_ 1000 EPBR_a140_NvmSlowWrite 0;
BA_ "Confidence" SG_ 1000 EPBR_a141_invalidState 0;
BA_ "Confidence" SG_ 1000 EPBR_a170_12vOv 0;
BA_ "Confidence" SG_ 1000 EPBR_a171_12vUv 0;
BA_ "Confidence" SG_ 1000 EPBR_a172_SPI_MIA 0;
BA_ "Confidence" SG_ 1000 EPBR_a173_hiCurrentMissing 0;
BA_ "Confidence" SG_ 1000 EPBR_a174_csmReleaseFailed 0;
BA_ "Confidence" SG_ 1000 EPBR_a175_csmReleaseRetry 0;
BA_ "Confidence" SG_ 1000 EPBR_a176_csmApplyFailed 0;
BA_ "Confidence" SG_ 1000 EPBR_a177_csmApplyRetry 0;
BA_ "Confidence" SG_ 1000 EPBR_a178_caliperStateUnknown 0;
BA_ "Confidence" SG_ 1000 EPBR_a179_epbProblem 0;
BA_ "Confidence" SG_ 1000 EPBR_a180_dynamicActive 0;
BA_ "Confidence" SG_ 1000 EPBR_a181_TooSteepGradeToPark 0;
BA_ "Confidence" SG_ 1000 EPBR_a182_OneEPBAppliedUnsecEnv 0;
BA_ "Confidence" SG_ 1000 EPBR_a183_cdpNotAvailable 0;
BA_ "Confidence" SG_ 1000 EPBR_a184_dynamicParkAbort 0;
BA_ "Confidence" SG_ 1000 EPBR_a185_summonAborted 0;
BA_ "Confidence" SG_ 1000 EPBR_a186_externalParkAbort 0;
BA_ "Confidence" SG_ 1000 EPBR_a187_cdpDynamic 0;
BA_ "Confidence" SG_ 1000 EPBR_a188_epbDynamic 0;
BA_ "Confidence" SG_ 1000 EPBR_a189_epbDynamicParkCanceled 0;
BA_ "Confidence" SG_ 1000 EPBR_a190_csmApplyDegraded 0;
BA_ "Confidence" SG_ 1000 EPBR_a191_csmReleaseDegraded 0;
BA_ "Confidence" SG_ 1000 EPBR_a195_parkForDriverIsLeaving 0;
BA_ "Confidence" SG_ 1000 EPBR_a196_freeRollModeActive 0;
BA_ "Confidence" SG_ 1000 EPBR_a197_freeRollModeAtSpeed 0;
BA_ "Confidence" SG_ 1000 EPBR_a198_holdClampComplete 0;
BA_ "Confidence" SG_ 1000 EPBR_a200_PmUnparkNotAllowed 0;
BA_ "Confidence" SG_ 1000 EPBR_a202_remoteEpbConfigIncompa 0;
BA_ "SystemSignalLongSymbol" SG_ 1000 EPBR_a202_remoteEpbConfigIncompa "EPBR_a202_remoteEpbConfigIncompatible";
BA_ "Confidence" SG_ 1000 EPBR_a203_hwBrakeTypeMismatch 0;
BA_ "Confidence" SG_ 1000 EPBR_a210_parkForDriverIsLeaving 0;
BA_ "SystemSignalLongSymbol" SG_ 1000 EPBR_a210_parkForDriverIsLeaving "EPBR_a210_parkForDriverIsLeavingDebug";
BA_ "Confidence" SG_ 1000 EPBR_a216_SPI_MIA_debugData1 0;
BA_ "Confidence" SG_ 1000 EPBR_a217_SPI_MIA_debugData2 0;
BA_ "Confidence" SG_ 1000 EPBR_a225_epbActiveDecel 0;
BA_ "Confidence" SG_ 1000 EPBR_a241_diOutputLocked 0;
BA_ "Confidence" SG_ 1000 EPBR_a242_hvOutputLocked 0;
BA_ "Confidence" SG_ 1000 EPBR_a243_bdwUnavailable 0;
BA_ "Confidence" SG_ 1000 EPBR_a244_WinchModeActive 0;
BA_ "Confidence" SG_ 1000 EPBR_a245_serviceModeActive 0;
BA_ "Confidence" SG_ 1000 EPBR_a246_idleFaultApply 0;
BA_ "Confidence" SG_ 1000 EPBR_a247_csmDynamicApplyRetry 0;
BA_ "Confidence" SG_ 1000 EPBR_a248_csmDynamicApplyFailed 0;
BA_ "Confidence" SG_ 1000 EPBR_a249_idleFaultRelease 0;
BA_ "Confidence" SG_ 1000 EPBR_a250_WinchModeCanceled 0;
BA_ "Confidence" SG_ 1000 EPBR_a251_currentVarianceHigh 0;
BA_ "Confidence" SG_ 1000 EPBR_a252_winchModePending 0;
BA_ "Confidence" SG_ 1000 EPBR_a253_esmReleaseBlocked 0;
BA_ "Confidence" SG_ 1000 EPBR_a254_showStalkParkButtonFau 0;
BA_ "SystemSignalLongSymbol" SG_ 1000 EPBR_a254_showStalkParkButtonFau "EPBR_a254_showStalkParkButtonFaultOnUi";
BA_ "Confidence" SG_ 1000 EPBR_a256_epbSystemApply 0;
BA_ "Confidence" SG_ 1000 EPBR_a261_winchModeWithoutSteeri 0;
BA_ "SystemSignalLongSymbol" SG_ 1000 EPBR_a261_winchModeWithoutSteeri "EPBR_a261_winchModeWithoutSteering";
BA_ "Confidence" SG_ 1000 EPBR_a262_cannotPrepareWinchMode 0;
BA_ "Confidence" SG_ 1000 EPBR_a263_epbRecoveryPark 0;
BA_ "Confidence" SG_ 1000 EPBR_a264_winchModeDeactivated 0;
BA_ "Confidence" SG_ 1000 EPBR_a272_vhclPwrStateMsmtch 0;
BA_ "Confidence" SG_ 1000 EPBR_a300_leftRightConfusion 0;
BA_ "Confidence" SG_ 1000 EPBR_a301_oocSpeedViolation 0;
BA_ "Confidence" SG_ 1000 EPBR_a302_csmLongRelease 0;
BA_ "Confidence" SG_ 1000 EPBR_a303_clampingOccuredEarly 0;
BA_ "Confidence" SG_ 1000 EPBR_a304_rearSeatControllerEFus 0;
BA_ "SystemSignalLongSymbol" SG_ 1000 EPBR_a304_rearSeatControllerEFus "EPBR_a304_rearSeatControllerEFuseTrip";
BA_ "Confidence" SG_ 1000 EPBR_a305_premiumAmpEFuseTrip 0;
BA_ "Confidence" SG_ 1000 EPBR_a330_parkForApIsLeaving 0;
BA_ "Confidence" SG_ 1000 EPBR_a350_ensOutOfRange 0;
BA_ "Confidence" SG_ 1000 EPBR_a352_audioCurrentSpikeData 0;
BA_ "Confidence" SG_ 1000 EPBR_a353_missingSpeedUnableToPa 0;
BA_ "SystemSignalLongSymbol" SG_ 1000 EPBR_a353_missingSpeedUnableToPa "EPBR_a353_missingSpeedUnableToPark";
BA_ "Confidence" SG_ 1000 EPBR_a354_parkedForLowBrakeFluid 0;
BA_ "SystemSignalLongSymbol" SG_ 1000 EPBR_a354_parkedForLowBrakeFluid "EPBR_a354_parkedForLowBrakeFluidMode";
BA_ "Confidence" SG_ 1000 EPBR_a355_brakeHwAndEpbHwMismatc 0;
BA_ "SystemSignalLongSymbol" SG_ 1000 EPBR_a355_brakeHwAndEpbHwMismatc "EPBR_a355_brakeHwAndEpbHwMismatch";
BA_ "Confidence" SG_ 1000 EPBR_a356_parkingForStationaryDe 0;
BA_ "SystemSignalLongSymbol" SG_ 1000 EPBR_a356_parkingForStationaryDe "EPBR_a356_parkingForStationaryDetect";
BA_ "Confidence" SG_ 1000 EPBR_a357_brakesTooHotForSlope 0;
BA_ "Confidence" SG_ 1000 EPBR_a358_brakesTooHotForSlopeWi 0;
BA_ "SystemSignalLongSymbol" SG_ 1000 EPBR_a358_brakesTooHotForSlopeWi "EPBR_a358_brakesTooHotForSlopeWithOnlyOneEpb";
BA_ "Confidence" SG_ 1000 EPBR_a359_seat2RControllerTrip 0;
BA_ "Confidence" SG_ 1000 EPBR_a360_ibstBrakeSwitchInvalid 0;
BA_ "Confidence" SG_ 1000 EPBR_a361_espBrakeSwitchInvalid 0;
BA_ "Confidence" SG_ 1000 EPBR_a362_ibstPressedEspNotPress 0;
BA_ "SystemSignalLongSymbol" SG_ 1000 EPBR_a362_ibstPressedEspNotPress "EPBR_a362_ibstPressedEspNotPressedMismatch";
BA_ "Confidence" SG_ 1000 EPBR_a363_ibstNotPressedEspPress 0;
BA_ "SystemSignalLongSymbol" SG_ 1000 EPBR_a363_ibstNotPressedEspPress "EPBR_a363_ibstNotPressedEspPressedMismatch";
BA_ "Confidence" SG_ 1000 EPBR_a364_espMasterCylCompOverTh 0;
BA_ "SystemSignalLongSymbol" SG_ 1000 EPBR_a364_espMasterCylCompOverTh "EPBR_a364_espMasterCylCompOverThreshold";
BA_ "Confidence" SG_ 1000 EPBR_a365_TooSteepToParkWithTrai 0;
BA_ "SystemSignalLongSymbol" SG_ 1000 EPBR_a365_TooSteepToParkWithTrai "EPBR_a365_TooSteepToParkWithTrailerWarning";
BA_ "Confidence" SG_ 1000 EPBR_a366_TooSteepToParkWithTrai 0;
BA_ "SystemSignalLongSymbol" SG_ 1000 EPBR_a366_TooSteepToParkWithTrai "EPBR_a366_TooSteepToParkWithTrailerUnSecEnv";
BA_ "Confidence" SG_ 1000 EPBR_a370_imposterDetected 0;
BA_ "Confidence" SG_ 2024 EPBR_infoIndex 0;
BA_ "Confidence" SG_ 2024 EPBR_infoBuildType 0;
BA_ "Confidence" SG_ 2024 EPBR_infoBuildConfigId 0;
BA_ "Confidence" SG_ 2024 EPBR_infoHardwareId 0;
BA_ "Confidence" SG_ 2024 EPBR_infoComponentId 0;
BA_ "Confidence" SG_ 2024 EPBR_infoPcbaId 0;
BA_ "Confidence" SG_ 2024 EPBR_infoAssemblyId 0;
BA_ "GenSigSNA" SG_ 2024 EPBR_infoAssemblyId "255";
BA_ "Confidence" SG_ 2024 EPBR_infoUsageId 0;
BA_ "Confidence" SG_ 2024 EPBR_infoSubUsageId 0;
BA_ "Confidence" SG_ 2024 EPBR_infoAppCrc 0;
BA_ "Confidence" SG_ 2024 EPBR_infoAppGitHash 0;
BA_ "Confidence" SG_ 2024 EPBR_infoBootGitHash 0;
BA_ "Confidence" SG_ 2024 EPBR_infoPlatformType 0;
BA_ "Confidence" SG_ 2024 EPBR_infoBootUdsProtoVersion 0;
BA_ "Confidence" SG_ 2024 EPBR_infoBootCrc 0;
BA_ "Confidence" SG_ 552 EPBR_unitStatus 0;
BA_ "Confidence" SG_ 552 EPBR_unitFaultStatus 0;
BA_ "Confidence" SG_ 552 EPBR_summonState 0;
BA_ "Confidence" SG_ 552 EPBR_disconnected 0;
BA_ "Confidence" SG_ 552 EPBR_pistonTouchingRotor 0;
BA_ "Confidence" SG_ 552 EPBR_csmFaultReason 0;
BA_ "Confidence" SG_ 552 EPBR_esmOperationTrigger 0;
BA_ "Confidence" SG_ 552 EPBR_summonFaultReason 0;
BA_ "Confidence" SG_ 552 EPBR_localServiceModeActive 0;
BA_ "Confidence" SG_ 552 EPBR_localCdpState 0;
BA_ "Confidence" SG_ 552 EPBR_chimeRequestLocal 0;
BA_ "Confidence" SG_ 552 EPBR_telltaleLocal 0;
BA_ "GenSigSNA" SG_ 552 EPBR_telltaleLocal "7";
BA_ "Confidence" SG_ 552 EPBR_driverIsLeavingLocal 0;
BA_ "Confidence" SG_ 552 EPBR_driverIsLeavingAnySpeedLoca 0;
BA_ "SystemSignalLongSymbol" SG_ 552 EPBR_driverIsLeavingAnySpeedLoca "EPBR_driverIsLeavingAnySpeedLocal";
BA_ "Confidence" SG_ 552 EPBR_internalCDPRequest 0;
BA_ "Confidence" SG_ 552 EPBR_esmSpeedClass 0;
BA_ "Confidence" SG_ 552 EPBR_learnedEpbConfig 0;
BA_ "Confidence" SG_ 552 EPBR_internalStatusCounter 0;
BA_ "Confidence" SG_ 552 EPBR_internalStatusChecksum 0;
BA_ "Confidence" SG_ 742 EPBR_frontSeatCushionFanCur 0;
BA_ "Confidence" SG_ 742 EPBR_frontSeatBackrestFanCur 0;
BA_ "Confidence" SG_ 742 EPBR_frontSeatCushionFanDuty 0;
BA_ "Confidence" SG_ 742 EPBR_frontSeatCushionFanEn 0;
BA_ "Confidence" SG_ 742 EPBR_frontSeatBackrestFanEn 0;
BA_ "Confidence" SG_ 742 EPBR_frontSeatBackrestFanDuty 0;
BA_ "Confidence" SG_ 742 EPBR_seat2RControllerCurrent 0;
BA_ "Confidence" SG_ 744 EPBR_systemStatus 0;
BA_ "Confidence" SG_ 744 EPBR_freeRollModeStatus 0;
BA_ "Confidence" SG_ 744 EPBR_driverIsLeaving 0;
BA_ "Confidence" SG_ 744 EPBR_driverIsLeavingAnySpeed 0;
BA_ "Confidence" SG_ 744 EPBR_systemCdpAvailable 0;
BA_ "Confidence" SG_ 744 EPBR_chimeRequest 0;
BA_ "Confidence" SG_ 744 EPBR_telltale 0;
BA_ "GenSigSNA" SG_ 744 EPBR_telltale "7";
BA_ "Confidence" SG_ 744 EPBR_audioCurrentSpikeDetected 0;
BA_ "Confidence" SG_ 744 EPBR_redundantBrakingEnabled 0;
BA_ "Confidence" SG_ 744 EPBR_summonEnabled 0;
BA_ "Confidence" SG_ 744 EPBR_brakeLight 0;
BA_ "Confidence" SG_ 744 EPBR_epbConfigMismatch 0;
BA_ "Confidence" SG_ 744 EPBR_brakeConfirmedPressed 0;
BA_ "Confidence" SG_ 744 EPBR_requestUserConfirmation 0;
BA_ "Confidence" SG_ 744 EPBR_uiWinchModeMiscBlocking 0;
BA_ "Confidence" SG_ 744 EPBR_winchModeActive 0;
BA_ "Confidence" SG_ 744 EPBR_updateMode 0;
BA_ "Confidence" SG_ 744 EPBR_winchModePermissive 0;
BA_ "Confidence" SG_ 744 EPBR_winchModePending 0;
BA_ "Confidence" SG_ 744 EPBR_cdpRequest 0;
BA_ "Confidence" SG_ 744 EPBR_uiParkAvailable 0;
BA_ "Confidence" SG_ 744 EPBR_brakeDiscWipeRequest 0;
BA_ "GenSigSNA" SG_ 744 EPBR_brakeDiscWipeRequest "3";
BA_ "Confidence" SG_ 744 EPBR_showUiGearShifter 0;
BA_ "Confidence" SG_ 744 EPBR_uiWinchModeLvStatus 0;
BA_ "Confidence" SG_ 744 EPBR_contactorCycleNotNeededForW 0;
BA_ "SystemSignalLongSymbol" SG_ 744 EPBR_contactorCycleNotNeededForW "EPBR_contactorCycleNotNeededForWinchEntry";
BA_ "Confidence" SG_ 744 EPBR_autonomyBehavior 0;
BA_ "Confidence" SG_ 744 EPBR_showStalkFaultedOnUi 0;
BA_ "Confidence" SG_ 744 EPBR_espPowerRequest 0;
BA_ "Confidence" SG_ 744 EPBR_okToPark 0;
BA_ "Confidence" SG_ 744 EPBR_hornRequest 0;
BA_ "Confidence" SG_ 744 EPBR_winchModeAvailable 0;
BA_ "Confidence" SG_ 744 EPBR_bothDisconnected 0;
BA_ "Confidence" SG_ 744 EPBR_blockDrive 0;
BA_ "Confidence" SG_ 744 EPBR_statusCounter 0;
BA_ "Confidence" SG_ 744 EPBR_statusChecksum 0;
BA_ "Confidence" SG_ 1575 EPBR_udsResponseData_H 1;
BA_ "Confidence" SG_ 1575 EPBR_udsResponseData_L 1;
BA_ "Confidence" SG_ 1662 EVSE_isoTpToVehData 0;
BA_ "Confidence" SG_ 1322 FC_alertID 1;
BA_ "Confidence" SG_ 1322 FC_alertType 1;
BA_ "Confidence" SG_ 1322 FC_a146_CA_flybackOnTime 1;
BA_ "Confidence" SG_ 1322 FC_a146_CA_flybackV 1;
BA_ "Confidence" SG_ 1322 FC_a146_CA_flybackTargetV 1;
BA_ "Confidence" SG_ 1117 FC_evseBillingDataSelect 1;
BA_ "Confidence" SG_ 1117 FC_evseBillingEnergy 0;
BA_ "Confidence" SG_ 1117 FC_evseMeterPower 0;
BA_ "Confidence" SG_ 1117 FC_evseMeterCurrent 0;
BA_ "Confidence" SG_ 1117 FC_evseMeterVoltage 0;
BA_ "Confidence" SG_ 1117 FC_evseMeterFwGitHash 0;
BA_ "Confidence" SG_ 1334 FC_evseBilling2DataSelect 1;
BA_ "Confidence" SG_ 1334 FC_evsePpuEnabled 0;
BA_ "Confidence" SG_ 1334 FC_evseBillingEnergyHighRes 0;
BA_ "GenSigSNA" SG_ 1334 FC_evseBillingEnergyHighRes "16777215";
BA_ "Confidence" SG_ 1303 FC_id 0;
BA_ "Confidence" SG_ 1303 FC_sessionId 0;
BA_ "Confidence" SG_ 1310 FC_infoIndex 1;
BA_ "Confidence" SG_ 1310 FC_infoBuildType 0;
BA_ "Confidence" SG_ 1310 FC_infoBuildConfigID 0;
BA_ "Confidence" SG_ 1310 FC_infoHardwareID 0;
BA_ "Confidence" SG_ 1310 FC_infoComponentID 0;
BA_ "Confidence" SG_ 1310 FC_infoPcbaID 0;
BA_ "Confidence" SG_ 1310 FC_infoAssemblyID 0;
BA_ "Confidence" SG_ 1310 FC_infoUsageID 0;
BA_ "Confidence" SG_ 1310 FC_infoSubUsageID 0;
BA_ "Confidence" SG_ 1310 FC_infoApplicationCRC 0;
BA_ "Confidence" SG_ 1310 FC_infoBootSvnRev 1;
BA_ "Confidence" SG_ 1310 FC_infoCPLDVersionMajor 1;
BA_ "Confidence" SG_ 1310 FC_infoCPLDVersionMinor 1;
BA_ "Confidence" SG_ 1310 FC_infoAppGitHashBytes 0;
BA_ "Confidence" SG_ 1310 FC_infoBootGitHashBytes 0;
BA_ "Confidence" SG_ 1310 FC_infoPlatformType 0;
BA_ "Confidence" SG_ 1310 FC_infoMajorVersion 0;
BA_ "Confidence" SG_ 1310 FC_infoBranchOrigin 0;
BA_ "Confidence" SG_ 1310 FC_infoMaturity 0;
BA_ "Confidence" SG_ 1310 FC_infoHardwareRevision 0;
BA_ "Confidence" SG_ 1310 FC_infoBootUdsProtoVersion 1;
BA_ "Confidence" SG_ 1310 FC_partNumChar01 0;
BA_ "Confidence" SG_ 1310 FC_partNumChar02 0;
BA_ "Confidence" SG_ 1310 FC_partNumChar03 0;
BA_ "Confidence" SG_ 1310 FC_partNumChar04 0;
BA_ "Confidence" SG_ 1310 FC_partNumChar05 0;
BA_ "Confidence" SG_ 1310 FC_partNumChar06 0;
BA_ "Confidence" SG_ 1310 FC_partNumChar07 0;
BA_ "Confidence" SG_ 1310 FC_partNumChar08 0;
BA_ "Confidence" SG_ 1310 FC_partNumChar09 0;
BA_ "Confidence" SG_ 1310 FC_partNumChar10 0;
BA_ "Confidence" SG_ 1310 FC_partNumChar11 0;
BA_ "Confidence" SG_ 1310 FC_partNumChar12 0;
BA_ "Confidence" SG_ 1310 FC_partNumChar13 0;
BA_ "Confidence" SG_ 1310 FC_partNumChar14 0;
BA_ "Confidence" SG_ 1310 FC_partNumChar15 0;
BA_ "Confidence" SG_ 1310 FC_partNumChar16 0;
BA_ "Confidence" SG_ 1310 FC_partNumChar17 0;
BA_ "Confidence" SG_ 1310 FC_partNumChar18 0;
BA_ "Confidence" SG_ 1310 FC_partNumChar19 0;
BA_ "Confidence" SG_ 1310 FC_partNumChar20 0;
BA_ "Confidence" SG_ 580 FC_powerLimit 0;
BA_ "GenSigSNA" SG_ 580 FC_powerLimit "8191";
BA_ "Confidence" SG_ 580 FC_currentLimit 0;
BA_ "GenSigSNA" SG_ 580 FC_currentLimit "8191";
BA_ "Confidence" SG_ 580 FC_maxVoltageLimit 0;
BA_ "GenSigSNA" SG_ 580 FC_maxVoltageLimit "8191";
BA_ "Confidence" SG_ 580 FC_minVoltageLimit 0;
BA_ "GenSigSNA" SG_ 580 FC_minVoltageLimit "8191";
BA_ "Confidence" SG_ 702 FC_powerLimit_value 0;
BA_ "GenSigSNA" SG_ 702 FC_powerLimit_value "32768";
BA_ "Confidence" SG_ 702 FC_currentLimit_value 0;
BA_ "GenSigSNA" SG_ 702 FC_currentLimit_value "32768";
BA_ "Confidence" SG_ 702 FC_minVoltageLimit_value 0;
BA_ "GenSigSNA" SG_ 702 FC_minVoltageLimit_value "32768";
BA_ "Confidence" SG_ 702 FC_powerLimit_exp 0;
BA_ "Confidence" SG_ 702 FC_currentLimit_exp 0;
BA_ "Confidence" SG_ 702 FC_minVoltageLimit_exp 0;
BA_ "Confidence" SG_ 1345 FC_maxPowerLimit 0;
BA_ "GenSigSNA" SG_ 1345 FC_maxPowerLimit "8191";
BA_ "Confidence" SG_ 1345 FC_maxCurrentLimit 0;
BA_ "GenSigSNA" SG_ 1345 FC_maxCurrentLimit "8191";
BA_ "Confidence" SG_ 1300 FC_serialDataSelect 1;
BA_ "Confidence" SG_ 1300 FC_serialChar01 0;
BA_ "Confidence" SG_ 1300 FC_serialChar02 0;
BA_ "Confidence" SG_ 1300 FC_serialChar03 0;
BA_ "Confidence" SG_ 1300 FC_serialChar04 0;
BA_ "Confidence" SG_ 1300 FC_serialChar05 0;
BA_ "Confidence" SG_ 1300 FC_serialChar06 0;
BA_ "Confidence" SG_ 1300 FC_serialChar07 0;
BA_ "Confidence" SG_ 1300 FC_serialChar08 0;
BA_ "Confidence" SG_ 1300 FC_serialChar09 0;
BA_ "Confidence" SG_ 1300 FC_serialChar10 0;
BA_ "Confidence" SG_ 1300 FC_serialChar11 0;
BA_ "Confidence" SG_ 1300 FC_serialChar12 0;
BA_ "Confidence" SG_ 1300 FC_serialChar13 0;
BA_ "Confidence" SG_ 1300 FC_serialChar14 0;
BA_ "Confidence" SG_ 1300 FC_serialChar15 0;
BA_ "Confidence" SG_ 1300 FC_serialChar16 0;
BA_ "Confidence" SG_ 1300 FC_serialChar17 0;
BA_ "Confidence" SG_ 532 FC_protocolVersion 0;
BA_ "Confidence" SG_ 532 FC_statusCode 0;
BA_ "GenSigSNA" SG_ 532 FC_statusCode "0";
BA_ "Confidence" SG_ 532 FC_deprecated1 0;
BA_ "Confidence" SG_ 532 FC_deprecated2 0;
BA_ "Confidence" SG_ 532 FC_deprecated3 0;
BA_ "Confidence" SG_ 532 FC_adapterLocked 0;
BA_ "Confidence" SG_ 532 FC_minCurrentLimit 0;
BA_ "Confidence" SG_ 532 FC_type 0;
BA_ "GenSigSNA" SG_ 532 FC_type "7";
BA_ "Confidence" SG_ 532 FC_dcCurrent 0;
BA_ "Confidence" SG_ 532 FC_postID 0;
BA_ "GenSigSNA" SG_ 532 FC_postID "3";
BA_ "Confidence" SG_ 532 FC_dcVoltage 0;
BA_ "Confidence" SG_ 532 FC_leakageTestNotSupported 0;
BA_ "Confidence" SG_ 532 FC_dischargeSupported 0;
BA_ "Confidence" SG_ 533 FC_externalIsolationResistance 0;
BA_ "GenSigSNA" SG_ 533 FC_externalIsolationResistance "255";
BA_ "Confidence" SG_ 535 FC_status3DataSelect 0;
BA_ "Confidence" SG_ 535 FC_status3DummySig 0;
BA_ "Confidence" SG_ 535 FC_class 0;
BA_ "GenSigSNA" SG_ 535 FC_class "0";
BA_ "Confidence" SG_ 535 FC_brand 0;
BA_ "GenSigSNA" SG_ 535 FC_brand "0";
BA_ "Confidence" SG_ 535 FC_coolingType 0;
BA_ "GenSigSNA" SG_ 535 FC_coolingType "0";
BA_ "Confidence" SG_ 535 FC_uiStopType 0;
BA_ "GenSigSNA" SG_ 535 FC_uiStopType "0";
BA_ "Confidence" SG_ 535 FC_emergencyShutdownSupported 0;
BA_ "Confidence" SG_ 535 FC_generation 0;
BA_ "GenSigSNA" SG_ 535 FC_generation "0";
BA_ "Confidence" SG_ 535 FC_billingEnergy 1;
BA_ "Confidence" SG_ 2047 GTW_carConfigMultiplexer 0;
BA_ "Confidence" SG_ 2047 GTW_deliveryStatus 0;
BA_ "Confidence" SG_ 2047 GTW_cabinPTCHeaterType 0;
BA_ "Confidence" SG_ 2047 GTW_rightHandDrive 0;
BA_ "Confidence" SG_ 2047 GTW_rearLightType 0;
BA_ "Confidence" SG_ 2047 GTW_headlamps 0;
BA_ "Confidence" SG_ 2047 GTW_country 0;
BA_ "Confidence" SG_ 2047 GTW_tireType 0;
BA_ "Confidence" SG_ 2047 GTW_dasHw 0;
BA_ "Confidence" SG_ 2047 GTW_brakeHWType 0;
BA_ "Confidence" SG_ 2047 GTW_restraintsHardwareType 0;
BA_ "Confidence" SG_ 2047 GTW_drivetrainType 0;
BA_ "Confidence" SG_ 2047 GTW_radarHeaterType 0;
BA_ "Confidence" SG_ 2047 GTW_exteriorTrimType 0;
BA_ "Confidence" SG_ 2047 GTW_frontSeatHeaters 0;
BA_ "Confidence" SG_ 2047 GTW_rearSeatHeaters 0;
BA_ "Confidence" SG_ 2047 GTW_eCallAntennaHW 0;
BA_ "Confidence" SG_ 2047 GTW_homelinkType 0;
BA_ "Confidence" SG_ 2047 GTW_vdcType 0;
BA_ "Confidence" SG_ 2047 GTW_memoryMirrors 0;
BA_ "Confidence" SG_ 2047 GTW_powerLiftgateType 0;
BA_ "Confidence" SG_ 2047 GTW_lumbarECUType 0;
BA_ "Confidence" SG_ 2047 GTW_rearSeatHeaterType 0;
BA_ "Confidence" SG_ 2047 GTW_auxParkLamps 0;
BA_ "Confidence" SG_ 2047 GTW_interiorCabinRadarType 0;
BA_ "Confidence" SG_ 2047 GTW_hvacPanelVaneType 0;
BA_ "Confidence" SG_ 2047 GTW_intakeAirFilterType 0;
BA_ "Confidence" SG_ 2047 GTW_eBuckConfig 0;
BA_ "Confidence" SG_ 2047 GTW_steeringHeaterEnabled 0;
BA_ "Confidence" SG_ 2047 GTW_activeHighBeam 0;
BA_ "Confidence" SG_ 2047 GTW_airbagCutoffSwitch 0;
BA_ "Confidence" SG_ 2047 GTW_intrusionSensorType 0;
BA_ "Confidence" SG_ 2047 GTW_spoilerType 0;
BA_ "Confidence" SG_ 2047 GTW_backupCameraType 0;
BA_ "Confidence" SG_ 2047 GTW_rearFogLamps 0;
BA_ "Confidence" SG_ 2047 GTW_roofType 0;
BA_ "Confidence" SG_ 2047 GTW_thirdRowSeatType 0;
BA_ "Confidence" SG_ 2047 GTW_autopilot 0;
BA_ "Confidence" SG_ 2047 GTW_superchargingAccess 0;
BA_ "Confidence" SG_ 2047 GTW_exteriorColor 0;
BA_ "Confidence" SG_ 2047 GTW_pedestrianWarningSound 0;
BA_ "Confidence" SG_ 2047 GTW_steeringColumnUJointType 0;
BA_ "Confidence" SG_ 2047 GTW_bPillarNFCParam 0;
BA_ "Confidence" SG_ 2047 GTW_interiorLighting 0;
BA_ "Confidence" SG_ 2047 GTW_headlightLevelerType 0;
BA_ "Confidence" SG_ 2047 GTW_numberHVILNodes 0;
BA_ "Confidence" SG_ 2047 GTW_mapRegion 0;
BA_ "Confidence" SG_ 2047 GTW_performancePackage 0;
BA_ "Confidence" SG_ 2047 GTW_chassisType 0;
BA_ "Confidence" SG_ 2047 GTW_airSuspension 0;
BA_ "Confidence" SG_ 2047 GTW_centerConsoleControllerType 0;
BA_ "Confidence" SG_ 2047 GTW_autopilotCameraType 0;
BA_ "Confidence" SG_ 2047 GTW_connectivityPackage 0;
BA_ "Confidence" SG_ 2047 GTW_plcSupportType 0;
BA_ "Confidence" SG_ 2047 GTW_badgingVersion 0;
BA_ "Confidence" SG_ 2047 GTW_packEnergy 0;
BA_ "Confidence" SG_ 2047 GTW_frontSeatReclinerHardware 0;
BA_ "Confidence" SG_ 2047 GTW_brakeLineSwitchType 0;
BA_ "Confidence" SG_ 2047 GTW_espValveType 0;
BA_ "Confidence" SG_ 2047 GTW_softRange 0;
BA_ "Confidence" SG_ 2047 GTW_refrigerantType 0;
BA_ "Confidence" SG_ 2047 GTW_wheelType 0;
BA_ "Confidence" SG_ 2047 GTW_ptcControlMode 0;
BA_ "Confidence" SG_ 2047 GTW_brakeActuationType 0;
BA_ "Confidence" SG_ 2047 GTW_secondRowSeatType 0;
BA_ "Confidence" SG_ 2047 GTW_secondRowSeatMotorType 0;
BA_ "Confidence" SG_ 2047 GTW_birthday 0;
BA_ "Confidence" SG_ 2047 GTW_eCallEnabled 0;
BA_ "Confidence" SG_ 2047 GTW_parkAssistECUType 0;
BA_ "Confidence" SG_ 2047 GTW_passengerAirbagType 0;
BA_ "Confidence" SG_ 2047 GTW_forwardRadarHw 0;
BA_ "Confidence" SG_ 2047 GTW_frontSeatType 0;
BA_ "Confidence" SG_ 2047 GTW_secondRowDisplayType 0;
BA_ "Confidence" SG_ 2047 GTW_wirelessPhoneChargerType 0;
BA_ "Confidence" SG_ 2047 GTW_ethernetTunerType 0;
BA_ "Confidence" SG_ 2047 GTW_interiorTrimType 0;
BA_ "Confidence" SG_ 2047 GTW_gloveboxUSBType 0;
BA_ "Confidence" SG_ 2047 GTW_coolantPumpType 0;
BA_ "Confidence" SG_ 2047 GTW_epblHwType 0;
BA_ "Confidence" SG_ 2047 GTW_epbrHwType 0;
BA_ "Confidence" SG_ 2047 GTW_blowerMotorType 0;
BA_ "Confidence" SG_ 2047 GTW_rearLeftBLEEndpointParameter 0;
BA_ "SystemSignalLongSymbol" SG_ 2047 GTW_rearLeftBLEEndpointParameter "GTW_rearLeftBLEEndpointParameterType";
BA_ "Confidence" SG_ 2047 GTW_powerMirrorFoldType 0;
BA_ "Confidence" SG_ 2047 GTW_frontUsbHubType 0;
BA_ "Confidence" SG_ 2047 GTW_superManifoldType 0;
BA_ "Confidence" SG_ 2047 GTW_rcmLocation 0;
BA_ "Confidence" SG_ 2047 GTW_autopilotExteriorCameraType 0;
BA_ "Confidence" SG_ 2047 GTW_interiorCamBeautyCoverType 0;
BA_ "Confidence" SG_ 2047 GTW_sirenType 0;
BA_ "Confidence" SG_ 2047 GTW_hornType 0;
BA_ "Confidence" SG_ 2047 GTW_passengerTrackMotorType 0;
BA_ "Confidence" SG_ 2047 GTW_steeringColumnMotorType 0;
BA_ "Confidence" SG_ 2047 GTW_refrigACLineType 0;
BA_ "Confidence" SG_ 2047 GTW_refrigFilterType 0;
BA_ "Confidence" SG_ 2047 GTW_diBurnInType 0;
BA_ "Confidence" SG_ 2047 GTW_specialBadgingType 0;
BA_ "Confidence" SG_ 2047 GTW_chassisSubType 0;
BA_ "Confidence" SG_ 2047 GTW_towPackage 0;
BA_ "Confidence" SG_ 2047 GTW_refrigLccType 0;
BA_ "Confidence" SG_ 2047 GTW_restraintControlsType 0;
BA_ "Confidence" SG_ 2047 GTW_caliperColorType 0;
BA_ "Confidence" SG_ 2047 GTW_wiperMotorType 0;
BA_ "Confidence" SG_ 2047 GTW_frontOverheadConsoleType 0;
BA_ "Confidence" SG_ 2047 GTW_shifterType 0;
BA_ "Confidence" SG_ 2047 GTW_compressorType 0;
BA_ "Confidence" SG_ 2047 GTW_twelveVBatteryType 0;
BA_ "Confidence" SG_ 2047 GTW_efuseSWConfig 0;
BA_ "Confidence" SG_ 2047 GTW_tollCollectionModuleType 0;
BA_ "Confidence" SG_ 2047 GTW_bleEndpointUpdateMethod 0;
BA_ "Confidence" SG_ 2047 GTW_steeringWheelControllerType 0;
BA_ "Confidence" SG_ 2047 GTW_frontSeatVentilationEnabled 0;
BA_ "Confidence" SG_ 2047 GTW_gloveboxActuatorType 0;
BA_ "Confidence" SG_ 2047 GTW_epasType 0;
BA_ "Confidence" SG_ 2047 GTW_homologationRegionOverride 0;
BA_ "Confidence" SG_ 2047 GTW_windowCommandsPermissionType 0;
BA_ "Confidence" SG_ 2047 GTW_headlightStepperStallDetectM 0;
BA_ "SystemSignalLongSymbol" SG_ 2047 GTW_headlightStepperStallDetectM "GTW_headlightStepperStallDetectMode";
BA_ "Confidence" SG_ 2047 GTW_rgbInteriorLightingEnabled 0;
BA_ "Confidence" SG_ 2047 GTW_windshieldWiperHeaterType 0;
BA_ "Confidence" SG_ 2047 GTW_thirdRowSeatReclinerType 0;
BA_ "Confidence" SG_ 2047 GTW_driveInterfaceType 0;
BA_ "Confidence" SG_ 2047 GTW_efficiencyPackage 0;
BA_ "Confidence" SG_ 2047 GTW_visorLightType 0;
BA_ "Confidence" SG_ 2047 GTW_gnssAntennaType 0;
BA_ "Confidence" SG_ 2047 GTW_airDistributionBoxType 0;
BA_ "Confidence" SG_ 2047 GTW_frontSeatHeatersEnabled 0;
BA_ "Confidence" SG_ 2047 GTW_windshieldWiperHeaterEnabled 0;
BA_ "Confidence" SG_ 2047 GTW_alcoholInterlockType 0;
BA_ "Confidence" SG_ 2047 GTW_fasciaType 0;
BA_ "Confidence" SG_ 2047 GTW_powerSteeringColumn 0;
BA_ "Confidence" SG_ 2047 GTW_frontSeatHeaterType 0;
BA_ "Confidence" SG_ 2047 GTW_softPerformanceLimit 0;
BA_ "Confidence" SG_ 2047 GTW_gsrFeatureType 0;
BA_ "Confidence" SG_ 2047 GTW_immersiveAudio 0;
BA_ "Confidence" SG_ 2047 GTW_frontSeatVentilationType 0;
BA_ "Confidence" SG_ 2047 GTW_passengerOccupancySensorType 0;
BA_ "Confidence" SG_ 2047 GTW_packPerformanceDeviation 0;
BA_ "Confidence" SG_ 2047 GTW_pressurePadType 1;
BA_ "Confidence" SG_ 2047 GTW_frontFogLamps 0;
BA_ "Confidence" SG_ 2047 GTW_driverOccupancySensorType 0;
BA_ "Confidence" SG_ 2047 GTW_audioType 0;
BA_ "Confidence" SG_ 2047 GTW_thighExtenderType 0;
BA_ "Confidence" SG_ 2047 GTW_occupancyClassificationFeatu 0;
BA_ "SystemSignalLongSymbol" SG_ 2047 GTW_occupancyClassificationFeatu "GTW_occupancyClassificationFeatureType";
BA_ "Confidence" SG_ 2047 GTW_frontControllerArchitectureT 0;
BA_ "SystemSignalLongSymbol" SG_ 2047 GTW_frontControllerArchitectureT "GTW_frontControllerArchitectureType";
BA_ "Confidence" SG_ 2047 GTW_domeLightType 0;
BA_ "Confidence" SG_ 2047 GTW_tpmsType 0;
BA_ "Confidence" SG_ 2047 GTW_authenticationEndpointLayout 0;
BA_ "Confidence" SG_ 2047 GTW_socSleepOverride 0;
BA_ "Confidence" SG_ 2047 GTW_r79BehaviorOverride 0;
BA_ "Confidence" SG_ 2047 GTW_steeringHeaterType 0;
BA_ "Confidence" SG_ 2047 GTW_narrowWipingSupported 0;
BA_ "Confidence" SG_ 2047 GTW_frontSeatHeaterGridType 0;
BA_ "Confidence" SG_ 2047 GTW_frontSeatSideSwitchType 0;
BA_ "Confidence" SG_ 2047 GTW_sohRegulatoryStatus 0;
BA_ "Confidence" SG_ 2047 GTW_passengerTiltMotorType 0;
BA_ "Confidence" SG_ 2047 GTW_frunkInteriorReleaseType 0;
BA_ "Confidence" SG_ 2047 GTW_m3yBusArchitecture 0;
BA_ "Confidence" SG_ 2047 GTW_passengerLiftMotorType 0;
BA_ "Confidence" SG_ 2047 GTW_interiorUpperTrimType 0;
BA_ "Confidence" SG_ 2047 GTW_blindSpotIndicatorLightType 0;
BA_ "Confidence" SG_ 2047 GTW_wiperMotorAsicType 0;
BA_ "Confidence" SG_ 2047 GTW_hvacCaseDoorType 0;
BA_ "Confidence" SG_ 2047 GTW_occupancyDetectionSourceRequ 0;
BA_ "SystemSignalLongSymbol" SG_ 2047 GTW_occupancyDetectionSourceRequ "GTW_occupancyDetectionSourceRequest";
BA_ "Confidence" SG_ 2047 GTW_rduCableType 0;
BA_ "Confidence" SG_ 2047 GTW_parkTelltaleBehaviorType 0;
BA_ "Confidence" SG_ 2047 GTW_numberKeyCardsPairedInFactor 0;
BA_ "SystemSignalLongSymbol" SG_ 2047 GTW_numberKeyCardsPairedInFactor "GTW_numberKeyCardsPairedInFactory";
BA_ "Confidence" SG_ 2047 GTW_secondRowSeatVentilationType 0;
BA_ "Confidence" SG_ 2047 GTW_thirdRowSeatHeaterType 0;
BA_ "Confidence" SG_ 2047 GTW_interiorCameraType 0;
BA_ "Confidence" SG_ 2047 GTW_frontFasciaCameraType 0;
BA_ "Confidence" SG_ 2047 GTW_interiorCamFanType 0;
BA_ "Confidence" SG_ 2047 GTW_puddleLampType 0;
BA_ "Confidence" SG_ 2047 GTW_solarLensType 0;
BA_ "Confidence" SG_ 2047 GTW_liftgateGeometryType 0;
BA_ "Confidence" SG_ 2047 GTW_repeaterAeroRibType 0;
BA_ "Confidence" SG_ 2047 GTW_highTipForceWiperArmsType 0;
BA_ "Confidence" SG_ 2047 GTW_rcmUndersideAbuseZThreshold 0;
BA_ "Confidence" SG_ 2047 GTW_rcmUndersideAbuseYThreshold 0;
BA_ "Confidence" SG_ 2047 GTW_rcmUndersideAbuseWindow 0;
BA_ "Confidence" SG_ 2047 GTW_uhfChargePortEnabled 0;
BA_ "Confidence" SG_ 2047 GTW_automaticFeatureResetPackage 0;
BA_ "Confidence" SG_ 2047 GTW_autopilotFeaturePackage 0;
BA_ "Confidence" SG_ 2047 GTW_doorLatchType 0;
BA_ "Confidence" SG_ 2047 GTW_headlinerMaterialType 0;
BA_ "Confidence" SG_ 2047 GTW_glareShieldHeaterType 0;
BA_ "Confidence" SG_ 2047 GTW_rearLightHardwareVariant 0;
BA_ "Confidence" SG_ 2047 GTW_fasciaHarnessCleanPointType 0;
BA_ "Confidence" SG_ 2047 GTW_epasSubType 0;
BA_ "Confidence" SG_ 2047 GTW_wiperSupplyChainOrigin 0;
BA_ "GenSigSNA" SG_ 2047 GTW_wiperSupplyChainOrigin "0";
BA_ "Confidence" SG_ 2047 GTW_windowPinchParameterType 0;
BA_ "Confidence" SG_ 2047 GTW_badgingMaterialType 0;
BA_ "Confidence" SG_ 2047 GTW_mRecordVersion 0;
BA_ "Confidence" SG_ 2047 GTW_tcuType 0;
BA_ "Confidence" SG_ 2047 GTW_carbComplianceBehaviorType 0;
BA_ "Confidence" SG_ 2047 GTW_indirectTPMSCalibrationType 0;
BA_ "Confidence" SG_ 2047 GTW_v2xEnabled 0;
BA_ "Confidence" SG_ 2047 GTW_liftgateStrutType 0;
BA_ "Confidence" SG_ 2047 GTW_exteriorMicrophoneType 0;
BA_ "Confidence" SG_ 2047 GTW_contactorPowerSource 0;
BA_ "Confidence" SG_ 2047 GTW_roofGlassType 0;
BA_ "Confidence" SG_ 2047 GTW_pedalMapNameOverride 0;
BA_ "Confidence" SG_ 1638 GTW_diagRemainingSeconds 1;
BA_ "Confidence" SG_ 1638 GTW_diagSessionActive 1;
BA_ "Confidence" SG_ 1638 GTW_diagLevel 1;
BA_ "Confidence" SG_ 1638 GTW_diagUnlockProcedureActive 1;
BA_ "Confidence" SG_ 1638 GTW_diagOverrideActive 1;
BA_ "Confidence" SG_ 1638 GTW_diagPhysicalLinkEstablished 1;
BA_ "Confidence" SG_ 840 GTW_vehicleVersionMatchStatus 1;
BA_ "Confidence" SG_ 840 GTW_hwtype 1;
BA_ "GenSigSNA" SG_ 840 GTW_hwtype "0";
BA_ "Confidence" SG_ 840 GTW_jcanProductName 1;
BA_ "GenSigSNA" SG_ 840 GTW_jcanProductName "0";
BA_ "Confidence" SG_ 840 GTW_uptimeSeconds 1;
BA_ "Confidence" SG_ 840 GTW_boardRevision 1;
BA_ "Confidence" SG_ 840 GTW_touchcoreOsType 1;
BA_ "Confidence" SG_ 840 GTW_sentryModeState 1;
BA_ "GenSigSNA" SG_ 840 GTW_sentryModeState "6";
BA_ "Confidence" SG_ 840 GTW_secureBootEnabled 1;
BA_ "Confidence" SG_ 840 GTW_socSleepType 1;
BA_ "GenSigSNA" SG_ 840 GTW_socSleepType "0";
BA_ "Confidence" SG_ 840 GTW_resetType 1;
BA_ "GenSigSNA" SG_ 840 GTW_resetType "0";
BA_ "Confidence" SG_ 1005 GTW_peripheralConfirmedUpdateNee 1;
BA_ "SystemSignalLongSymbol" SG_ 1005 GTW_peripheralConfirmedUpdateNee "GTW_peripheralConfirmedUpdateNeeded";
BA_ "Confidence" SG_ 1005 GTW_ocuFailed 1;
BA_ "Confidence" SG_ 1005 GTW_ecuUpdateStarted 1;
BA_ "Confidence" SG_ 1005 GTW_updateStarted 1;
BA_ "Confidence" SG_ 1112 GTW_nmGoingToSleep 1;
BA_ "Confidence" SG_ 1112 GTW_chBusAsleep 1;
BA_ "Confidence" SG_ 1112 GTW_ethBusAsleep 1;
BA_ "Confidence" SG_ 1112 GTW_nmKeepAwakeReason 1;
BA_ "GenSigSNA" SG_ 1112 GTW_nmKeepAwakeReason "0";
BA_ "Confidence" SG_ 1112 GTW_nmWakeUpReason 1;
BA_ "Confidence" SG_ 1112 GTW_ethKeepAwakeReason 1;
BA_ "GenSigSNA" SG_ 1112 GTW_ethKeepAwakeReason "0";
BA_ "Confidence" SG_ 1112 GTW_nmDebugWakeUp 1;
BA_ "Confidence" SG_ 1112 GTW_OTAKeepAwake 1;
BA_ "Confidence" SG_ 1112 GTW_smsPokeReceived 1;
BA_ "Confidence" SG_ 1112 GTW_bdyBusAsleep 1;
BA_ "Confidence" SG_ 1650 VC_hcmlInfoIndex 0;
BA_ "Confidence" SG_ 1650 VC_infoHCMLBuildConfigId 0;
BA_ "Confidence" SG_ 1650 VC_leftHeadlampLMMVariant 0;
BA_ "GenSigSNA" SG_ 1650 VC_leftHeadlampLMMVariant "0";
BA_ "Confidence" SG_ 1650 VC_infoHCMLAssemblyId 0;
BA_ "Confidence" SG_ 1650 VC_infoHCMLPcbaId 0;
BA_ "Confidence" SG_ 1650 VC_infoHCMLUsageId 0;
BA_ "Confidence" SG_ 1980 VC_hcmrInfoIndex 0;
BA_ "Confidence" SG_ 1980 VC_infoHCMRBuildConfigId 0;
BA_ "Confidence" SG_ 1980 VC_rightHeadlampLMMVariant 0;
BA_ "GenSigSNA" SG_ 1980 VC_rightHeadlampLMMVariant "0";
BA_ "Confidence" SG_ 1980 VC_infoHCMRAssemblyId 0;
BA_ "Confidence" SG_ 1980 VC_infoHCMRPcbaId 0;
BA_ "Confidence" SG_ 1980 VC_infoHCMRUsageId 0;
VAL_ 1000 EPBR_matrixIndex 6 "AlertMatrix6" 5 "AlertMatrix5" 4 "AlertMatrix4" 3 "AlertMatrix3" 2 "AlertMatrix2" 1 "AlertMatrix1" 0 "AlertMatrix0" ;
VAL_ 2024 EPBR_infoIndex 255 "END" 41 "SUBCOMPONENT14" 40 "SUBCOMPONENT13" 39 "SUBCOMPONENT12" 38 "SUBCOMPONENT11" 37 "SUBCOMPONENT10" 36 "SUBCOMPONENT9" 35 "SUBCOMPONENT8" 34 "SUBCOMPONENT7" 33 "SUBCOMPONENT6" 32 "SUBCOMPONENT5" 31 "SUBCOMPONENT4" 24 "SUBCOMPONENT3" 23 "SUBCOMPONENT2" 20 "UDS_PROTOCOL_BOOTCRC" 19 "VERSION_DEPRECATED" 18 "BOOTLOADER_GITHASH" 17 "APP_GITHASH" 16 "SUBCOMPONENT1" 15 "BOOTLOADER_CRC" 14 "BOOTLOADER_SVN" 13 "APP_CRC" 11 "PCBAID_ASSYID_USAGEID" 10 "BUILD_HWID_COMPONENTID" 9 "DEPRECATED_9" 8 "DEPRECATED_8" 7 "DEPRECATED_7" 6 "DEPRECATED_6" 5 "DEPRECATED_5" 4 "DEPRECATED_4" 3 "DEPRECATED_3" 2 "DEPRECATED_2" 1 "DEPRECATED_1" 0 "DEPRECATED_0" ;
VAL_ 2024 EPBR_infoBuildType 4 "INFO_MFG_BUILD" 3 "INFO_TRACEABLE_CI_BUILD" 2 "INFO_LOCAL_BUILD" 1 "INFO_PLATFORM_BUILD" 0 "INFO_UNKNOWN_BUILD" ;
VAL_ 2024 EPBR_infoAssemblyId 255 "ASSEMBLY_SNA" 1 "ASSEMBLY1" ;
VAL_ 552 EPBR_unitStatus 23 "EPB_STATUS_COUNT" 22 "EPB_STATUS_AUTONOMY_OPEN" 21 "EPB_STATUS_FREE_ROLL_MODE" 20 "EPB_STATUS_DYNAMIC_PARKING" 19 "EPB_STATUS_EXTERNAL_PARKING" 18 "EPB_STATUS_RELEASING_FOR_EXTERNAL_PARK" 17 "EPB_STATUS_EXTERNAL_DYNAMIC" 16 "EPB_STATUS_SUMMON_PARKING" 15 "EPB_STATUS_SUMMON_RELEASING" 14 "EPB_STATUS_SUMMON" 13 "EPB_STATUS_WINCHMODE_PENDING" 12 "EPB_STATUS_PARK_PENDING" 11 "EPB_STATUS_SERVICE_RELEASING" 10 "EPB_STATUS_RELEASING" 9 "EPB_STATUS_DYNAMIC_APPLYING" 8 "EPB_STATUS_PARKING" 7 "EPB_STATUS_WINCHMODE_RELEASING" 6 "EPB_STATUS_WINCHMODE" 5 "EPB_STATUS_SERVICE" 4 "EPB_STATUS_START" 3 "EPB_STATUS_PARK" 2 "EPB_STATUS_DYNAMIC" 1 "EPB_STATUS_OPEN" 0 "EPB_STATUS_UNKNOWN" ;
VAL_ 552 EPBR_unitFaultStatus 3 "EPB_STATUS_FAULT_IDLE" 2 "EPB_STATUS_FAULT" 1 "EPB_STATUS_RETRY" 0 "EPB_STATUS_NOMINAL" ;
VAL_ 552 EPBR_summonState 6 "EPB_SUMMON_UNAVAILABLE" 5 "EPB_SUMMON_FAULT" 4 "EPB_SUMMON_COMPLETE" 3 "EPB_SUMMON_ACTIVE" 2 "EPB_SUMMON_ARMED" 1 "EPB_SUMMON_IDLE" 0 "EPB_SUMMON_INIT" ;
VAL_ 552 EPBR_csmFaultReason 23 "CSM_FAULT_REMOTE_MIA" 22 "CSM_FAULT_NVM_MISMATCH" 21 "CSM_FAULT_EPBM_MIA" 20 "CSM_FAULT_MOTOR_NOT_READY" 19 "CSM_FAULT_MOTOR_ACTIVE_FAULT" 18 "CSM_FAULT_MOTOR_IDLE_FAULT" 17 "CSM_FAULT_TIMEOUT_EPBM_START" 16 "CSM_FAULT_TIMEOUT_NO_RAMP" 15 "CSM_FAULT_TIMEOUT_EPBM_CUTOFF" 14 "CSM_FAULT_TIMEOUT_RELEASE_COMPLETE" 13 "CSM_FAULT_TIMEOUT_RELEASE_NO_LOAD" 12 "CSM_FAULT_TIMEOUT_RELEASE_WAIT_FOR_ENDSTOP" 11 "CSM_FAULT_TIMEOUT_RELEASE_INRUSH" 10 "CSM_FAULT_TIMEOUT_EPBM_WAIT_FOR_CLAMP" 9 "CSM_FAULT_TIMEOUT_EPB_WAIT_FOR_CLAMP" 8 "CSM_FAULT_TIMEOUT_APPLY_INRUSH" 7 "CSM_FAULT_TIMEOUT_APPLY_COMPLETE" 6 "CSM_FAULT_RELEASE_BLOCKED" 5 "CSM_FAULT_APPLY_BLOCKED" 4 "CSM_FAULT_TIMEOUT_CALIBRATE" 3 "CSM_FAULT_STATE_MISMATCH" 2 "CSM_FAULT_EPBM_FAULTED" 1 "CSM_FAULT_EPBM_DISABLED" 0 "CSM_FAULT_NONE" ;
VAL_ 552 EPBR_esmOperationTrigger 50 "EPB_TRIGGER_ACTIVE_DECEL_DAS_STATIC" 49 "EPB_TRIGGER_ACTIVE_DECEL_CDP_DOWN" 48 "EPB_TRIGGER_AP_IS_LEAVING" 47 "EPB_TRIGGER_RECOVERY_PARK" 46 "EPB_TRIGGER_SPEED_SOURCES_LOST" 45 "EPB_TRIGGER_ACTIVE_DECEL_OKTOPARK" 44 "EPB_TRIGGER_ACTIVE_DECEL_FAST" 43 "EPB_TRIGGER_STEERING_ACTIVE_DECEL" 42 "EPB_TRIGGER_LV_ACTIVE_DECEL" 41 "EPB_TRIGGER_CDP_PANIC_MODE_READY" 40 "EPB_TRIGGER_CDP_PANIC_MODE_TIMEOUT" 39 "EPB_TRIGGER_DI_PARK" 38 "EPB_TRIGGER_FREE_ROLL_PARK_FOR_HANDLE_PULLED" 37 "EPB_TRIGGER_LOW_BRAKE_FLUID_MODE_DYNAMIC" 36 "EPB_TRIGGER_LOW_BRAKE_FLUID_MODE_DYNAMIC_PARK" 35 "EPB_TRIGGER_LOW_BRAKE_FLUID_MODE_PARK" 34 "EPB_TRIGGER_STATIONARY_DETECT" 33 "EPB_TRIGGER_TOUCHSCREEN_INVALID" 32 "EPB_TRIGGER_UI_DOOR_OPEN_REQUEST" 31 "EPB_TRIGGER_AUTOPARK_END" 30 "EPB_TRIGGER_DRIVER_IS_LEAVING" 29 "EPB_TRIGGER_SYSTEM_APPLY" 28 "EPB_TRIGGER_ACCELERATION" 27 "EPB_TRIGGER_EPBM_DISQUALIFIED" 26 "EPB_TRIGGER_DISQUALIFIED" 25 "EPB_TRIGGER_SUMMON_FAULT" 24 "EPB_TRIGGER_FAULT" 23 "EPB_TRIGGER_SUMMON_COMPLETE" 22 "EPB_TRIGGER_REAPPLY" 21 "EPB_TRIGGER_SAVESTATE_ON_BOOT" 20 "EPB_TRIGGER_TIMEOUT" 19 "EPB_TRIGGER_SPEED_FAST" 18 "EPB_TRIGGER_SPEED_OKAYTOPARK" 17 "EPB_TRIGGER_SPEED_STOPPED" 16 "EPB_TRIGGER_USER_CANCEL" 15 "EPB_TRIGGER_USER_CONFIRMED" 14 "EPB_TRIGGER_DIAG_EXIT" 13 "EPB_TRIGGER_DIAG_OPEN" 12 "EPB_TRIGGER_DIAG_CLOSE" 11 "EPB_TRIGGER_SERVICE" 10 "EPB_TRIGGER_WINCHMODE_UNAVAILABLE" 9 "EPB_TRIGGER_WINCHMODE_ENTER" 8 "EPB_TRIGGER_WINCHMODE_EXIT" 7 "EPB_TRIGGER_TOUCHSCREEN" 6 "EPB_TRIGGER_DI_UNPARK" 5 "EPB_TRIGGER_ACTIVE_PARK_REQUEST" 4 "EPB_TRIGGER_PBUTTON_RELEASED" 3 "EPB_TRIGGER_PBUTTON_PRESSED_UNKNOWN" 2 "EPB_TRIGGER_PBUTTON_PRESSED_FAST" 1 "EPB_TRIGGER_PBUTTON_PRESSED_OKTOPARK" 0 "EPB_TRIGGER_PBUTTON_PRESSED_STOPPED" ;
VAL_ 552 EPBR_summonFaultReason 30 "EPB_SUMMONFAULT_MONITOR_TYPE_UNKNOWN" 29 "EPB_SUMMONFAULT_AP_MONITOR" 28 "EPB_SUMMONFAULT_REMOTE_DID_NOT_START" 27 "EPB_SUMMONFAULT_INVALID_REMOTE_STATE" 26 "EPB_SUMMONFAULT_START_IN_UNAVAILABLE" 25 "EPB_SUMMONFAULT_REMOTE_UNIT_FAULTED" 24 "EPB_SUMMONFAULT_LOCAL_UNIT_FAULTED" 23 "EPB_SUMMONFAULT_REMOTE_SUMMON_FAULTED" 22 "EPB_SUMMONFAULT_EPBREMOTE_MIA" 21 "EPB_SUMMONFAULT_PASSIVE_REQUEST" 20 "EPB_SUMMONFAULT_DI_STATE_INVALID" 19 "EPB_SUMMONFAULT_EPB_FAULT" 18 "EPB_SUMMONFAULT_MISMATCH" 17 "EPB_SUMMONFAULT_OOC" 16 "EPB_SUMMONFAULT_PM_REQUEST" 15 "EPB_SUMMONFAULT_PM_MIA" 14 "EPB_SUMMONFAULT_PARK_MIA" 13 "EPB_SUMMONFAULT_EXTERNAL" 12 "EPB_SUMMONFAULT_SPEED" 11 "EPB_SUMMONFAULT_EPBM_REQUEST" 10 "EPB_SUMMONFAULT_EAC_NOT_ALLOWED" 9 "EPB_SUMMONFAULT_VEH_CAN_FAULT" 8 "EPB_SUMMONFAULT_ESP_FAULT" 7 "EPB_SUMMONFAULT_DAS_FAULT" 6 "EPB_SUMMONFAULT_DI_APC_FAULT" 5 "EPB_SUMMONFAULT_DI_FAULT" 4 "EPB_SUMMONFAULT_EPBM_MIA" 3 "EPB_SUMMONFAULT_ESP_MIA" 2 "EPB_SUMMONFAULT_DAS_MIA" 1 "EPB_SUMMONFAULT_DI_MIA" 0 "EPB_SUMMONFAULT_NONE" ;
VAL_ 552 EPBR_localCdpState 2 "EPB_CDP_STATE_FAULT" 1 "EPB_CDP_STATE_VALID" 0 "EPB_CDP_STATE_UNKNOWN" ;
VAL_ 552 EPBR_chimeRequestLocal 4 "EPB_CHIME_REQUEST_ACTIVE_DECEL" 3 "EPB_CHIME_REQUEST_ABOUT_TO_ACTIVE_DECEL" 2 "EPB_CHIME_REQUEST_GPO" 1 "EPB_CHIME_REQUEST_GENERAL" 0 "EPB_CHIME_REQUEST_NONE" ;
VAL_ 552 EPBR_telltaleLocal 7 "EPB_TELLTALE_SNA" 4 "EPB_TELLTALE_LAMP_RED_FLASH" 3 "EPB_TELLTALE_LAMP_AMBER_ON" 2 "EPB_TELLTALE_LAMP_RED_ON" 1 "EPB_TELLTALE_LAMP_RED_PARKED" 0 "EPB_TELLTALE_LAMP_OFF" ;
VAL_ 552 EPBR_internalCDPRequest 1 "EPB_CDP_REQUESTED" 0 "EPB_CDP_NOT_REQUESTED" ;
VAL_ 552 EPBR_esmSpeedClass 4 "ESM_SPEED_CLASS_UNKNOWN" 3 "ESM_SPEED_CLASS_FAST" 2 "ESM_SPEED_CLASS_USER_APPLY_OK" 1 "ESM_SPEED_CLASS_SYSTEM_APPLY_OK" 0 "ESM_SPEED_CLASS_STOPPED" ;
VAL_ 552 EPBR_learnedEpbConfig 11 "EPB_CONFIG_CT_MANDO" 10 "EPB_CONFIG_MODEL3_ZF" 9 "EPB_CONFIG_MODELS_CERAMIC" 8 "EPB_CONFIG_MODELY_PERFORMANCE_V2" 7 "EPB_CONFIG_MODEL3_PERFORMANCE_V2" 6 "EPB_CONFIG_MODELX_BASE" 5 "EPB_CONFIG_MODELY_PERFORMANCE" 4 "EPB_CONFIG_MODELY_BASE" 3 "EPB_CONFIG_MODELS_BASE" 2 "EPB_CONFIG_MODEL3_PERFORMANCE" 1 "EPB_CONFIG_MODEL3_BASE" 0 "EPB_CONFIG_UNKNOWN" ;
VAL_ 744 EPBR_systemStatus 8 "EPB_VEHICLE_STATUS_MISMATCH" 7 "EPB_VEHICLE_STATUS_FAULT_SECURE" 6 "EPB_VEHICLE_STATUS_FAULT" 5 "EPB_VEHICLE_STATUS_RELEASING" 4 "EPB_VEHICLE_STATUS_PARKING" 3 "EPB_VEHICLE_STATUS_DYNAMIC" 2 "EPB_VEHICLE_STATUS_PARKED" 1 "EPB_VEHICLE_STATUS_RELEASED" 0 "EPB_VEHICLE_STATUS_UNKNOWN" ;
VAL_ 744 EPBR_freeRollModeStatus 2 "EPB_FREE_ROLL_MODE_ENABLED" 1 "EPB_FREE_ROLL_MODE_AVAILABLE" 0 "EPB_FREE_ROLL_MODE_UNAVAILABLE" ;
VAL_ 744 EPBR_chimeRequest 4 "EPB_CHIME_REQUEST_ACTIVE_DECEL" 3 "EPB_CHIME_REQUEST_ABOUT_TO_ACTIVE_DECEL" 2 "EPB_CHIME_REQUEST_GPO" 1 "EPB_CHIME_REQUEST_GENERAL" 0 "EPB_CHIME_REQUEST_NONE" ;
VAL_ 744 EPBR_telltale 7 "EPB_TELLTALE_SNA" 4 "EPB_TELLTALE_LAMP_RED_FLASH" 3 "EPB_TELLTALE_LAMP_AMBER_ON" 2 "EPB_TELLTALE_LAMP_RED_ON" 1 "EPB_TELLTALE_LAMP_RED_PARKED" 0 "EPB_TELLTALE_LAMP_OFF" ;
VAL_ 744 EPBR_cdpRequest 1 "EPB_CDP_REQUESTED" 0 "EPB_CDP_NOT_REQUESTED" ;
VAL_ 744 EPBR_uiParkAvailable 2 "EPB_AVAIL_REAPPLIED" 1 "EPB_AVAIL_AVAILABLE" 0 "EPB_AVAIL_NOT_AVAILABLE" ;
VAL_ 744 EPBR_brakeDiscWipeRequest 3 "EPB_BRAKEDISCWIPE_REQUEST_SNA" 2 "EPB_BRAKEDISCWIPE_REQUEST_STRONG" 1 "EPB_BRAKEDISCWIPE_REQUEST_LIGHT" 0 "EPB_BRAKEDISCWIPE_REQUEST_NONE" ;
VAL_ 744 EPBR_uiWinchModeLvStatus 3 "EPB_LV_OK" 2 "EPB_LV_BLOCKED_TIMER_RUNNING" 1 "EPB_LV_BLOCKED_INPUT_VOLTAGE_LOW" 0 "EPB_LV_BLOCKED_BATTERY" ;
VAL_ 744 EPBR_autonomyBehavior 2 "DRIVERLESS_NO_TAKEOVER" 1 "DRIVERLESS_TAKEOVER" 0 "DRIVER" ;
VAL_ 1322 FC_alertID 321 "a321_FCAlertPlaceholder" 313 "a313_GB_inputVoltageRailOv" 312 "a312_GB_evseLimitsTimeout" 311 "a311_GB_battParamsTimeout" 310 "a310_GB_unused" 309 "a309_GB_unused" 308 "a308_GB_evseConLockTimeout" 307 "a307_GB_fcContOpenTimeout" 306 "a306_GB_vehReadyDeasserted" 305 "a305_GB_posRecogTimeout" 304 "a304_GB_unused" 303 "a303_GB_negRecogTimeout" 302 "a302_GB_unused" 301 "a301_GB_unused" 300 "a300_GB_unused" 299 "a299_GB_evseReadyTimeout" 298 "a298_GB_bmsCtrCloseTimeout" 297 "a297_GB_unused" 296 "a296_GB_invalidPilotTransitio" 295 "a295_GB_pilotRationality" 294 "a294_GB_unused" 293 "a293_GB_proxRationality" 292 "a292_GB_vehConLockTimeout" 291 "a291_GB_vehDataTimeout" 290 "a290_GB_pilotAcceptTimeout" 289 "a289_GB_proxTimeout" 288 "a288_GB_evseAbnormalStopReq" 287 "a287_GB_vehConnUnlocked" 286 "a286_GB_evseConnUnlocked" 285 "a285_GB_proxDisconnected" 284 "a284_GB_pcbTempHiFoldBk" 283 "a283_GB_posTempHiFoldBk" 282 "a282_GB_negTempHiFoldBk" 281 "a281_GB_evseOutOfService" 280 "a280_GB_retryLimitExceeded" 279 "a279_GB_evseOverCurrent" 278 "a278_GB_timeoutCCS" 277 "a277_GB_posToPcbDeltaLo" 276 "a276_GB_negToPcbDeltaLo" 275 "a275_GB_posToPcbDeltaHi" 274 "a274_GB_negToPcbDeltaHi" 273 "a273_GB_negToPosDeltaLo" 272 "a272_GB_negToPosDeltaHi" 271 "a271_GB_timeoutCRO" 270 "a270_GB_timeoutCML" 269 "a269_GB_timeoutCRM" 268 "a268_GB_pcb_OT" 267 "a267_GB_posPin_OT" 266 "a266_GB_negPin_OT" 265 "a265_GB_bmsIncompatible" 264 "a264_GB_timeoutCHM" 263 "a263_GB_hwProxTrip" 262 "a262_GB_evseRxBufOvf" 261 "a261_GB_evseTxBufOvf" 260 "a260_GB_vehRxBufOvf" 259 "a259_GB_vehTxBufOvf" 258 "a258_GB_evseMia" 257 "a257_GB_bmsMia" 193 "a193_FCAlertPlaceholder" 187 "a187_CA_evseConLockTimeout" 186 "a186_CA_fcContOpenTimeout" 185 "a185_CA_vehReadyDeasserted" 184 "a184_CA_evseBatMalfunc" 183 "a183_CA_evseBatIncompat" 182 "a182_CA_evseChrMalfunc" 181 "a181_CA_vRegBrownout" 180 "a180_CA_chargingProblem" 179 "a179_CA_startupProblem" 178 "a178_CA_evseStartTimeout" 177 "a177_CA_bmsCtrCloseTimeout" 176 "a176_CA_chargingBusTimeout" 175 "a175_CA_evseIsoTestTimeout" 174 "a174_CA_vehReadyTimeout" 173 "a173_CA_evseDataTimeout" 172 "a172_CA_ss2LowTimeout" 171 "a171_CA_vehConLockTimeout" 170 "a170_CA_vehDataTimeout" 169 "a169_CA_pilotAcceptTimeout" 168 "a168_CA_proxTimeout" 167 "a167_CA_isoVoltageLow" 166 "a166_CA_vehConnUnlocked" 165 "a165_CA_evseConnUnlocked" 164 "a164_CA_proxDisconnected" 163 "a163_CA_pcbTempHiFoldBk" 162 "a162_CA_evseTempHiFoldBk" 161 "a161_CA_vehTempHiFoldBk" 160 "a160_CA_ss2Deasserted" 159 "a159_CA_wdtExpired" 158 "a158_CA_evseOverCurrent" 157 "a157_CA_unused" 156 "a156_CA_flybackRunTimeout" 155 "a155_CA_evseToPcbDeltaLo" 154 "a154_CA_vehToPcbDeltaLo" 153 "a153_CA_evseToPcbDeltaHi" 152 "a152_CA_vehToPcbDeltaHi" 151 "a151_CA_vehToEvseDeltaLo" 150 "a150_CA_vehToEvseDeltaHi" 149 "a149_CA_pcb_UT" 148 "a148_CA_evseConn_UT" 147 "a147_CA_vehConn_UT" 146 "a146_CA_flybackBusLoadHi" 145 "a145_CA_flybackDataStale" 144 "a144_CA_flybackUnstable" 143 "a143_CA_pcb_OT" 142 "a142_CA_evseConn_OT" 141 "a141_CA_vehConn_OT" 140 "a140_CA_bmsIncompatible" 139 "a139_CA_ss2NotLow" 138 "a138_CA_hwProxTrip" 137 "a137_CA_evseRxBufOvf" 136 "a136_CA_evseTxBufOvf" 135 "a135_CA_vehRxBufOvf" 134 "a134_CA_vehTxBufOvf" 133 "a133_CA_evseMia" 132 "a132_CA_bmsMia" 131 "a131_CA_flyback_HW_OV" 130 "a130_CA_flyback_SW_OV" 129 "a129_CA_flyback_HW_OC" 0 "ALERT_DO_NOT_USE_ZERO" ;
VAL_ 1322 FC_alertType 1 "FAULT" 0 "WARNING" ;
VAL_ 1117 FC_evseBillingDataSelect 1 "1" 0 "0" ;
VAL_ 1334 FC_evseBilling2DataSelect 0 "FC_EVSEBILLING2_DATASELECT_0" ;
VAL_ 1334 FC_evseBillingEnergyHighRes 16777215 "SNA" ;
VAL_ 1310 FC_infoIndex 255 "END_FC" 27 "PART_NUM_3" 26 "PART_NUM_2" 25 "PART_NUM_1" 22 "VARIANT_CRC_FC" 20 "UDS_PROTOCOL_BOOTCRC_FC" 19 "VERSION_DEPRECATED_FC" 18 "BOOTLOADER_GITHASH_FC" 17 "APP_GITHASH_FC" 16 "SUBCOMPONENT_FC" 15 "BOOTLOADER_CRC_FC" 14 "BOOTLOADER_SVN_FC" 13 "APP_CRC_FC" 11 "PCBAID_ASSYID_USAGEID_FC" 10 "BUILD_HWID_COMPONENTID_FC" 9 "DEPRECATED_9_FC" 8 "DEPRECATED_8_FC" 7 "DEPRECATED_7_FC" 6 "DEPRECATED_6_FC" 5 "DEPRECATED_5_FC" 4 "DEPRECATED_4_FC" 3 "DEPRECATED_3_FC" 2 "DEPRECATED_2_FC" 1 "DEPRECATED_1_FC" 0 "DEPRECATED_0_FC" ;
VAL_ 1310 FC_infoBuildType 4 "INFO_MFG_BUILD_FC" 3 "INFO_TRACEABLE_CI_BUILD_FC" 2 "INFO_LOCAL_BUILD_FC" 1 "INFO_PLATFORM_BUILD_FC" 0 "INFO_UNKNOWN_BUILD_FC" ;
VAL_ 580 FC_powerLimit 8191 "SNA" ;
VAL_ 580 FC_currentLimit 8191 "SNA" ;
VAL_ 580 FC_maxVoltageLimit 8191 "SNA" ;
VAL_ 580 FC_minVoltageLimit 8191 "SNA" ;
VAL_ 702 FC_powerLimit_value -32768 "SNA" ;
VAL_ 702 FC_currentLimit_value -32768 "SNA" ;
VAL_ 702 FC_minVoltageLimit_value -32768 "SNA" ;
VAL_ 1345 FC_maxPowerLimit 8191 "SNA" ;
VAL_ 1345 FC_maxCurrentLimit 8191 "SNA" ;
VAL_ 1300 FC_serialDataSelect 2 "Mux2" 1 "Mux1" 0 "Mux0" ;
VAL_ 532 FC_statusCode 15 "FC_STATUS_NODATA" 14 "FC_STATUS_MALFUNCTION" 13 "FC_STATUS_NOTCOMPATIBLE" 7 "FC_STATUS_POST_OUT_OF_SERVICE" 6 "FC_STATUS_EXT_ISOACTIVE" 5 "FC_STATUS_INT_ISOACTIVE" 4 "FC_STATUS_DEPRECATED_4" 3 "FC_STATUS_DEPRECATED_3" 2 "FC_STATUS_UPDATE_IN_PROGRESS" 1 "FC_STATUS_READY" 0 "FC_STATUS_NOTREADY_SNA" ;
VAL_ 532 FC_type 7 "FC_TYPE_SNA" 6 "FC_TYPE_OTHER" 5 "FC_TYPE_MC_EVSE" 4 "FC_TYPE_COMBO" 3 "FC_TYPE_CC_EVSE" 2 "FC_TYPE_GB" 1 "FC_TYPE_CHADEMO" 0 "FC_TYPE_SUPERCHARGER" ;
VAL_ 532 FC_postID 3 "FC_POST_ID_SNA" 2 "FC_POST_ID_2" 1 "FC_POST_SLAVE" 0 "FC_POST_MASTER" ;
VAL_ 533 FC_externalIsolationResistance 255 "SNA" ;
VAL_ 535 FC_status3DataSelect 1 "Mux1" 0 "Mux0" ;
VAL_ 535 FC_class 2 "FC_CLASS_URBANCHARGER" 1 "FC_CLASS_SUPERCHARGER" 0 "FC_CLASS_SNA" ;
VAL_ 535 FC_brand 1 "TESLA" 0 "SNA" ;
VAL_ 535 FC_coolingType 3 "FC_COOLING_TYPE_IMMERSION" 2 "FC_COOLING_TYPE_CONVECTION" 1 "FC_COOLING_TYPE_LIQUID" 0 "FC_COOLING_TYPE_SNA" ;
VAL_ 535 FC_uiStopType 2 "FC_UI_STOP_TYPE_MOMENTARY" 1 "FC_UI_STOP_TYPE_TOGGLE" 0 "FC_UI_STOP_TYPE_SNA" ;
VAL_ 535 FC_generation 0 "GENERATION_SNA" ;
VAL_ 2047 GTW_deliveryStatus 1 "DELIVERED" 0 "NOT_DELIVERED" ;
VAL_ 2047 GTW_cabinPTCHeaterType 1 "NONE" 0 "BORGWARNER" ;
VAL_ 2047 GTW_rightHandDrive 1 "RIGHT" 0 "LEFT" ;
VAL_ 2047 GTW_rearLightType 2 "GLOBAL" 1 "EU_CN" 0 "NA" ;
VAL_ 2047 GTW_headlamps 2 "GLOBAL" 1 "PREMIUM" 0 "BASE" ;
VAL_ 2047 GTW_tireType 38 "HANKOOK_SUMMER_18" 37 "GITI_SUMMER_18" 36 "KUMHO_ALL_SEASON_18" 35 "GOODYEAR_ALL_SEASON_18" 34 "CONTI_SUMMER_19" 33 "BRIDGESTONE_ALL_SEASON_20" 32 "HANKOOK_ALL_SEASON_20" 31 "GOODYEAR_SUMMER_19" 30 "KUMHO_ALL_SEASON_19" 29 "HANKOOK_ALL_SEASON_21" 28 "PIRELLI_ALL_SEASON_19" 27 "GOODYEAR_ALL_SEASON_21" 26 "HANKOOK_ALL_SEASON_18" 25 "PIRELLI_ALL_SEASON_22" 24 "CONTI_SUMMER_22" 23 "CONTI_ALL_SEASON_20" 22 "MICHELIN_SUMMER_21" 21 "PIRELLI_SUMMER_20" 20 "PIRELLI_SUMMER_19" 19 "MICHELIN_ALL_SEASON_21" 18 "PIRELLI_SUMMER_21" 17 "GOODYEAR_ALL_SEASON_20" 16 "BRIDGESTONE_SUMMER_18" 7 "GOODYEAR_ALL_TERRAIN_20" 6 "PIRELLI_ALL_SEASON_20" 5 "MICHELIN_SUMMER_20" 4 "CONTI_ALL_SEASON_19" 3 "HANKOOK_SUMMER_19" 2 "MICHELIN_SUMMER_18" 1 "MICHELIN_ALL_SEASON_18" 0 "UNKNOWN" ;
VAL_ 2047 GTW_dasHw 5 "TESLA_AP4" 4 "TESLA_AP3" 3 "PARKER_PASCAL_2_5" ;
VAL_ 2047 GTW_brakeHWType 21 "HITACHI_P42_V2_MANDO_43MOC_LOW_DRAG" 20 "BREMBO_LARGE_P42_V2_MANDO_43MOC_LOW_DRAG" 18 "BREMBO_LARGE_P42_V2_BREMBO_44MOC_GA" 17 "HITACHI_P42_V2_MANDO_43MOC" 16 "BREMBO_P42LD_V2_MANDO_43MOC" 15 "BREMBO_P42LD_ZF_43MOC" 13 "BREMBO_P42_ZF_43MOC" 9 "BREMBO_P42_V2_MANDO_43MOC" 8 "BREMBO_LARGE_P42_V2_MANDO_43MOC" 7 "BREMBO_LARGE_P42_V2_BREMBO_LARGE_44MOC" 6 "BREMBO_LARGE_P42_V2_BREMBO_44MOC" 3 "BREMBO_LARGE_P42_BREMBO_LARGE_44MOC" 2 "BREMBO_LARGE_P42_MANDO_43MOC" 1 "BREMBO_LARGE_P42_BREMBO_44MOC" 0 "BREMBO_P42_MANDO_43MOC" ;
VAL_ 2047 GTW_restraintsHardwareType 239 "NA_NO_KAB_MYB" 238 "ROW_ECALL_E41_MYB" 237 "EU_ECALL_E41_MYB" 236 "NA_E41_MYB" 233 "NA_MYL" 232 "ECE_ECALL_PEDPRO_MYL" 89 "ROW_ECALL_PEDPRO_MYL" 88 "ROW_PEDPRO_MYB" 87 "ROW_PERF_ECALL_PEDPRO_MYB" 86 "EU_PERF_ECALL_PEDPRO_MYB" 85 "EU_ECALL_PEDPRO_MYB" 84 "ROW_ECALL_PEDPRO_MYB" 83 "ROW_MYB" 82 "ROW_ECALL_MYB" 81 "NA_MYB" ;
VAL_ 2047 GTW_drivetrainType 1 "AWD" 0 "RWD" ;
VAL_ 2047 GTW_radarHeaterType 1 "MODELY_BACKER_THIN_3M" 0 "NONE" ;
VAL_ 2047 GTW_exteriorTrimType 1 "SATIN_BLACK" 0 "STANDARD_CHROME" ;
VAL_ 2047 GTW_frontSeatHeaters 1 "KONGSBERG_LOW_POWER" 0 "NONE" ;
VAL_ 2047 GTW_rearSeatHeaters 1 "KONGSBERG_LOW_POWER" 0 "NONE" ;
VAL_ 2047 GTW_eCallAntennaHW 1 "MAIN_ANT_ONLY" 0 "BACKUP_OR_MAIN_ANT" ;
VAL_ 2047 GTW_homelinkType 1 "HOMELINK_V_OPT_2" 0 "NONE" ;
VAL_ 2047 GTW_vdcType 1 "TESLA_VDC" 0 "BOSCH_VDC" ;
VAL_ 2047 GTW_memoryMirrors 1 "SMR" 0 "NOT_INSTALLED" ;
VAL_ 2047 GTW_powerLiftgateType 2 "HUADE_REV1" 1 "TESLA_REV1" 0 "NOT_INSTALLED" ;
VAL_ 2047 GTW_lumbarECUType 10 "AEW_SINGLE_AXIS_DRIVER_ONLY_RHD" 9 "AEW_SINGLE_AXIS_DRIVER_ONLY_LHD" 8 "ND_DRIVER_ONLY_RHD" 7 "ND_DRIVER_ONLY_LHD" 6 "AEW_DRIVER_ONLY_RHD" 5 "AEW_DRIVER_ONLY_LHD" 4 "AEW" 3 "ALFMEIER_DRIVER_ONLY_RHD" 2 "ALFMEIER_DRIVER_ONLY_LHD" 1 "ALFMEIER" 0 "NONE" ;
VAL_ 2047 GTW_rearSeatHeaterType 3 "LEFT_RIGHT_ONLY_GENTHERM" 2 "NONE" 1 "LEFT_RIGHT_ONLY_KONGSBERG" ;
VAL_ 2047 GTW_auxParkLamps 3 "NONE" 2 "EU" 1 "NA_PREMIUM" 0 "NA_BASE" ;
VAL_ 2047 GTW_interiorCabinRadarType 1 "TESLA" 0 "NONE" ;
VAL_ 2047 GTW_hvacPanelVaneType 1 "CONVERGENT_V1" 0 "PARALLEL_V1" ;
VAL_ 2047 GTW_intakeAirFilterType 1 "HEPA" 0 "STANDARD" ;
VAL_ 2047 GTW_eBuckConfig 1 "DEV_BUCK" 0 "NONE" ;
VAL_ 2047 GTW_steeringHeaterEnabled 1 "ENABLED" 0 "DISABLED" ;
VAL_ 2047 GTW_activeHighBeam 1 "ACTIVE" 0 "NOT_ACTIVE" ;
VAL_ 2047 GTW_airbagCutoffSwitch 1 "CUTOFF_SWITCH_ENABLED" 0 "CUTOFF_SWITCH_DISABLED" ;
VAL_ 2047 GTW_intrusionSensorType 1 "VODAFONE" 0 "NOT_INSTALLED" ;
VAL_ 2047 GTW_spoilerType 1 "PASSIVE" 0 "NOT_INSTALLED" ;
VAL_ 2047 GTW_backupCameraType 1 "INTEGRATED_HEATER_V1" 0 "NO_HEATER" ;
VAL_ 2047 GTW_rearFogLamps 1 "INSTALLED" 0 "NOT_INSTALLED" ;
VAL_ 2047 GTW_roofType 1 "FIXED_GLASS" ;
VAL_ 2047 GTW_thirdRowSeatType 1 "FLAT_FOLD" 0 "NONE" ;
VAL_ 2047 GTW_autopilot 4 "BASIC" 3 "SELF_DRIVING" 2 "ENHANCED" 1 "HIGHWAY" 0 "NONE" ;
VAL_ 2047 GTW_superchargingAccess 2 "PAY_AS_YOU_GO" 1 "ALLOWED" 0 "NOT_ALLOWED" ;
VAL_ 2047 GTW_exteriorColor 20 "COASTAL_BLUE" 17 "MARINE_BLUE" 16 "SILKROAD_SILVER" 15 "DIAMOND_BLACK" 14 "GLACIER_BLUE" 13 "FROST_BLUE" 11 "STEALTH_GREY" 10 "ULTRA_RED" 9 "QUICKSILVER" 8 "ABYSS_BLUE" 7 "MIDNIGHT_CHERRY_RED" 6 "PEARL_WHITE" 5 "DEEP_BLUE" 3 "MIDNIGHT_SILVER" 2 "SILVER_METALLIC" 1 "SOLID_BLACK" 0 "RED_MULTICOAT" ;
VAL_ 2047 GTW_pedestrianWarningSound 2 "EXT_SPEAKER_V2" 1 "SPEAKER" 0 "NONE" ;
VAL_ 2047 GTW_steeringColumnUJointType 1 "C_SAMPLE_PHASING" ;
VAL_ 2047 GTW_bPillarNFCParam 1 "MODEL_Y" 0 "MODEL_3" ;
VAL_ 2047 GTW_interiorLighting 6 "FOOTWELL" 5 "FOOTWELL_RGB_IP" 4 "PREMIUM_WITH_RGB_IP_ONLY" 3 "PREMIUM_WITH_RGB" 2 "PREMIUM_NO_POCKET_LIGHT" 1 "PREMIUM" 0 "BASE" ;
VAL_ 2047 GTW_headlightLevelerType 2 "VIRTUAL_PITCH_SENSOR" 1 "GEN1" 0 "NONE" ;
VAL_ 2047 GTW_numberHVILNodes 3 "HVIL_NODES_3" 2 "HVIL_NODES_2" 0 "HVIL_NODES_0" ;
VAL_ 2047 GTW_mapRegion 13 "LA" 12 "IN" 11 "SE" 10 "MO" 9 "HK" 8 "ME" 7 "KR" 6 "TW" 5 "JP" 4 "AU" 3 "CN" 2 "NONE" 1 "EU" 0 "US" ;
VAL_ 2047 GTW_performancePackage 4 "BASE_2022" 3 "BASE_PLUS" 2 "BASE_2024" 1 "PERFORMANCE" 0 "BASE" ;
VAL_ 2047 GTW_chassisType 7 "MODEL_Y_LONG_WHEELBASE_CHASSIS_PATRONUS" 3 "MODEL_Y_CHASSIS" 2 "MODEL_3_CHASSIS" ;
VAL_ 2047 GTW_airSuspension 3 "COIL_ADAPTIVE_DAMPING" 0 "NONE" ;
VAL_ 2047 GTW_centerConsoleControllerType 2 "INSTALLED_NO_AIRWAVE" 1 "INSTALLED_V1" 0 "NONE" ;
VAL_ 2047 GTW_autopilotCameraType 1 "RGGB_CAMERAS" 0 "RCCB_CAMERAS" ;
VAL_ 2047 GTW_connectivityPackage 1 "PREMIUM" 0 "BASE" ;
VAL_ 2047 GTW_plcSupportType 2 "NATIVE_CHARGE_PORT" 1 "ONBOARD_ADAPTER" 0 "NONE" ;
VAL_ 2047 GTW_badgingVersion 2 "VERSION_2" 1 "VERSION_1" 0 "VERSION_0" ;
VAL_ 2047 GTW_packEnergy 2 "MR" 1 "LR" 0 "SR" ;
VAL_ 2047 GTW_frontSeatReclinerHardware 3 "LEFT_RIGHT_SEAT_REDUCED_RANGE" 2 "LEFT_SEAT_REDUCED_RANGE" 1 "RIGHT_SEAT_REDUCED_RANGE" 0 "STANDARD_RANGE" ;
VAL_ 2047 GTW_brakeLineSwitchType 1 "VC_ONLY" 0 "DI_VC_SHARED" ;
VAL_ 2047 GTW_espValveType 2 "VALVE_TYPE_2" 1 "VALVE_TYPE_1" 0 "UNKNOWN" ;
VAL_ 2047 GTW_softRange 4 "RANGE_260_MILES" 3 "RANGE_343_MILES" 2 "RANGE_93_MILES" 1 "RANGE_220_MILES" 0 "STANDARD" ;
VAL_ 2047 GTW_refrigerantType 2 "R1234YF" 1 "R134A" 0 "Default" ;
VAL_ 2047 GTW_wheelType 52 "UBERHELIX_20" 51 "GEMINI_19_DARK_STAGGERED" 50 "HELIX_V2_20_DARK" 48 "MACHINA_V2_19_STAGGERED" 47 "GLIDER_18_CAP_KIT" 46 "APERTURE_18" 41 "ARACHNID_V2_21" 40 "HELIX_V2_20" 39 "CROSSFLOW_19" 33 "WISHBONE_20_STAGGERED" 31 "HELIX_19" 30 "GLIDER_18" 27 "ZEROG_19_GUNPOWDER" 24 "PINWHEEL_REFRESH_18_CAP_KIT" 23 "UBERTURBINE_20_GUNPOWDER" 22 "PINWHEEL_REFRESH_18" 21 "STILETTO_REFRESH_19" 19 "ZEROG_20_GUNPOWDER" 18 "PINWHEEL_18_CAP_KIT" 14 "STILETTO_20_DARK_SQUARE" 5 "GEMINI_19_STAGGERED" 4 "GEMINI_19_SQUARE" 3 "STILETTO_20_DARK_STAGGERED" 2 "STILETTO_20" 1 "STILETTO_19" 0 "PINWHEEL_18" ;
VAL_ 2047 GTW_ptcControlMode 3 "SEQ_ROD_LIMITED" 2 "MESH_INSTALLED" 1 "SEQ_ROD" 0 "BASELINE" ;
VAL_ 2047 GTW_brakeActuationType 2 "ESP_DPB" 1 "IDB_RCU" 0 "ESP_IBST" ;
VAL_ 2047 GTW_secondRowSeatType 6 "TWO_SEATS_POWERED_RECLINE" 5 "FLAT_FOLD_V2" 4 "EASY_ENTRY_POWERED_RECLINE" 3 "POWERED_RECLINE" ;
VAL_ 2047 GTW_secondRowSeatMotorType 1 "KEIPER" 0 "SHB" ;
VAL_ 2047 GTW_eCallEnabled 2 "ENABLED_UI_SOS" 1 "ENABLED_OHC_SOS" 0 "DISABLED" ;
VAL_ 2047 GTW_parkAssistECUType 2 "NONE" 1 "TESLA" 0 "VALEO" ;
VAL_ 2047 GTW_passengerAirbagType 2 "EUROW" 1 "SAFETY_VENT" 0 "FULL_SUPPRESSION" ;
VAL_ 2047 GTW_forwardRadarHw 2 "NONE" 0 "CONTI_ARS410" ;
VAL_ 2047 GTW_frontSeatType 13 "PREMIUM_L_YANFENG_MINITILT_R_TESLA_MINITILT" 12 "PREMIUM_L_YANFENG_MINITILT_R_YANFENG_MINITILT" 11 "PREMIUM_L_YANFENG_MINITILT_R_YANFENG" 10 "PREMIUM_L_YANFENG_R_YANFENG_MINITILT" 9 "PREMIUM_L_TESLA_MINITILT_R_YANFENG_MINITILT" 8 "PREMIUM_L_TESLA_MINITILT_R_TESLA_MINITILT" 7 "PREMIUM_L_TESLA_MINITILT_R_TESLA" 6 "PREMIUM_L_TESLA_R_TESLA_MINITILT" 5 "PREMIUM_BROSE" 4 "PREMIUM_YANFENG" 3 "PREMIUM_L_TESLA_R_YANFENG" 2 "PREMIUM_L_YANFENG_R_TESLA" 1 "PREMIUM_TESLA" 0 "BASE_TESLA" ;
VAL_ 2047 GTW_secondRowDisplayType 1 "TYPE_1" 0 "NONE" ;
VAL_ 2047 GTW_wirelessPhoneChargerType 3 "FRONT_HIGH_POWER_UART" 1 "FRONT_LIN" 0 "NONE_OR_USB" ;
VAL_ 2047 GTW_ethernetTunerType 3 "HARMAN_GEN3" 2 "HIRSCHMANN" 1 "NONE" 0 "HARMAN" ;
VAL_ 2047 GTW_interiorTrimType 3 "WHITE_CONSOLE_2" 2 "BLACK_CONSOLE_2" 1 "WHITE" 0 "BLACK" ;
VAL_ 2047 GTW_gloveboxUSBType 2 "TSC_USB3_A_PLUS_BT" 1 "TSC_USB3_A" 0 "NOT_INSTALLED" ;
VAL_ 2047 GTW_coolantPumpType 5 "DUAL_MIX" 4 "DUAL_SAN_P4_LUB" 2 "DUAL_SAN_P4" 1 "SINGLE_PUMP_BATT" 0 "DUAL" ;
VAL_ 2047 GTW_epblHwType 8 "ZF" 5 "BREMBO_V2" 4 "BREMBO_V1" 2 "MANDO_V2" 1 "MANDO_V1" 0 "NOT_SET" ;
VAL_ 2047 GTW_epbrHwType 8 "ZF" 5 "BREMBO_V2" 4 "BREMBO_V1" 2 "MANDO_V2" 1 "MANDO_V1" 0 "NOT_SET" ;
VAL_ 2047 GTW_blowerMotorType 1 "DELTA" 0 "SHINANO" ;
VAL_ 2047 GTW_rearLeftBLEEndpointParameter 1 "VIVALDI_ANTENNA" 0 "NONE" ;
VAL_ 2047 GTW_powerMirrorFoldType 1 "TYPE_1" 0 "NOT_INSTALLED" ;
VAL_ 2047 GTW_frontUsbHubType 4 "NO_DATA" 0 "2" ;
VAL_ 2047 GTW_superManifoldType 2 "TYPE2" 1 "TYPE1" 0 "TYPE0" ;
VAL_ 2047 GTW_rcmLocation 0 "CENTER_CONSOLE" ;
VAL_ 2047 GTW_autopilotExteriorCameraType 1 "IMX00N" 0 "DEFAULT_FOR_APHW" ;
VAL_ 2047 GTW_interiorCamBeautyCoverType 2 "PITCHED_DOWN" 1 "PITCHED_UP" 0 "STANDARD" ;
VAL_ 2047 GTW_sirenType 1 "VODAPHONE_IF_INTRUSION" 0 "NONE" ;
VAL_ 2047 GTW_hornType 1 "EXT_SPEAKER_V2" 0 "TRUMPET" ;
VAL_ 2047 GTW_passengerTrackMotorType 1 "L_AND_V" 0 "INSTALLED_DEFAULT" ;
VAL_ 2047 GTW_steeringColumnMotorType 3 "NEXTEER" 2 "BOSCH_COMMON_TO_JE" 1 "JE" 0 "BOSCH" ;
VAL_ 2047 GTW_refrigACLineType 2 "CONTI_LIMITED" 1 "SAAA_LIMITED" 0 "UNLIMITED" ;
VAL_ 2047 GTW_refrigFilterType 2 "BLOCKED_V2" 1 "BLOCKED_V1" 0 "UNBLOCKED" ;
VAL_ 2047 GTW_diBurnInType 1 "ENABLED_V1" 0 "NONE" ;
VAL_ 2047 GTW_specialBadgingType 2 "LAUNCH_SERIES" 0 "NONE" ;
VAL_ 2047 GTW_chassisSubType 4 "MARKET_VARIANT_2" 3 "TRIM_DEVIATION_1" 2 "PERFORMANCE" 1 "BASE" 0 "UNKNOWN" ;
VAL_ 2047 GTW_towPackage 2 "TESLA_REV2" 1 "TESLA_REV1" 0 "NONE" ;
VAL_ 2047 GTW_refrigLccType 1 "LCCR" 0 "LCC" ;
VAL_ 2047 GTW_restraintControlsType 1 "TESLA" 0 "BOSCH" ;
VAL_ 2047 GTW_caliperColorType 2 "RED" 1 "GREY" 0 "UNKNOWN" ;
VAL_ 2047 GTW_wiperMotorType 1 "SHB" 0 "NOT_UPDATEABLE" ;
VAL_ 2047 GTW_frontOverheadConsoleType 3 "KOSTAL" 2 "PREH" 1 "BITRON" 0 "VALEO" ;
VAL_ 2047 GTW_shifterType 1 "DISPLAY" 0 "STALK" ;
VAL_ 2047 GTW_compressorType 10 "SANDEN_V4_1" 8 "SANDEN_V4" 7 "SANDEN_V3" 6 "SANDEN_V1_1" 5 "SANDEN_V2" 4 "DENSO_11K_COP1_ENABLED" 3 "SANDEN" 2 "DENSO_41CC_11K" 1 "DENSO_41CC_8K" 0 "HANON_33CC" ;
VAL_ 2047 GTW_twelveVBatteryType 3 "TESLA_16V_LI_ION" 2 "CATL_LI_ION" 1 "CLARIOS_B24_FLOODED" 0 "ATLASBX_B24_FLOODED" ;
VAL_ 2047 GTW_efuseSWConfig 3 "ALL_ENABLED" 2 "SQUARE_ENABLED" 1 "ROUND_ENABLED" 0 "DISABLED" ;
VAL_ 2047 GTW_tollCollectionModuleType 1 "WANJI_V1" 0 "NONE" ;
VAL_ 2047 GTW_bleEndpointUpdateMethod 1 "BOOTLOADER_UPDATE" ;
VAL_ 2047 GTW_steeringWheelControllerType 5 "DUAL_TESLA_GEN5" 2 "DUAL_KOSTAL" 1 "DUAL_PREH" ;
VAL_ 2047 GTW_frontSeatVentilationEnabled 1 "ENABLED" 0 "DISABLED" ;
VAL_ 2047 GTW_gloveboxActuatorType 2 "ELECTROMAGNET" 1 "SMA" 0 "SOLENOID" ;
VAL_ 2047 GTW_epasType 8 "THYSSENKRUPP_CGR65" 7 "MANDO_CGR65" 6 "THYSSENKRUPP_VGR69" 5 "MANDO_CGR69_SINGLE_ECU" 4 "MANDO_CGR69" 3 "MANDO_VGR69_GEN3_SINGLE_ECU" 0 "MANDO_VGR69_GEN3" ;
VAL_ 2047 GTW_homologationRegionOverride 2 "MX_UNECE" 1 "KR_UNECE" 0 "DEFAULT_FOR_COUNTRY_CODE" ;
VAL_ 2047 GTW_windowCommandsPermissionType 2 "US_FMVSS_S6" 1 "US_FMVSS_S4" 0 "ROW_OR_US_FMVSS_S5" ;
VAL_ 2047 GTW_headlightStepperStallDetectM 1 "ENABLED" 0 "DISABLED" ;
VAL_ 2047 GTW_rgbInteriorLightingEnabled 2 "ALL_COLORS" 1 "WHITE_ONLY" 0 "DISABLED_OR_NA" ;
VAL_ 2047 GTW_windshieldWiperHeaterType 1 "TYPE_1" 0 "NOT_INSTALLED" ;
VAL_ 2047 GTW_thirdRowSeatReclinerType 1 "POWERED_SHB" 0 "MANUAL_OR_NA" ;
VAL_ 2047 GTW_driveInterfaceType 1 "EXTERNAL" 0 "COMBINED" ;
VAL_ 2047 GTW_efficiencyPackage 42 "MY_2026_US" 39 "MY_2025_CN_PLUS" 38 "MY_2026_M53" 34 "MY_STANDARD_2026" 33 "MY_REFRESH_2025_CN_ALL_US_LR_RWD" 32 "MY_REFRESH_2025_ROW" 24 "MY_2024_GFSH_EXPORT_NA_SR_RWD" 23 "MY_2024C" 20 "MY_2023_SR_RWD" 16 "MY_2024" 15 "MY_2023_GFSH_EXPORT_NA" 12 "MY_RWD_EU_2022" 11 "MY_SR_PLUS_2022_Q1_TX" 9 "MY_SR_PLUS_2021_Q3_GFSH" 7 "MY_2021" 5 "MY_2020" 0 "DEFAULT" ;
VAL_ 2047 GTW_visorLightType 1 "DIMMABLE_TYPE_1" 0 "NON_DIMMABLE" ;
VAL_ 2047 GTW_gnssAntennaType 2 "GEN2_WITH_METAL_INSERT" 1 "GEN2_NO_METAL_INSERT" 0 "NA_OR_GEN1" ;
VAL_ 2047 GTW_airDistributionBoxType 1 "TYPE_1" 0 "NONE" ;
VAL_ 2047 GTW_frontSeatHeatersEnabled 1 "ENABLED" 0 "DISABLED" ;
VAL_ 2047 GTW_windshieldWiperHeaterEnabled 1 "ENABLED_OR_NA" 0 "DISABLED" ;
VAL_ 2047 GTW_alcoholInterlockType 1 "TYPE_1" 0 "NONE" ;
VAL_ 2047 GTW_fasciaType 8 "E41_BAYBERRY" 4 "PERFORMANCE_BAYBERRY" 3 "BASE_BAYBERRY" 0 "ORIGINAL" ;
VAL_ 2047 GTW_powerSteeringColumn 1 "TK" 0 "NOT_INSTALLED" ;
VAL_ 2047 GTW_frontSeatHeaterType 1 "GENTHERM" 0 "KONGSBERG" ;
VAL_ 2047 GTW_softPerformanceLimit 6 "LIMIT_230_KW" 4 "LIMIT_110_MPH" 2 "LIMIT_110_KW" 1 "LIMIT_160_KW" 0 "NONE" ;
VAL_ 2047 GTW_gsrFeatureType 2 "TYPE_2_GSR" 0 "NONE" ;
VAL_ 2047 GTW_immersiveAudio 2 "PREMIUM" 1 "BASE" 0 "DISABLED" ;
VAL_ 2047 GTW_frontSeatVentilationType 1 "TYPE_1" 0 "NONE" ;
VAL_ 2047 GTW_passengerOccupancySensorType 4 "NONE" 1 "RESISTIVE_PAD" 0 "OCS" ;
VAL_ 2047 GTW_packPerformanceDeviation 5 "PACK_POWER_DEVIATION_2" 4 "PACK_MASS_DEVIATION_2" 3 "PACK_STRUCTURAL_DEVIATION_1" 2 "PACK_POWER_DEVIATION_1" 1 "PACK_MASS_DEVIATION_1" 0 "NO_DEVIATION" ;
VAL_ 2047 GTW_pressurePadType 3 "BOSCH_LINDA_300N" 2 "BOSCH_B2_400N" 1 "BOSCH_B2_300N" 0 "NONE" ;
VAL_ 2047 GTW_frontFogLamps 1 "INSTALLED" 0 "NOT_INSTALLED" ;
VAL_ 2047 GTW_driverOccupancySensorType 1 "NONE" 0 "RESISTIVE_PAD" ;
VAL_ 2047 GTW_audioType 4 "ESSENTIAL_WITH_COMMODITY100" 3 "ESSENTIAL" 1 "PREMIUM" 0 "BASE" ;
VAL_ 2047 GTW_thighExtenderType 1 "YANFENG" 0 "NONE" ;
VAL_ 2047 GTW_occupancyClassificationFeatu 1 "TESLA_CABIN_RADAR" 0 "DISCRETE_SENSOR_OR_NA" ;
VAL_ 2047 GTW_frontControllerArchitectureT 1 "BETA_TYPE" 0 "ALPHA_TYPE" ;
VAL_ 2047 GTW_domeLightType 3 "2R_3R" 2 "2R" ;
VAL_ 2047 GTW_tpmsType 2 "INDIRECT" 1 "TESLA_BLE" 0 "CONTI_2" ;
VAL_ 2047 GTW_authenticationEndpointLayout 6 "M3_LAYOUT_3" 5 "MY_LAYOUT_3" 2 "MY_LAYOUT_2" 1 "M3_LAYOUT_2" 0 "LAYOUT_1" ;
VAL_ 2047 GTW_socSleepOverride 2 "FORCE_SHALLOW" 1 "FORCE_S3" 0 "PN_DERIVED" ;
VAL_ 2047 GTW_r79BehaviorOverride 1 "R79_ENABLED" 0 "NO_OVERRIDE" ;
VAL_ 2047 GTW_steeringHeaterType 7 "YF_V2" 4 "ZF_ROUND" 0 "NONE" ;
VAL_ 2047 GTW_narrowWipingSupported 1 "SUPPORTED" 0 "NOT_SUPPORTED" ;
VAL_ 2047 GTW_frontSeatHeaterGridType 1 "LARGER_SURFACE_AREA" 0 "STANDARD" ;
VAL_ 2047 GTW_frontSeatSideSwitchType 1 "NONE" 0 "STANDARD" ;
VAL_ 2047 GTW_sohRegulatoryStatus 1 "REGULATED_SOH" 0 "NON_REGULATED_SOH" ;
VAL_ 2047 GTW_passengerTiltMotorType 2 "MINITILT" 1 "NONE" 0 "INSTALLED_DEFAULT" ;
VAL_ 2047 GTW_frunkInteriorReleaseType 1 "NOT_INSTALLED" 0 "TYPE_1" ;
VAL_ 2047 GTW_m3yBusArchitecture 2 "PRIVATE_TORQUE_CHASSIS" 1 "PRIVATE_TORQUE" 0 "PUBLIC_TORQUE" ;
VAL_ 2047 GTW_passengerLiftMotorType 2 "BOSCH_KEIPER_COMMON" 1 "NONE" 0 "INSTALLED_DEFAULT" ;
VAL_ 2047 GTW_interiorUpperTrimType 1 "MAMMOTH_BLACK" 0 "POLAR_GREY" ;
VAL_ 2047 GTW_blindSpotIndicatorLightType 2 "INSTALLED_TYPE_2" 1 "INSTALLED_TYPE_1" 0 "NOT_INSTALLED" ;
VAL_ 2047 GTW_wiperMotorAsicType 2 "TYPE_2" 1 "TYPE_1" 0 "UNKNOWN_OR_NA" ;
VAL_ 2047 GTW_hvacCaseDoorType 1 "FLAT_EDGE" 0 "SERRATED_EDGE" ;
VAL_ 2047 GTW_occupancyDetectionSourceRequ 1 "TESLA_CABIN_RADAR" 0 "DISCRETE_SENSOR_OR_NA" ;
VAL_ 2047 GTW_rduCableType 1 "COPPER" 0 "ALUMINUM" ;
VAL_ 2047 GTW_parkTelltaleBehaviorType 1 "TYPE_1_REVISED_BEHAVIOR" 0 "LEGACY_BEHAVIOR" ;
VAL_ 2047 GTW_numberKeyCardsPairedInFactor 2 "2" 1 "1" ;
VAL_ 2047 GTW_secondRowSeatVentilationType 1 "TWO_SEATS_GENTHERM" 0 "NONE" ;
VAL_ 2047 GTW_thirdRowSeatHeaterType 1 "TWO_SEATS_KONGSBERG" 0 "NONE" ;
VAL_ 2047 GTW_interiorCameraType 2 "VD1942" 1 "VD6763" 0 "AR0136" ;
VAL_ 2047 GTW_frontFasciaCameraType 2 "IMX00N" 1 "IMX963" 0 "NONE" ;
VAL_ 2047 GTW_interiorCamFanType 3 "NIDEC" 2 "DELTA_FDB" 0 "NONE" ;
VAL_ 2047 GTW_puddleLampType 2 "INSTALLED_1R_ONLY_TYPE_1" 1 "INSTALLED_TYPE_1" 0 "NOT_INSTALLED" ;
VAL_ 2047 GTW_solarLensType 1 "PEGATRON" 0 "BCS" ;
VAL_ 2047 GTW_liftgateGeometryType 2 "TYPE_2" 1 "TYPE_1" 0 "DEFAULT" ;
VAL_ 2047 GTW_repeaterAeroRibType 4 "RETROFIT_OPTIMIZED" 3 "OPTIMIZED" 0 "UNOPTIMIZED" ;
VAL_ 2047 GTW_highTipForceWiperArmsType 1 "INSTALLED_TYPE_1" 0 "NOT_INSTALLED" ;
VAL_ 2047 GTW_rcmUndersideAbuseZThreshold 7 "threshold7" 6 "threshold6" 5 "threshold5" 4 "threshold4" 3 "threshold3" 2 "threshold2" 1 "threshold1" 0 "threshold0" ;
VAL_ 2047 GTW_rcmUndersideAbuseYThreshold 7 "threshold7" 6 "threshold6" 5 "threshold5" 4 "threshold4" 3 "threshold3" 2 "threshold2" 1 "threshold1" 0 "threshold0" ;
VAL_ 2047 GTW_rcmUndersideAbuseWindow 3 "window3" 2 "window2" 1 "window1" 0 "window0" ;
VAL_ 2047 GTW_uhfChargePortEnabled 1 "DISABLED" 0 "ENABLED" ;
VAL_ 2047 GTW_automaticFeatureResetPackage 1 "TYPE_1" 0 "NONE" ;
VAL_ 2047 GTW_autopilotFeaturePackage 1 "TACC_AND_FSD_ONLY" 0 "LEGACY_AND_FSD" ;
VAL_ 2047 GTW_doorLatchType 1 "SELF_TESTABLE" 0 "DIGITAL" ;
VAL_ 2047 GTW_headlinerMaterialType 2 "POLYURETHANE_FIBERGLASS_LIGHT" 1 "POLYURETHANE_FIBERGLASS" 0 "POLYCARBONATE_ABS" ;
VAL_ 2047 GTW_glareShieldHeaterType 1 "TYPE_1" 0 "NONE" ;
VAL_ 2047 GTW_rearLightHardwareVariant 2 "V3" 1 "V2" 0 "V1" ;
VAL_ 2047 GTW_fasciaHarnessCleanPointType 2 "POST_CLEANPOINT" 1 "PRE_CLEANPOINT" 0 "UNKOWN" ;
VAL_ 2047 GTW_epasSubType 1 "GEN4" 0 "GEN3_OR_NA" ;
VAL_ 2047 GTW_wiperSupplyChainOrigin 2 "NA_SUPPLY_CHAIN" 1 "CN_SUPPLY_CHAIN" 0 "UNKNOWN_OR_SNA" ;
VAL_ 2047 GTW_windowPinchParameterType 2 "TYPE_2" 1 "TYPE_1" 0 "DEFAULT" ;
VAL_ 2047 GTW_badgingMaterialType 1 "BLACK_MATTE" 0 "CHROME_SILVER" ;
VAL_ 2047 GTW_mRecordVersion 1 "VER_2025" 0 "VER_2016_OR_NA" ;
VAL_ 2047 GTW_tcuType 1 "5G" 0 "4G" ;
VAL_ 2047 GTW_carbComplianceBehaviorType 1 "ACCII_2026_BEHAVIOR" 0 "NONE" ;
VAL_ 2047 GTW_indirectTPMSCalibrationType 4 "EXPERIMENTAL_V2" 3 "EXPERIMENTAL_V1_EU" 2 "EXPERIMENTAL_V1" 1 "STANDARD_EU" 0 "STANDARD" ;
VAL_ 2047 GTW_v2xEnabled 1 "DISABLED" 0 "ENABLED" ;
VAL_ 2047 GTW_liftgateStrutType 1 "TYPE_1" 0 "DEFAULT" ;
VAL_ 2047 GTW_exteriorMicrophoneType 1 "TWO_EXT_MICS" 0 "NONE" ;
VAL_ 2047 GTW_contactorPowerSource 1 "VCFRONT" 0 "VCRIGHT" ;
VAL_ 2047 GTW_roofGlassType 4 "AG3" 3 "UNCOATED" 2 "NONE" 1 "TSA5_NOPET" 0 "TSA3_PET" ;
VAL_ 2047 GTW_pedalMapNameOverride 1 "CHILL_STANDARD" 0 "NO_OVERRIDE" ;
VAL_ 1638 GTW_diagLevel 100 "LEVEL_NORMAL_OPERATION" 80 "LEVEL_PARK" 70 "LEVEL_PARK_ROBOTAXI" 50 "LEVEL_SERVICE_DRIVE" 25 "LEVEL_SERVICE" 10 "LEVEL_DIAG_LINK_ACTIVE" 0 "LEVEL_FACTORY" ;
VAL_ 840 GTW_vehicleVersionMatchStatus 2 "MATCHED" 1 "MISMATCHED" 0 "NOT_CALCULATED_YET" ;
VAL_ 840 GTW_hwtype 3 "TRAVEO2" 2 "SPC58" 1 "MPC57" 0 "SNA" ;
VAL_ 840 GTW_jcanProductName 11 "SEMITRUCKV2" 10 "GOLDENSNITCH" 8 "BAYBERRY" 7 "CYBERTRUCK" 6 "POPPYSEED" 5 "SEMITRUCK" 4 "TAMARIND" 3 "LYCHEE" 2 "MODELY" 1 "MODEL3" 0 "SNA" ;
VAL_ 840 GTW_touchcoreOsType 1 "GTW_OS_RT" 0 "GTW_OS_FREERTOS" ;
VAL_ 840 GTW_sentryModeState 6 "SNA" 5 "QUIET" 4 "PANIC" 3 "AWARE" 2 "ARMED" 1 "IDLE" 0 "OFF" ;
VAL_ 840 GTW_secureBootEnabled 1 "TRUE" 0 "FALSE" ;
VAL_ 840 GTW_socSleepType 2 "SHALLOW" 1 "S3" 0 "SNA" ;
VAL_ 840 GTW_resetType 8 "OTHER" 7 "TOUCHCORE_WATCHDOG" 6 "CANCORE_WATCHDOG" 5 "MAINCORE_WATCHDOG" 4 "WAKE" 3 "BUTTON" 2 "SOFTWARE" 1 "POR" 0 "SNA" ;
VAL_ 1005 GTW_peripheralConfirmedUpdateNee 3 "UPDATE_CONDITIONS_NOT_CORRECT" 2 "UPDATE_NOT_NEEDED" 1 "UPDATE_NEEDED" 0 "UNKNOWN" ;
VAL_ 1112 GTW_nmKeepAwakeReason 15 "GTW_KEEPAWAKE_REASON_TBD" 7 "GTW_KEEPAWAKE_REASON_TCU_TC10_VERSION_UNSUPPORTED" 6 "GTW_KEEPAWAKE_REASON_TCU_TC10_VERSION_CHECK" 5 "GTW_KEEPAWAKE_REASON_EGGLEFT_LINK_DOWN" 4 "GTW_KEEPAWAKE_REASON_URGENT_TRANSMIT_ALERT" 3 "GTW_KEEPAWAKE_REASON_FCSM_ACTIVE" 2 "GTW_KEEPAWAKE_REASON_GSM_RI" 1 "GTW_KEEPAWAKE_REASON_UI_SCHEDULED" 0 "GTW_KEEPAWAKE_REASON_NONE_SNA" ;
VAL_ 1112 GTW_nmWakeUpReason 17 "GTW_WAKEUP_REASON_TCU_TC10_VERSION_CHECK" 16 "GTW_WAKEUP_REASON_EGGLEFT_LINK_DOWN" 15 "GTW_WAKEUP_REASON_RCMPRIVATE_CAN" 14 "GTW_WAKEUP_REASON_VCLEFT" 13 "GTW_WAKEUP_REASON_LOOP" 12 "GTW_WAKEUP_REASON_DISPLAY_TAP" 11 "GTW_WAKEUP_REASON_URGENT_TRANSMIT_ALERT" 10 "GTW_WAKEUP_REASON_BDY_CAN" 9 "GTW_WAKEUP_REASON_PT_CAN" 8 "GTW_WAKEUP_REASON_UI_SCHEDULED" 7 "GTW_WAKEUP_REASON_RTC_ALARM" 6 "GTW_WAKEUP_REASON_VCFRONT" 5 "GTW_WAKEUP_REASON_VEH_CAN" 4 "GTW_WAKEUP_REASON_ETH_CAN" 3 "GTW_WAKEUP_REASON_CH_CAN" 2 "GTW_WAKEUP_REASON_GSM_RI" 1 "GTW_WAKEUP_REASON_RESET" 0 "GTW_WAKEUP_REASON_NONE" ;
VAL_ 1112 GTW_ethKeepAwakeReason 3 "TCU_TC10_VERSION_UNSUPPORTED" 2 "TCU_TC10_VERSION_CHECK" 1 "URGENT_TRANSMIT_ALERT" 0 "NONE_SNA" ;
VAL_ 1112 GTW_nmDebugWakeUp 2147483648 "WKPU_31" 1073741824 "WKPU_30" 536870912 "WKPU_29" 268435456 "WKPU_28" 134217728 "WKPU_27" 67108864 "WKPU_26" 33554432 "WKPU_25" 16777216 "WKPU_24" 8388608 "WKPU_23" 4194304 "WKPU_22" 2097152 "WKPU_21" 1048576 "WKPU_20" 524288 "WKPU_19" 262144 "WKPU_18" 131072 "WKPU_17" 65536 "WKPU_16" 32768 "WKPU_15" 16384 "WKPU_14" 8192 "WKPU_13" 4096 "WKPU_12" 2048 "WKPU_11" 1024 "WKPU_10" 512 "WKPU_9" 256 "WKPU_8" 128 "WKPU_7" 64 "WKPU_6" 32 "WKPU_5" 16 "WKPU_4" 8 "WKPU_3" 4 "WKPU_2" 2 "WKPU_1" 1 "WKPU_0" 0 "WKPU_NONE" ;
VAL_ 1650 VC_hcmlInfoIndex 9 "END" 8 "ECULESS_MISC" 7 "ECULESS_BOOST" 6 "ECULESS_LED_VOLTAGES" 5 "ECULESS_IC700_SM" 4 "ECULESS_IC600_DRL_TURN" 3 "ECULESS_IC500_LB" 2 "ECULESS_IC400_HB" 1 "HCML_ASSEMBLY_PCBA_USAGE_ID" 0 "HCML_BUILD_CONFIG_ID_LMM_VARIANT" ;
VAL_ 1650 VC_leftHeadlampLMMVariant 2 "LMM_VARIANT_LMM4" 1 "LMM_VARIANT_NOT_LMM4_OR_UNKNOWN" 0 "LMM_VARIANT_SNA" ;
VAL_ 1980 VC_hcmrInfoIndex 9 "END" 8 "ECULESS_MISC" 7 "ECULESS_BOOST" 6 "ECULESS_LED_VOLTAGES" 5 "ECULESS_IC700_SM" 4 "ECULESS_IC600_DRL_TURN" 3 "ECULESS_IC500_LB" 2 "ECULESS_IC400_HB" 1 "HCMR_ASSEMBLY_PCBA_USAGE_ID" 0 "HCMR_BUILD_CONFIG_ID_LMM_VARIANT" ;
VAL_ 1980 VC_rightHeadlampLMMVariant 2 "LMM_VARIANT_LMM4" 1 "LMM_VARIANT_NOT_LMM4_OR_UNKNOWN" 0 "LMM_VARIANT_SNA" ;
